VERSION ""

NS_ :

BS_:

BU_: PowertrainControlModule AtmosphericSensor SafetyRestraintSystem2 Aftertreatment_2_GasOutlet Aftertreatment_2_GasIntake DieselParticulateFilterControl Turbocharger SafetyRestraintSystem1 CabDisplay2 Aftertreatment_1_GasOutlet Aftertreatment_1_GasIntake OnBoardDataLogger OffBoardDiagnosticTool2 OffBoardDiagnosticTool1 FileServer ParkingBrakeController SeatController2 FanDriveController SteeringColumnUnit CommunicationUnitRadio CommunicationUnitSatellite CommunicationUnitCellular PropulsionBatteryCharger ChassisController2 ChassisController1 EngineValveControl AuxiliaryHeater2 AuxiliaryHeater1 ClutchUnit RampControl InformationSystem1 SuspensionSystemController2 OilSensor VehicleDynamicStability ExhaustEmissionController TransmissionDisplay2 TransmissionDisplay1 ClimateControl2 WaterPumpController RearAxleSteeringController LightingOperatorControl SeatController1 IgnitionController2 IgnitionController1 TirePressureController CabController2 CabController1 PneumaticSystemController SuspensionSystemController1 HydraulicPumpController EnduranceBrakingSystem RetarderExhaustEngine2 OnBoardDiagnosticUnit HeadwayController RetarderExhaustEngine1 CabDisplay1 ManagementComputer VirtualTerminal OffVehicleGateway PowerTakeOffFront HitchControl AuxiliaryValveControl BodyController TractorTrailerBridge1 StarterSystem ElectricalSystem VehicleSecurity VehicleNavigation AerodynamicControl ElectricalChargingSystem ClimateControl1 TripRecorder InstrumentCluster SuspensionDriveAxle2 SuspensionDriveAxle1 SuspensionSteerAxle SteeringController FuelSystem CruiseControl RetarderDriveline RetarderEngine BrakesDriveAxle2 BrakesDriveAxle1 BrakesSystemController BrakesSteerAxle AxleDrive2 AxleDrive1 AxleSteering PowerTakeOff ShiftConsoleSecondary ShiftConsolePrimary Transmission2 Transmission1 Engine2 Engine1
VAL_TABLE_ FMI 22 "Data Drifted Low" 21 "Data Drifted High" 20 "Received Network Data In Error" 0 "Above normal (most severe)" 1 "Below normal (most severe)" 2 "Data erratic" 3 "Voltage above normal" 4 "Voltage below normal" 5 "Current below normal" 6 "Current above normal" 7 "Mechanical system not responding" 8 "Abnormal frequency" 9 "Abnormal update rate" 10 "Abnormal rate of change" 11 "Root cause not known" 12 "Bad intelligent device" 13 "Out of calibration" 14 "Special intstructions" 15 "Above normal (least severe)" 16 "Above normal (moderately severe)" 17 "Below normal (least severe)" 18 "Below normal (moderately severe)" 19 "Received network data in error" 31 "Condition Exists" ;
VAL_TABLE_ TireLocation_MUX 51 "TirePress_33_MUX_51" 50 "TirePress_32_MUX_50" 49 "TirePress_31_MUX_49" 48 "TirePress_30_MUX_48" 35 "TirePress_23_MUX_35" 34 "TirePress_22_MUX_34" 33 "TirePress_21_MUX_33" 32 "TirePress_20_MUX_32" 19 "TirePress_13_MUX_19" 18 "TirePress_12_MUX_18" 17 "TirePress_11_MUX_17" 16 "TirePress_10_MUX_16" 1 "TirePress_01_MUX_1" 0 "TirePress_00_MUX_0" ;

BO_ 3221225472 VECTOR__INDEPENDENT_SIG_MSG: 0 Vector__XXX
 SG_ NumberOfMembersInWorkingSet : 0|8@1+ (1,0) [0|0] "" Vector__XXX
 SG_ SourceAddress : 0|8@1+ (1,0) [0|0] "" Vector__XXX
 SG_ NncntnuslyMonitoredSystemsStatus : 0|16@1+ (1,0) [0|0] "" Vector__XXX
 SG_ NncntnslyMonitoredSystemsSupport : 0|16@1+ (1,0) [0|0] "" Vector__XXX
 SG_ CntnslyMntrdSystmsSupport_Status : 0|8@1+ (1,0) [0|0] "" Vector__XXX
 SG_ AETCTorqueValue : 0|16@1+ (1,0) [0|64255] "Nm" Vector__XXX
 SG_ TrailerWeight : 0|16@1+ (2,0) [0|128510] "kg" Vector__XXX
 SG_ ReferenceTirePressSetting : 0|8@1+ (8,0) [0|2000] "kPa" Vector__XXX
 SG_ ReferenceTirePress : 0|8@1+ (8,0) [0|2000] "kPa" Vector__XXX
 SG_ TirePressThresholdDetection : 0|3@1+ (1,0) [0|7] "" Vector__XXX
 SG_ TireAirLeakageRate : 0|16@1+ (0.1,0) [0|6425.5] "Pa/s" Vector__XXX
 SG_ CTIWheelEndElectricalFault : 0|2@1+ (1,0) [0|3] "" Vector__XXX
 SG_ CTITireStatus : 0|2@1+ (1,0) [0|3] "" Vector__XXX
 SG_ CTIWheelSensorStatus : 0|2@1+ (1,0) [0|3] "" Vector__XXX
 SG_ TireTemp : 0|16@1+ (0.03125,-273) [-273|1734.96875] "deg C" Vector__XXX
 SG_ TirePress : 0|8@1+ (4,0) [0|1000] "kPa" Vector__XXX
 SG_ EngTurningGearEngaged : 0|2@1+ (1,0) [0|3] "" Vector__XXX
 SG_ AETCSpeedValue : 0|16@1+ (0.125,0) [0|8031.875] "rpm" Vector__XXX
 SG_ TimeBetweenRegens : 0|16@1+ (6,0) [0|385530] "s" Vector__XXX
 SG_ ActiveAccumulationTime : 0|16@1+ (6,0) [0|385530] "s" Vector__XXX
 SG_ RegenSt : 0|4@1+ (1,0) [0|15] "" Vector__XXX
 SG_ RegenStatus : 0|2@1+ (1,0) [0|3] "" Vector__XXX
 SG_ HtrSt : 0|2@1+ (1,0) [0|3] "" Vector__XXX
 SG_ Res : 0|16@1+ (1,0) [0|62500] "kohm" Vector__XXX
 SG_ HtrRes : 0|16@1+ (0.1,0) [0|6425.5] "ohm" Vector__XXX
 SG_ MaxRes : 0|16@1+ (250,0) [0|62500] "kohm" Vector__XXX
 SG_ Temp : 0|16@1+ (0.03125,-273) [-273|1734.96875] "°C" Vector__XXX
 SG_ RegenFailedCount : 0|8@1+ (1,0) [0|250] "" Vector__XXX
 SG_ PwrSupply : 0|2@1+ (1,0) [0|3] "" Vector__XXX
 SG_ DetectionStatus : 0|4@1+ (1,0) [0|15] "" Vector__XXX
 SG_ SCRSysAvgDistBetweenCleanEvents : 0|32@1+ (0.125,0) [0|526385151.875] "km" Vector__XXX
 SG_ SCRSysAvgTimeBetweenCleanEvents : 0|32@1+ (1,0) [0|4211081215] "s" Vector__XXX
 SG_ SCRSysTotalSysCleanManReq : 0|32@1+ (1,0) [0|4211081215] "" Vector__XXX
 SG_ SCRSysTotalSysCleanInhReq : 0|32@1+ (1,0) [0|4211081215] "" Vector__XXX
 SG_ SCRSysTotalSysCleanEvents : 0|32@1+ (1,0) [0|4211081215] "" Vector__XXX
 SG_ SCRSysTotalCleanTime : 0|32@1+ (1,0) [0|4211081215] "s" Vector__XXX
 SG_ HtrPwrSupplyDiagnosticStatus : 0|3@1+ (1,0) [0|7] "" Vector__XXX
 SG_ HtrPwrSupplyPreliminaryFMI : 0|5@1+ (1,0) [0|31] "" Vector__XXX
 SG_ PwrSupplyDiagnosticStatus : 0|3@1+ (1,0) [0|7] "" Vector__XXX
 SG_ PwrSupplyPreliminaryFMI : 0|5@1+ (1,0) [0|31] "" Vector__XXX
 SG_ InputDiagnosticStatus : 0|3@1+ (1,0) [0|7] "" Vector__XXX
 SG_ InputPreliminaryFMI : 0|5@1+ (1,0) [0|31] "" Vector__XXX
 SG_ HtrLowSideDriverDiagnosticStatus : 0|3@1+ (1,0) [0|7] "" Vector__XXX
 SG_ HtrLowSideDriverPreliminaryFMI : 0|5@1+ (1,0) [0|31] "" Vector__XXX
 SG_ HtrHiSideDriverDiagnosticStatus : 0|3@1+ (1,0) [0|7] "" Vector__XXX
 SG_ HtrHiSideDriverPreliminaryFMI : 0|5@1+ (1,0) [0|31] "" Vector__XXX
 SG_ ExhVelocity : 0|16@1+ (0.00390625,0) [0|250.996] "km/h" Vector__XXX
 SG_ ExhTemp : 0|16@1+ (0.03125,-273) [-273|1734.96875] "°C" Vector__XXX
 SG_ Dewpoint : 0|2@1+ (1,0) [0|3] "" Vector__XXX
 SG_ RegenReq : 0|2@1+ (1,0) [0|3] "" Vector__XXX
 SG_ ShutdownReq : 0|2@1+ (1,0) [0|3] "" Vector__XXX
 SG_ RqToPermitDEFDosingTestInjection : 0|3@1+ (1,0) [0|7] "" Vector__XXX
 SG_ RqToPermitDEFHydStiffnessCheck : 0|2@1+ (1,0) [0|3] "" Vector__XXX
 SG_ ThermalManagementInhReq : 0|2@1+ (1,0) [0|3] "" Vector__XXX
 SG_ DesulfationStatus : 0|2@1+ (1,0) [0|3] "" Vector__XXX
 SG_ RegenStatus : 0|2@1+ (1,0) [0|3] "" Vector__XXX
 SG_ SCRSysAvgDistBetweenCleanEvents : 0|32@1+ (0.125,0) [0|526385151.875] "km" Vector__XXX
 SG_ SCRSysAvgTimeBetweenCleanEvents : 0|32@1+ (1,0) [0|4211081215] "s" Vector__XXX
 SG_ SCRSysTotalSysCleanManReq : 0|32@1+ (1,0) [0|4211081215] "" Vector__XXX
 SG_ SCRSysTotalSysCleanInhReq : 0|32@1+ (1,0) [0|4211081215] "" Vector__XXX
 SG_ SCRSysTotalSysCleanEvents : 0|32@1+ (1,0) [0|4211081215] "" Vector__XXX
 SG_ SCRSysTotalSysCleanTime : 0|32@1+ (1,0) [0|4211081215] "s" Vector__XXX
 SG_ Ctrl2Temp : 0|8@1+ (1,-40) [-40|210] "°C" Vector__XXX
 SG_ CtrlTemp : 0|8@1+ (1,-40) [-40|210] "°C" Vector__XXX
 SG_ Htr2 : 0|8@1+ (0.4,0) [0|100] "%" Vector__XXX
 SG_ Temp2 : 0|8@1+ (1,-40) [-40|210] "°C" Vector__XXX
 SG_ Volume2 : 0|8@1+ (0.4,0) [0|100] "%" Vector__XXX
 SG_ FusedOutput29 : 0|2@1+ (1,0) [0|3] "" Vector__XXX
 SG_ FusedOutput30 : 0|2@1+ (1,0) [0|3] "" Vector__XXX
 SG_ FusedOutput31 : 0|2@1+ (1,0) [0|3] "" Vector__XXX
 SG_ FusedOutput32 : 0|2@1+ (1,0) [0|3] "" Vector__XXX
 SG_ FusedOutput25 : 0|2@1+ (1,0) [0|3] "" Vector__XXX
 SG_ FusedOutput26 : 0|2@1+ (1,0) [0|3] "" Vector__XXX
 SG_ FusedOutput27 : 0|2@1+ (1,0) [0|3] "" Vector__XXX
 SG_ FusedOutput28 : 0|2@1+ (1,0) [0|3] "" Vector__XXX
 SG_ FusedOutput21 : 0|2@1+ (1,0) [0|3] "" Vector__XXX
 SG_ FusedOutput22 : 0|2@1+ (1,0) [0|3] "" Vector__XXX
 SG_ FusedOutput23 : 0|2@1+ (1,0) [0|3] "" Vector__XXX
 SG_ FusedOutput24 : 0|2@1+ (1,0) [0|3] "" Vector__XXX
 SG_ FusedOutput17 : 0|2@1+ (1,0) [0|3] "" Vector__XXX
 SG_ FusedOutput18 : 0|2@1+ (1,0) [0|3] "" Vector__XXX
 SG_ FusedOutput19 : 0|2@1+ (1,0) [0|3] "" Vector__XXX
 SG_ FusedOutput20 : 0|2@1+ (1,0) [0|3] "" Vector__XXX
 SG_ FusedOutput13 : 0|2@1+ (1,0) [0|3] "" Vector__XXX
 SG_ FusedOutput14 : 0|2@1+ (1,0) [0|3] "" Vector__XXX
 SG_ FusedOutput15 : 0|2@1+ (1,0) [0|3] "" Vector__XXX
 SG_ FusedOutput16 : 0|2@1+ (1,0) [0|3] "" Vector__XXX
 SG_ FusedOutput9 : 0|2@1+ (1,0) [0|3] "" Vector__XXX
 SG_ FusedOutput10 : 0|2@1+ (1,0) [0|3] "" Vector__XXX
 SG_ FusedOutput11 : 0|2@1+ (1,0) [0|3] "" Vector__XXX
 SG_ FusedOutput12 : 0|2@1+ (1,0) [0|3] "" Vector__XXX
 SG_ FusedOutput5 : 0|2@1+ (1,0) [0|3] "" Vector__XXX
 SG_ FusedOutput6 : 0|2@1+ (1,0) [0|3] "" Vector__XXX
 SG_ FusedOutput7 : 0|2@1+ (1,0) [0|3] "" Vector__XXX
 SG_ FusedOutput8 : 0|2@1+ (1,0) [0|3] "" Vector__XXX
 SG_ FusedOutput1 : 0|2@1+ (1,0) [0|3] "" Vector__XXX
 SG_ FusedOutput2 : 0|2@1+ (1,0) [0|3] "" Vector__XXX
 SG_ FusedOutput3 : 0|2@1+ (1,0) [0|3] "" Vector__XXX
 SG_ FusedOutput4 : 0|2@1+ (1,0) [0|3] "" Vector__XXX
 SG_ SwitchedOutput29 : 0|2@1+ (1,0) [0|3] "" Vector__XXX
 SG_ SwitchedOutput30 : 0|2@1+ (1,0) [0|3] "" Vector__XXX
 SG_ SwitchedOutput31 : 0|2@1+ (1,0) [0|3] "" Vector__XXX
 SG_ SwitchedOutput32 : 0|2@1+ (1,0) [0|3] "" Vector__XXX
 SG_ SwitchedOutput25 : 0|2@1+ (1,0) [0|3] "" Vector__XXX
 SG_ SwitchedOutput26 : 0|2@1+ (1,0) [0|3] "" Vector__XXX
 SG_ SwitchedOutput27 : 0|2@1+ (1,0) [0|3] "" Vector__XXX
 SG_ SwitchedOutput28 : 0|2@1+ (1,0) [0|3] "" Vector__XXX
 SG_ SwitchedOutput21 : 0|2@1+ (1,0) [0|3] "" Vector__XXX
 SG_ SwitchedOutput22 : 0|2@1+ (1,0) [0|3] "" Vector__XXX
 SG_ SwitchedOutput23 : 0|2@1+ (1,0) [0|3] "" Vector__XXX
 SG_ SwitchedOutput24 : 0|2@1+ (1,0) [0|3] "" Vector__XXX
 SG_ SwitchedOutput17 : 0|2@1+ (1,0) [0|3] "" Vector__XXX
 SG_ SwitchedOutput18 : 0|2@1+ (1,0) [0|3] "" Vector__XXX
 SG_ SwitchedOutput19 : 0|2@1+ (1,0) [0|3] "" Vector__XXX
 SG_ SwitchedOutput20 : 0|2@1+ (1,0) [0|3] "" Vector__XXX
 SG_ SwitchedOutput13 : 0|2@1+ (1,0) [0|3] "" Vector__XXX
 SG_ SwitchedOutput14 : 0|2@1+ (1,0) [0|3] "" Vector__XXX
 SG_ SwitchedOutput15 : 0|2@1+ (1,0) [0|3] "" Vector__XXX
 SG_ SwitchedOutput16 : 0|2@1+ (1,0) [0|3] "" Vector__XXX
 SG_ SwitchedOutput9 : 0|2@1+ (1,0) [0|3] "" Vector__XXX
 SG_ SwitchedOutput10 : 0|2@1+ (1,0) [0|3] "" Vector__XXX
 SG_ SwitchedOutput11 : 0|2@1+ (1,0) [0|3] "" Vector__XXX
 SG_ SwitchedOutput12 : 0|2@1+ (1,0) [0|3] "" Vector__XXX
 SG_ SwitchedOutput5 : 0|2@1+ (1,0) [0|3] "" Vector__XXX
 SG_ SwitchedOutput6 : 0|2@1+ (1,0) [0|3] "" Vector__XXX
 SG_ SwitchedOutput7 : 0|2@1+ (1,0) [0|3] "" Vector__XXX
 SG_ SwitchedOutput8 : 0|2@1+ (1,0) [0|3] "" Vector__XXX
 SG_ SwitchedOutput1 : 0|2@1+ (1,0) [0|3] "" Vector__XXX
 SG_ SwitchedOutput2 : 0|2@1+ (1,0) [0|3] "" Vector__XXX
 SG_ SwitchedOutput3 : 0|2@1+ (1,0) [0|3] "" Vector__XXX
 SG_ SwitchedOutput4 : 0|2@1+ (1,0) [0|3] "" Vector__XXX
 SG_ SwitchedPowerOutput18Cmd : 0|2@1+ (1,0) [0|3] "" Vector__XXX
 SG_ SwitchedPowerOutput19Cmd : 0|2@1+ (1,0) [0|3] "" Vector__XXX
 SG_ SwitchedPowerOutput20Cmd : 0|2@1+ (1,0) [0|3] "" Vector__XXX
 SG_ SwitchedPowerOutput13Cmd : 0|2@1+ (1,0) [0|3] "" Vector__XXX
 SG_ SwitchedPowerOutput14Cmd : 0|2@1+ (1,0) [0|3] "" Vector__XXX
 SG_ SwitchedPowerOutput15Cmd : 0|2@1+ (1,0) [0|3] "" Vector__XXX
 SG_ SwitchedPowerOutput16Cmd : 0|2@1+ (1,0) [0|3] "" Vector__XXX
 SG_ SwitchedPowerOutput9Cmd : 0|2@1+ (1,0) [0|3] "" Vector__XXX
 SG_ SwitchedPowerOutput10Cmd : 0|2@1+ (1,0) [0|3] "" Vector__XXX
 SG_ SwitchedPowerOutput29Cmd : 0|2@1+ (1,0) [0|3] "" Vector__XXX
 SG_ SwitchedPowerOutput30Cmd : 0|2@1+ (1,0) [0|3] "" Vector__XXX
 SG_ SwitchedPowerOutput31Cmd : 0|2@1+ (1,0) [0|3] "" Vector__XXX
 SG_ SwitchedPowerOutput32Cmd : 0|2@1+ (1,0) [0|3] "" Vector__XXX
 SG_ SwitchedPowerOutput25Cmd : 0|2@1+ (1,0) [0|3] "" Vector__XXX
 SG_ SwitchedPowerOutput26Cmd : 0|2@1+ (1,0) [0|3] "" Vector__XXX
 SG_ SwitchedPowerOutput27Cmd : 0|2@1+ (1,0) [0|3] "" Vector__XXX
 SG_ SwitchedPowerOutput28Cmd : 0|2@1+ (1,0) [0|3] "" Vector__XXX
 SG_ SwitchedPowerOutput21Cmd : 0|2@1+ (1,0) [0|3] "" Vector__XXX
 SG_ SwitchedPowerOutput22Cmd : 0|2@1+ (1,0) [0|3] "" Vector__XXX
 SG_ SwitchedPowerOutput23Cmd : 0|2@1+ (1,0) [0|3] "" Vector__XXX
 SG_ SwitchedPowerOutput24Cmd : 0|2@1+ (1,0) [0|3] "" Vector__XXX
 SG_ SwitchedPowerOutput17Cmd : 0|2@1+ (1,0) [0|3] "" Vector__XXX
 SG_ SwitchedPowerOutput11Cmd : 0|2@1+ (1,0) [0|3] "" Vector__XXX
 SG_ SwitchedPowerOutput12Cmd : 0|2@1+ (1,0) [0|3] "" Vector__XXX
 SG_ SwitchedPowerOutput5Cmd : 0|2@1+ (1,0) [0|3] "" Vector__XXX
 SG_ SwitchedPowerOutput6Cmd : 0|2@1+ (1,0) [0|3] "" Vector__XXX
 SG_ SwitchedPowerOutput7Cmd : 0|2@1+ (1,0) [0|3] "" Vector__XXX
 SG_ SwitchedPowerOutput8Cmd : 0|2@1+ (1,0) [0|3] "" Vector__XXX
 SG_ SwitchedPowerOutput1Cmd : 0|2@1+ (1,0) [0|3] "" Vector__XXX
 SG_ SwitchedPowerOutput2Cmd : 0|2@1+ (1,0) [0|3] "" Vector__XXX
 SG_ SwitchedPowerOutput3Cmd : 0|2@1+ (1,0) [0|3] "" Vector__XXX
 SG_ SwitchedPowerOutput4Cmd : 0|2@1+ (1,0) [0|3] "" Vector__XXX
 SG_ SpecialIgnitorLoop90Resistance : 0|16@1+ (0.1,0) [0|6425.5] "ohm" Vector__XXX
 SG_ SpecialIgnitorLoop89Resistance : 0|16@1+ (0.1,0) [0|6425.5] "ohm" Vector__XXX
 SG_ SpecialIgnitorLoop88Resistance : 0|16@1+ (0.1,0) [0|6425.5] "ohm" Vector__XXX
 SG_ SpecialIgnitorLoop87Resistance : 0|16@1+ (0.1,0) [0|6425.5] "ohm" Vector__XXX
 SG_ SpecialIgnitorLoop86Resistance : 0|16@1+ (0.1,0) [0|6425.5] "ohm" Vector__XXX
 SG_ SpecialIgnitorLoop85Resistance : 0|16@1+ (0.1,0) [0|6425.5] "ohm" Vector__XXX
 SG_ SpecialIgnitorLoop84Resistance : 0|16@1+ (0.1,0) [0|6425.5] "ohm" Vector__XXX
 SG_ SpecialIgnitorLoop83Resistance : 0|16@1+ (0.1,0) [0|6425.5] "ohm" Vector__XXX
 SG_ SpecialIgnitorLoop82Resistance : 0|16@1+ (0.1,0) [0|6425.5] "ohm" Vector__XXX
 SG_ SpecialIgnitorLoop81Resistance : 0|16@1+ (0.1,0) [0|6425.5] "ohm" Vector__XXX
 SG_ SpecialIgnitorLoop80Resistance : 0|16@1+ (0.1,0) [0|6425.5] "ohm" Vector__XXX
 SG_ SpecialIgnitorLoop79Resistance : 0|16@1+ (0.1,0) [0|6425.5] "ohm" Vector__XXX
 SG_ SpecialIgnitorLoop78Resistance : 0|16@1+ (0.1,0) [0|6425.5] "ohm" Vector__XXX
 SG_ SpecialIgnitorLoop77Resistance : 0|16@1+ (0.1,0) [0|6425.5] "ohm" Vector__XXX
 SG_ SpecialIgnitorLoop76Resistance : 0|16@1+ (0.1,0) [0|6425.5] "ohm" Vector__XXX
 SG_ SpecialIgnitorLoop75Resistance : 0|16@1+ (0.1,0) [0|6425.5] "ohm" Vector__XXX
 SG_ SpecialIgnitorLoop74Resistance : 0|16@1+ (0.1,0) [0|6425.5] "ohm" Vector__XXX
 SG_ SpecialIgnitorLoop73Resistance : 0|16@1+ (0.1,0) [0|6425.5] "ohm" Vector__XXX
 SG_ SpecialIgnitorLoop72Resistance : 0|16@1+ (0.1,0) [0|6425.5] "ohm" Vector__XXX
 SG_ SpecialIgnitorLoop71Resistance : 0|16@1+ (0.1,0) [0|6425.5] "ohm" Vector__XXX
 SG_ SpecialIgnitorLoop70Resistance : 0|16@1+ (0.1,0) [0|6425.5] "ohm" Vector__XXX
 SG_ SpecialIgnitorLoop69Resistance : 0|16@1+ (0.1,0) [0|6425.5] "ohm" Vector__XXX
 SG_ SpecialIgnitorLoop68Resistance : 0|16@1+ (0.1,0) [0|6425.5] "ohm" Vector__XXX
 SG_ SpecialIgnitorLoop67Resistance : 0|16@1+ (0.1,0) [0|6425.5] "ohm" Vector__XXX
 SG_ SpecialIgnitorLoop66Resistance : 0|16@1+ (0.1,0) [0|6425.5] "ohm" Vector__XXX
 SG_ SpecialIgnitorLoop65Resistance : 0|16@1+ (0.1,0) [0|6425.5] "ohm" Vector__XXX
 SG_ SpecialIgnitorLoop64Resistance : 0|16@1+ (0.1,0) [0|6425.5] "ohm" Vector__XXX
 SG_ SpecialIgnitorLoop63Resistance : 0|16@1+ (0.1,0) [0|6425.5] "ohm" Vector__XXX
 SG_ SpecialIgnitorLoop62Resistance : 0|16@1+ (0.1,0) [0|6425.5] "ohm" Vector__XXX
 SG_ SpecialIgnitorLoop61Resistance : 0|16@1+ (0.1,0) [0|6425.5] "ohm" Vector__XXX
 SG_ SpecialIgnitorLoop60Resistance : 0|16@1+ (0.1,0) [0|6425.5] "ohm" Vector__XXX
 SG_ SpecialIgnitorLoop59Resistance : 0|16@1+ (0.1,0) [0|6425.5] "ohm" Vector__XXX
 SG_ SpecialIgnitorLoop58Resistance : 0|16@1+ (0.1,0) [0|6425.5] "ohm" Vector__XXX
 SG_ SpecialIgnitorLoop57Resistance : 0|16@1+ (0.1,0) [0|6425.5] "ohm" Vector__XXX
 SG_ SpecialIgnitorLoop56Resistance : 0|16@1+ (0.1,0) [0|6425.5] "ohm" Vector__XXX
 SG_ SpecialIgnitorLoop55Resistance : 0|16@1+ (0.1,0) [0|6425.5] "ohm" Vector__XXX
 SG_ SpecialIgnitorLoop54Resistance : 0|16@1+ (0.1,0) [0|6425.5] "ohm" Vector__XXX
 SG_ SpecialIgnitorLoop53Resistance : 0|16@1+ (0.1,0) [0|6425.5] "ohm" Vector__XXX
 SG_ SpecialIgnitorLoop52Resistance : 0|16@1+ (0.1,0) [0|6425.5] "ohm" Vector__XXX
 SG_ SpecialIgnitorLoop51Resistance : 0|16@1+ (0.1,0) [0|6425.5] "ohm" Vector__XXX
 SG_ SpecialIgnitorLoop50Resistance : 0|16@1+ (0.1,0) [0|6425.5] "ohm" Vector__XXX
 SG_ SpecialIgnitorLoop49Resistance : 0|16@1+ (0.1,0) [0|6425.5] "ohm" Vector__XXX
 SG_ SpecialIgnitorLoop48Resistance : 0|16@1+ (0.1,0) [0|6425.5] "ohm" Vector__XXX
 SG_ SpecialIgnitorLoop47Resistance : 0|16@1+ (0.1,0) [0|6425.5] "ohm" Vector__XXX
 SG_ SpecialIgnitorLoop46Resistance : 0|16@1+ (0.1,0) [0|6425.5] "ohm" Vector__XXX
 SG_ SpecialIgnitorLoop45Resistance : 0|16@1+ (0.1,0) [0|6425.5] "ohm" Vector__XXX
 SG_ SpecialIgnitorLoop44Resistance : 0|16@1+ (0.1,0) [0|6425.5] "ohm" Vector__XXX
 SG_ SpecialIgnitorLoop43Resistance : 0|16@1+ (0.1,0) [0|6425.5] "ohm" Vector__XXX
 SG_ SpecialIgnitorLoop42Resistance : 0|16@1+ (0.1,0) [0|6425.5] "ohm" Vector__XXX
 SG_ SpecialIgnitorLoop41Resistance : 0|16@1+ (0.1,0) [0|6425.5] "ohm" Vector__XXX
 SG_ SpecialIgnitorLoop40Resistance : 0|16@1+ (0.1,0) [0|6425.5] "ohm" Vector__XXX
 SG_ SpecialIgnitorLoop39Resistance : 0|16@1+ (0.1,0) [0|6425.5] "ohm" Vector__XXX
 SG_ SpecialIgnitorLoop38Resistance : 0|16@1+ (0.1,0) [0|6425.5] "ohm" Vector__XXX
 SG_ SpecialIgnitorLoop37Resistance : 0|16@1+ (0.1,0) [0|6425.5] "ohm" Vector__XXX
 SG_ SpecialIgnitorLoop36Resistance : 0|16@1+ (0.1,0) [0|6425.5] "ohm" Vector__XXX
 SG_ SpecialIgnitorLoop35Resistance : 0|16@1+ (0.1,0) [0|6425.5] "ohm" Vector__XXX
 SG_ SpecialIgnitorLoop34Resistance : 0|16@1+ (0.1,0) [0|6425.5] "ohm" Vector__XXX
 SG_ SpecialIgnitorLoop33Resistance : 0|16@1+ (0.1,0) [0|6425.5] "ohm" Vector__XXX
 SG_ SpecialIgnitorLoop32Resistance : 0|16@1+ (0.1,0) [0|6425.5] "ohm" Vector__XXX
 SG_ SpecialIgnitorLoop31Resistance : 0|16@1+ (0.1,0) [0|6425.5] "ohm" Vector__XXX
 SG_ SpecialIgnitorLoop30Resistance : 0|16@1+ (0.1,0) [0|6425.5] "ohm" Vector__XXX
 SG_ SpecialIgnitorLoop29Resistance : 0|16@1+ (0.1,0) [0|6425.5] "ohm" Vector__XXX
 SG_ SpecialIgnitorLoop28Resistance : 0|16@1+ (0.1,0) [0|6425.5] "ohm" Vector__XXX
 SG_ SpecialIgnitorLoop27Resistance : 0|16@1+ (0.1,0) [0|6425.5] "ohm" Vector__XXX
 SG_ SpecialIgnitorLoop26Resistance : 0|16@1+ (0.1,0) [0|6425.5] "ohm" Vector__XXX
 SG_ SpecialIgnitorLoop25Resistance : 0|16@1+ (0.1,0) [0|6425.5] "ohm" Vector__XXX
 SG_ SpecialIgnitorLoop24Resistance : 0|16@1+ (0.1,0) [0|6425.5] "ohm" Vector__XXX
 SG_ SpecialIgnitorLoop23Resistance : 0|16@1+ (0.1,0) [0|6425.5] "ohm" Vector__XXX
 SG_ SpecialIgnitorLoop22Resistance : 0|16@1+ (0.1,0) [0|6425.5] "ohm" Vector__XXX
 SG_ SpecialIgnitorLoop21Resistance : 0|16@1+ (0.1,0) [0|6425.5] "ohm" Vector__XXX
 SG_ SpecialIgnitorLoop20Resistance : 0|16@1+ (0.1,0) [0|6425.5] "ohm" Vector__XXX
 SG_ SpecialIgnitorLoop19Resistance : 0|16@1+ (0.1,0) [0|6425.5] "ohm" Vector__XXX
 SG_ SpecialIgnitorLoop18Resistance : 0|16@1+ (0.1,0) [0|6425.5] "ohm" Vector__XXX
 SG_ SpecialIgnitorLoop17Resistance : 0|16@1+ (0.1,0) [0|6425.5] "ohm" Vector__XXX
 SG_ SpecialIgnitorLoop16Resistance : 0|16@1+ (0.1,0) [0|6425.5] "ohm" Vector__XXX
 SG_ SpecialIgnitorLoop15Resistance : 0|16@1+ (0.1,0) [0|6425.5] "ohm" Vector__XXX
 SG_ SpecialIgnitorLoop14Resistance : 0|16@1+ (0.1,0) [0|6425.5] "ohm" Vector__XXX
 SG_ SpecialIgnitorLoop13Resistance : 0|16@1+ (0.1,0) [0|6425.5] "ohm" Vector__XXX
 SG_ SpecialIgnitorLoop12Resistance : 0|16@1+ (0.1,0) [0|6425.5] "ohm" Vector__XXX
 SG_ SpecialIgnitorLoop11Resistance : 0|16@1+ (0.1,0) [0|6425.5] "ohm" Vector__XXX
 SG_ SpecialIgnitorLoop10Resistance : 0|16@1+ (0.1,0) [0|6425.5] "ohm" Vector__XXX
 SG_ SpecialIgnitorLoop9Resistance : 0|16@1+ (0.1,0) [0|6425.5] "ohm" Vector__XXX
 SG_ SpecialIgnitorLoop8Resistance : 0|16@1+ (0.1,0) [0|6425.5] "ohm" Vector__XXX
 SG_ SpecialIgnitorLoop7Resistance : 0|16@1+ (0.1,0) [0|6425.5] "ohm" Vector__XXX
 SG_ SpecialIgnitorLoop6Resistance : 0|16@1+ (0.1,0) [0|6425.5] "ohm" Vector__XXX
 SG_ SpecialIgnitorLoop5Resistance : 0|16@1+ (0.1,0) [0|6425.5] "ohm" Vector__XXX
 SG_ SpecialIgnitorLoop4Resistance : 0|16@1+ (0.1,0) [0|6425.5] "ohm" Vector__XXX
 SG_ SpecialIgnitorLoop3Resistance : 0|16@1+ (0.1,0) [0|6425.5] "ohm" Vector__XXX
 SG_ SpecialIgnitorLoop2Resistance : 0|16@1+ (0.1,0) [0|6425.5] "ohm" Vector__XXX
 SG_ SpecialIgnitorLoop1Resistance : 0|16@1+ (0.1,0) [0|6425.5] "ohm" Vector__XXX
 SG_ SdBagIgnitorLoop2RightResistance : 0|16@1+ (0.1,0) [0|6425.5] "ohm" Vector__XXX
 SG_ SdBagIgnitorLoop1RightResistance : 0|16@1+ (0.1,0) [0|6425.5] "ohm" Vector__XXX
 SG_ SdeBagIgnitorLoop2LeftResistance : 0|16@1+ (0.1,0) [0|6425.5] "ohm" Vector__XXX
 SG_ SdeBagIgnitorLoop1LeftResistance : 0|16@1+ (0.1,0) [0|6425.5] "ohm" Vector__XXX
 SG_ PssngrBltTnsnrIgntrLopResistance : 0|16@1+ (0.1,0) [0|6425.5] "ohm" Vector__XXX
 SG_ DrvrBltTnsnrIgntorLoopResistance : 0|16@1+ (0.1,0) [0|6425.5] "ohm" Vector__XXX
 SG_ PssngrArbgIgntrLp2ndStgRsistance : 0|16@1+ (0.1,0) [0|6425.5] "ohm" Vector__XXX
 SG_ DrvrArbgIgntrLp2ndStgeResistance : 0|16@1+ (0.1,0) [0|6425.5] "ohm" Vector__XXX
 SG_ PssngrArbgIgntrLp1stStgRsistance : 0|16@1+ (0.1,0) [0|6425.5] "ohm" Vector__XXX
 SG_ DrvrArbgIgntrLp1stStgeResistance : 0|16@1+ (0.1,0) [0|6425.5] "ohm" Vector__XXX
 SG_ EngTorqueLimit6AxleInput : 0|16@1+ (2,0) [0|128510] "Nm" Vector__XXX
 SG_ EngTorqueLimit5Switch : 0|16@1+ (1,0) [0|64255] "Nm" Vector__XXX
 SG_ EngTorqueLimit4Trans : 0|16@1+ (1,0) [0|64255] "Nm" Vector__XXX
 SG_ EngTorqueLimit3Trans : 0|16@1+ (1,0) [0|64255] "Nm" Vector__XXX
 SG_ TransGearRatio3 : 0|16@1+ (0.01,0) [0|642.55] "" Vector__XXX
 SG_ EngTorqueLimit2Trans : 0|16@1+ (1,0) [0|64255] "Nm" Vector__XXX
 SG_ TransGearRatio2 : 0|16@1+ (0.01,0) [0|642.55] "" Vector__XXX
 SG_ EngTorqueLimit1Trans : 0|16@1+ (1,0) [0|64255] "Nm" Vector__XXX
 SG_ TransGearRatio1 : 0|16@1+ (0.01,0) [0|642.55] "" Vector__XXX
 SG_ EngTorqueLimitFeature : 0|3@1+ (1,0) [0|7] "" Vector__XXX
 SG_ TorqueLimitingFeatureStatus : 0|2@1+ (1,0) [0|3] "" Vector__XXX
 SG_ CalibRecordDurationTime : 0|32@1+ (0.05,0) [0|210554060.75] "h" Vector__XXX
 SG_ CalibRecordStartYear : 0|8@1+ (1,1985) [1985|2235] "years" Vector__XXX
 SG_ CalibRecordStartDay : 0|8@1+ (0.25,0) [0.25|31.75] "days" Vector__XXX
 SG_ CalibRecordStartMonth : 0|8@1+ (1,0) [1|12] "months" Vector__XXX
 SG_ EngPeakTorque2 : 0|16@1+ (1,0) [0|64255] "Nm" Vector__XXX
 SG_ EngPeakTorque1 : 0|16@1+ (1,0) [0|64255] "Nm" Vector__XXX
 SG_ EngPower : 0|16@1+ (0.5,0) [0|32127.5] "kW" Vector__XXX
 SG_ NumberOfEngTorqueHistoryRecords : 0|8@1+ (1,0) [0|250] "records" Vector__XXX
 SG_ RolloverSensorType : 0|4@1+ (1,0) [0|15] "" Vector__XXX
 SG_ RearCollisionSensor4Type : 0|4@1+ (1,0) [0|15] "" Vector__XXX
 SG_ RearCollisionSensor3Type : 0|4@1+ (1,0) [0|15] "" Vector__XXX
 SG_ RearCollisionSensor2Type : 0|4@1+ (1,0) [0|15] "" Vector__XXX
 SG_ RearCollisionSensor1Type : 0|4@1+ (1,0) [0|15] "" Vector__XXX
 SG_ SideCollisionSensorRearRightType : 0|4@1+ (1,0) [0|15] "" Vector__XXX
 SG_ SdCllisionSensorMidRearRightType : 0|4@1+ (1,0) [0|15] "" Vector__XXX
 SG_ SdCllsionSensorMidFrontRightType : 0|4@1+ (1,0) [0|15] "" Vector__XXX
 SG_ SdeCollisionSensorFrontRightType : 0|4@1+ (1,0) [0|15] "" Vector__XXX
 SG_ SideCollisionSensorRearLeftType : 0|4@1+ (1,0) [0|15] "" Vector__XXX
 SG_ SdCollisionSensorMidRearLeftType : 0|4@1+ (1,0) [0|15] "" Vector__XXX
 SG_ SdCllisionSensorMidFrontLeftType : 0|4@1+ (1,0) [0|15] "" Vector__XXX
 SG_ SideCollisionSensorFrontLeftType : 0|4@1+ (1,0) [0|15] "" Vector__XXX
 SG_ FrontalCollisionSensor4Type : 0|4@1+ (1,0) [0|15] "" Vector__XXX
 SG_ FrontalCollisionSensor3Type : 0|4@1+ (1,0) [0|15] "" Vector__XXX
 SG_ FrontalCollisionSensor2Type : 0|4@1+ (1,0) [0|15] "" Vector__XXX
 SG_ FrontalCollisionSensor1Type : 0|4@1+ (1,0) [0|15] "" Vector__XXX
 SG_ DPFAvgDistBetweenActiveRegens : 0|32@1+ (0.125,0) [0|526385151.875] "km" Vector__XXX
 SG_ DPFAvgTimeBetweenActiveRegens : 0|32@1+ (1,0) [0|4211081215] "s" Vector__XXX
 SG_ DPFTotalNumOfActiveRegenManReq : 0|32@1+ (1,0) [0|4211081215] "" Vector__XXX
 SG_ DPFTotalNumOfActiveRegenInhReq : 0|32@1+ (1,0) [0|4211081215] "" Vector__XXX
 SG_ DPFTotalNumOfPassiveRegens : 0|32@1+ (1,0) [0|4211081215] "" Vector__XXX
 SG_ DPFTotalPassiveRegenTime : 0|32@1+ (1,0) [0|4211081215] "s" Vector__XXX
 SG_ TotalNumOfActiveRegens : 0|32@1+ (1,0) [0|4211081215] "" Vector__XXX
 SG_ TotalDisdTime : 0|32@1+ (1,0) [0|4211081215] "s" Vector__XXX
 SG_ TotalRegenTime : 0|32@1+ (1,0) [0|4211081215] "s" Vector__XXX
 SG_ TotalFuelUsed : 0|32@1+ (0.5,0) [0|2105540607.5] "L" Vector__XXX
 SG_ DPFAvgDistBetweenActiveRegens : 0|32@1+ (0.125,0) [0|526385151.875] "km" Vector__XXX
 SG_ DPFAvgTimeBetweenActiveRegens : 0|32@1+ (1,0) [0|4211081215] "s" Vector__XXX
 SG_ DPFTotalNumOfActiveRegenManReq : 0|32@1+ (1,0) [0|4211081215] "" Vector__XXX
 SG_ DPFTotalNumOfActiveRegenInhReq : 0|32@1+ (1,0) [0|4211081215] "" Vector__XXX
 SG_ DPFTotalNumOfPassiveRegens : 0|32@1+ (1,0) [0|4211081215] "" Vector__XXX
 SG_ DPFTotalPassiveRegenTime : 0|32@1+ (1,0) [0|4211081215] "s" Vector__XXX
 SG_ TotalNumOfActiveRegens : 0|32@1+ (1,0) [0|4211081215] "" Vector__XXX
 SG_ TotalDisdTime : 0|32@1+ (1,0) [0|4211081215] "s" Vector__XXX
 SG_ TotalRegenTime : 0|32@1+ (1,0) [0|4211081215] "s" Vector__XXX
 SG_ TotalFuelUsed : 0|32@1+ (0.5,0) [0|2105540607.5] "L" Vector__XXX

BO_ 2566658558 PLST1: 8 Vector__XXX
 SG_ TotalHaulCycleCount : 32|32@1+ (1,0) [0|4211081215] "" Vector__XXX
 SG_ TotalDeliveredPayloadWeight : 0|32@1+ (100,0) [0|421108121500] "kg" Vector__XXX

BO_ 2566658302 PLST2: 8 Vector__XXX
 SG_ TotalPayloadTransactionCount : 0|32@1+ (1,0) [0|4211081215] "" Vector__XXX

BO_ 2499549182 PLT1: 8 Vector__XXX

BO_ 2499548926 PLT2: 8 Vector__XXX

BO_ 2499548670 VEP6: 8 Vector__XXX

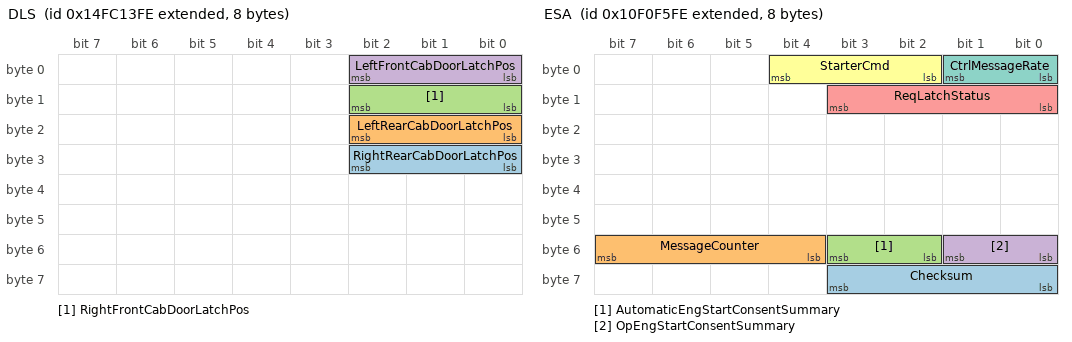
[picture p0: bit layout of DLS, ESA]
BO_ 2499548158 DLS: 8 Vector__XXX
 SG_ RightRearCabDoorLatchPos : 24|3@1+ (1,0) [0|7] "" Vector__XXX
 SG_ LeftRearCabDoorLatchPos : 16|3@1+ (1,0) [0|7] "" Vector__XXX
 SG_ RightFrontCabDoorLatchPos : 8|3@1+ (1,0) [0|7] "" Vector__XXX
 SG_ LeftFrontCabDoorLatchPos : 0|3@1+ (1,0) [0|7] "" Vector__XXX

BO_ 2499547902 CDC: 8 Vector__XXX
 SG_ MirrorRight2HeatCmd : 54|2@1+ (1,0) [0|3] "" Vector__XXX
 SG_ MirrorLeft2HeatCmd : 52|2@1+ (1,0) [0|3] "" Vector__XXX
 SG_ MirrorRight1HeatCmd : 50|2@1+ (1,0) [0|3] "" Vector__XXX
 SG_ MirrorLeft1HeatCmd : 48|2@1+ (1,0) [0|3] "" Vector__XXX
 SG_ MirrorRight2VerticalCmd : 46|2@1+ (1,0) [0|3] "" Vector__XXX
 SG_ MirrorRight2HorizontalCmd : 44|2@1+ (1,0) [0|3] "" Vector__XXX
 SG_ MirrorLeft2VerticalCmd : 42|2@1+ (1,0) [0|3] "" Vector__XXX
 SG_ MirrorLeft2HorizontalCmd : 40|2@1+ (1,0) [0|3] "" Vector__XXX
 SG_ MirrorRight1VerticalCmd : 38|2@1+ (1,0) [0|3] "" Vector__XXX
 SG_ MirrorRight1HorizontalCmd : 36|2@1+ (1,0) [0|3] "" Vector__XXX
 SG_ MirrorLeft1VerticalCmd : 34|2@1+ (1,0) [0|3] "" Vector__XXX
 SG_ MirrorLeft1HorizontalCmd : 32|2@1+ (1,0) [0|3] "" Vector__XXX
 SG_ RightRearWindowPosCmd : 27|3@1+ (1,0) [0|7] "" Vector__XXX
 SG_ LeftRearWindowPosCmd : 24|3@1+ (1,0) [0|7] "" Vector__XXX
 SG_ RightFrontWindowPosCmd : 19|3@1+ (1,0) [0|7] "" Vector__XXX
 SG_ LeftFrontWindowPosCmd : 16|3@1+ (1,0) [0|7] "" Vector__XXX
 SG_ RemoteCabDoorLockReq : 8|3@1+ (1,0) [0|7] "" Vector__XXX
 SG_ DoorsLockActCmd : 0|3@1+ (1,0) [0|7] "" Vector__XXX

BO_ 2566656510 TGFI: 8 Vector__XXX
 SG_ EngTotalGasIdleFuelVolumeUsed : 32|32@1+ (0.5,0) [0|2105540607.5] "m³" Vector__XXX
 SG_ EngTotalGasFuelVolumeUsed : 0|32@1+ (0.5,0) [0|2105540607.5] "m³" Vector__XXX

BO_ 2565929214 ADASIS3: 8 Vector__XXX

BO_ 2565928958 ADASIS2: 8 Vector__XXX

BO_ 2565928702 ADASIS1: 8 Vector__XXX

BO_ 2431710718 ESA: 8 Vector__XXX
 SG_ Checksum : 56|4@1+ (1,0) [0|15] "" Vector__XXX
 SG_ MessageCounter : 52|4@1+ (1,0) [0|15] "" Vector__XXX
 SG_ AutomaticEngStartConsentSummary : 50|2@1+ (1,0) [0|3] "" Vector__XXX
 SG_ OpEngStartConsentSummary : 48|2@1+ (1,0) [0|3] "" Vector__XXX
 SG_ ReqLatchStatus : 8|4@1+ (1,0) [0|15] "" Vector__XXX
 SG_ StarterCmd : 2|3@1+ (1,0) [0|7] "" Vector__XXX
 SG_ CtrlMessageRate : 0|2@1+ (1,0) [0|3] "" Vector__XXX

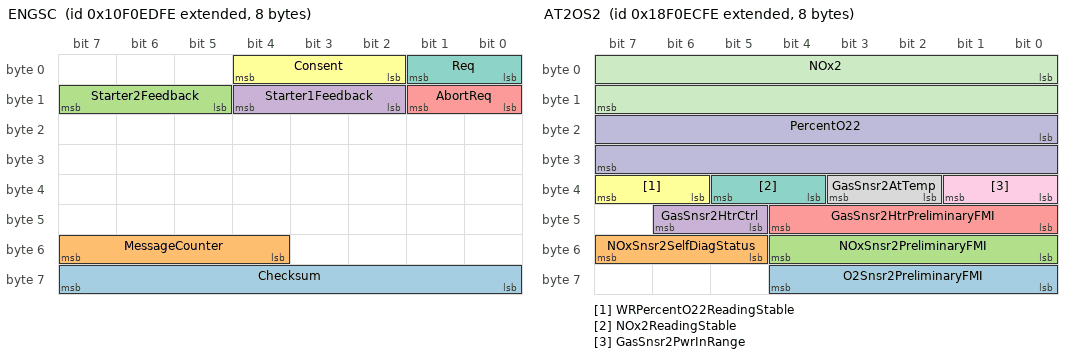
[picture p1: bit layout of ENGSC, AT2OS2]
BO_ 2431708670 ENGSC: 8 Vector__XXX
 SG_ Checksum : 56|8@1+ (1,0) [0|255] "" Vector__XXX
 SG_ MessageCounter : 52|4@1+ (1,0) [0|15] "" Vector__XXX
 SG_ Starter2Feedback : 13|3@1+ (1,0) [0|7] "" Vector__XXX
 SG_ Starter1Feedback : 10|3@1+ (1,0) [0|7] "" Vector__XXX
 SG_ AbortReq : 8|2@1+ (1,0) [0|3] "" Vector__XXX
 SG_ Consent : 2|3@1+ (1,0) [0|7] "" Vector__XXX
 SG_ Req : 0|2@1+ (1,0) [0|3] "" Vector__XXX

BO_ 2566661118 LFC2: 8 Vector__XXX
 SG_ EngTotalDieselFuelDemand : 0|32@1+ (0.5,0) [0|2105540607.5] "L" Vector__XXX

BO_ 2633769726 EEC19: 8 Vector__XXX
 SG_ TotalEngEnergy : 0|32@1+ (1,0) [0|4211081215] "kWh" Vector__XXX

BO_ 2565926142 AT2OS2: 8 Vector__XXX
 SG_ O2Snsr2PreliminaryFMI : 56|5@1+ (1,0) [0|31] "" Vector__XXX
 SG_ NOxSnsr2SelfDiagStatus : 53|3@1+ (1,0) [0|7] "" Vector__XXX
 SG_ NOxSnsr2PreliminaryFMI : 48|5@1+ (1,0) [0|31] "" Vector__XXX
 SG_ GasSnsr2HtrCtrl : 45|2@1+ (1,0) [0|3] "" Vector__XXX
 SG_ GasSnsr2HtrPreliminaryFMI : 40|5@1+ (1,0) [0|31] "" Vector__XXX
 SG_ WRPercentO22ReadingStable : 38|2@1+ (1,0) [0|3] "" Vector__XXX
 SG_ NOx2ReadingStable : 36|2@1+ (1,0) [0|3] "" Vector__XXX
 SG_ GasSnsr2AtTemp : 34|2@1+ (1,0) [0|3] "" Vector__XXX
 SG_ GasSnsr2PwrInRange : 32|2@1+ (1,0) [0|3] "" Vector__XXX
 SG_ PercentO22 : 16|16@1+ (0.000514,-12) [-12|21.02707] "%" Vector__XXX
 SG_ NOx2 : 0|16@1+ (0.05,-200) [-200|3012.75] "ppm" Vector__XXX

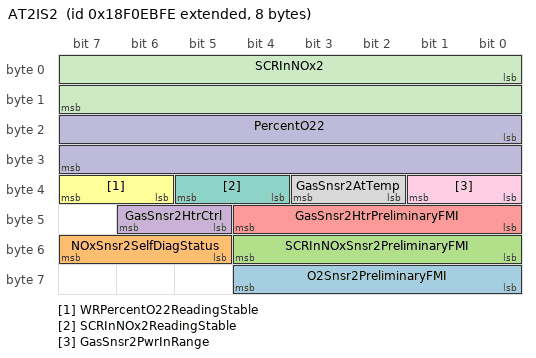
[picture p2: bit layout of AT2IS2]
BO_ 2565925886 AT2IS2: 8 Vector__XXX
 SG_ O2Snsr2PreliminaryFMI : 56|5@1+ (1,0) [0|31] "" Vector__XXX
 SG_ NOxSnsr2SelfDiagStatus : 53|3@1+ (1,0) [0|7] "" Vector__XXX
 SG_ SCRInNOxSnsr2PreliminaryFMI : 48|5@1+ (1,0) [0|31] "" Vector__XXX
 SG_ GasSnsr2HtrCtrl : 45|2@1+ (1,0) [0|3] "" Vector__XXX
 SG_ GasSnsr2HtrPreliminaryFMI : 40|5@1+ (1,0) [0|31] "" Vector__XXX
 SG_ WRPercentO22ReadingStable : 38|2@1+ (1,0) [0|3] "" Vector__XXX
 SG_ SCRInNOx2ReadingStable : 36|2@1+ (1,0) [0|3] "" Vector__XXX
 SG_ GasSnsr2AtTemp : 34|2@1+ (1,0) [0|3] "" Vector__XXX
 SG_ GasSnsr2PwrInRange : 32|2@1+ (1,0) [0|3] "" Vector__XXX
 SG_ PercentO22 : 16|16@1+ (0.000514,-12) [-12|21.02707] "%" Vector__XXX
 SG_ SCRInNOx2 : 0|16@1+ (0.05,-200) [-200|3012.75] "ppm" Vector__XXX

CM_ BU_ PowertrainControlModule "Electronic control module in charge of controlling and coordinating the operation of a hybrid propulsion system.";
CM_ BU_ HitchControl "Straight truck hitch (NOT Agricultural hitch – it is in IG 2) ";
CM_ BO_ 3221225472 "This is a message for not used signals, created by Vector CANdb++ DBC OLE DB Provider.";
CM_ SG_ 3221225472 NumberOfMembersInWorkingSet "The number of members in a particular Working Set.";
CM_ SG_ 3221225472 SourceAddress "Instance of a Source Address listed a Network Message data field.";
CM_ SG_ 3221225472 NncntnuslyMonitoredSystemsStatus "Identifies the non-continuously monitored systems status. Each bit identifies whether a particular test is complete for a given controller.
";
CM_ SG_ 3221225472 NncntnslyMonitoredSystemsSupport "Identifies the non-continuously monitored systems support.
";
CM_ SG_ 3221225472 CntnslyMntrdSystmsSupport_Status "Identifies the continuously monitored system support and status.
";
CM_ SG_ 3221225472 AETCTorqueValue "Engine torque value of the data points in PGN 64912 – Advertised Engine Torque Curve (AETC).";
CM_ SG_ 3221225472 TrailerWeight "Total mass of freight-carrying vehicle designed to be pulled by truck, including the weight of the contents.";
CM_ SG_ 3221225472 ReferenceTirePressSetting "Reference value of the tire pressure setting as basis for the tire pressure monitoring ...";
CM_ SG_ 3221225472 ReferenceTirePress "Reference value of the tire pressure as basis for the tire pressure monitoring ...";
CM_ SG_ 3221225472 TirePressThresholdDetection "Signal indicating the pressure level of the tire.  The levels defined represent different pressure conditions of the tire: 000 Extreme over pressure - The tire pressure is at a level where the safety of the vehicle may be jeopardised.";
CM_ SG_ 3221225472 TireAirLeakageRate "The pressure loss rate of a tire.";
CM_ SG_ 3221225472 CTIWheelEndElectricalFault "Indicates the status of electrical fault on CTI wheel interface.";
CM_ SG_ 3221225472 CTITireStatus "Indicates the status of the tire.";
CM_ SG_ 3221225472 CTIWheelSensorStatus "Indicates whether the wheel is being monitored by the CTI controller.";
CM_ SG_ 3221225472 TireTemp "Temperature at the surface of the tire sidewall.";
CM_ SG_ 3221225472 TirePress "Pressure at which air is contained in cavity formed by tire and rim.";
CM_ SG_ 3221225472 EngTurningGearEngaged "Status signal which indicates that the turning gear is engaged.  The turning gear is used to turn the flywheel/crankshaft, ...";
CM_ SG_ 3221225472 AETCSpeedValue "Engine speed value of the data points in PGN 64912 – Advertised Engine Torque Curve (AETC).";
CM_ SG_ 3221225472 TimeBetweenRegens "This is the time between the last two successful regenerations of the particulate sensor for the current power cycle. This parameter reflects the time when the engine was running, not a duration based on a real time clock. If two successful ...";
CM_ SG_ 3221225472 ActiveAccumulationTime "This is the amount of time since the last successful regeneration completed.  The sensor has been accumulating particulate matter since that time.";
CM_ SG_ 3221225472 RegenSt "Indicates if the particulate sensor regeneration is currently active, and if so, the reason for the regeneration.
0000 - Regeneration is not active
0001 - Regneration is active and has been initiated by request via SPN 6783
0010 - Regeneration is ...";
CM_ SG_ 3221225472 RegenStatus "The status of the most recent attempt of this power cycle to activate the particulate sensor regeneration process. This will not be updated until the regeneration is no longer active, as indicated by SPN 6774.
Power cycle refers to the time that ...Indicates whether the NOx adsorber regeneration in the second aftertreatment system is active or inactive

00  Inactive
01  Active
10  Error indicator
11  Not available";
CM_ SG_ 3221225472 HtrSt "The states of the particulate sensor heater.  The heater will change states from 11 to 10, 10 to 01, and 01 to 00 in a typical heating event.
00 - Heater is in closed loop control
01 - Heater is being held at a specified level
10 - Heater is in ...";
CM_ SG_ 3221225472 Res "This sensor is located in the exhaust stream somewhere after the DPF, but not necessarily immediately after the DPF.  It provides a resistance value that can be used to determine particulate matter in the exhaust stream. The value in this parameter ...";
CM_ SG_ 3221225472 HtrRes "The resistance of the particulate sensor heater.";
CM_ SG_ 3221225472 MaxRes "This is the maximum resistance that the particulate sensor can measure.";
CM_ SG_ 3221225472 Temp "Temperature of the particulate sensor.";
CM_ SG_ 3221225472 RegenFailedCount "This is the number of times that the particulate sensor regeneration process has been attempted but failed to complete this power cycle.";
CM_ SG_ 3221225472 PwrSupply "State signal which indicates when the Aftertreatment 1 particulate sensor has power applied to it. Note that this is referring to the power supplied to the sensor, not the power supplied to the controller connected to the sensor.
00 - Off
01 - On
 ...";
CM_ SG_ 3221225472 DetectionStatus "Detection status of the particulate sensor
0000 - Initialization for particulate matter detection
0001 - Waiting for dew point (see SPN 6784)
0010 - Particulate matter detection
0011 - Heater is active for particulate sensor regeneration
0100 - ...";
CM_ SG_ 3221225472 SCRSysAvgDistBetweenCleanEvents "Indicates the average distance since last reset between cleaning events for the SCR system in bank 1.

If the manufacturer allows this parameter to be reset, this distance is the average since last reset.";
CM_ SG_ 3221225472 SCRSysAvgTimeBetweenCleanEvents "Indicates the average time since last reset between cleaning events for the SCR system in bank 1.
 
If the manufacturer allows this parameter to be reset, this time is the average since last reset.";
CM_ SG_ 3221225472 SCRSysTotalSysCleanManReq "Total number of manual cleaning requests on the SCR system in bank 1 by the operator over the lifetime of the device.";
CM_ SG_ 3221225472 SCRSysTotalSysCleanInhReq "Total number of cleaning inhibit requests on the SCR system in bank 1 by the operator over the lifetime of the device.";
CM_ SG_ 3221225472 SCRSysTotalSysCleanEvents "Total number of cleaning events that have occurred on the SCR system in bank 1 over the lifetime of the device.";
CM_ SG_ 3221225472 SCRSysTotalCleanTime "Total amount of time that a cleaning event has been active in the SCR system in bank 1 over the lifetime of the device.";
CM_ SG_ 3221225472 HtrPwrSupplyDiagnosticStatus "The value of this parameter is not retained when power is removed from the particulate sensor.
000 - Tests monitored continuously. There are no enable or pause conditions. See Aftertreatment 1 Particulate Sensor Heater Power Supply Preliminary FMI ...";
CM_ SG_ 3221225472 HtrPwrSupplyPreliminaryFMI "Used to identify the applicable J1939-73 FMI detected in the aftertreatment particulate sensor heater power supply by the manufacturer’s sensor control software in exhaust bank 1. When there is no failure FMI 31 is sent. In the case of multiple ...";
CM_ SG_ 3221225472 PwrSupplyDiagnosticStatus "The value of this parameter is not retained when power is removed from the particulate sensor.
000 - Tests monitored continuously. There are no enable or pause conditions. See Aftertreatment 1 Particulate Sensor Power Supply Preliminary FMI (SPN ...";
CM_ SG_ 3221225472 PwrSupplyPreliminaryFMI "Used to identify the applicable J1939-73 FMI detected in the aftertreatment particulate sensor power supply by the manufacturer’s sensor control software in exhaust bank 1. When there is no failure FMI 31 is sent. In the case of multiple failures ...";
CM_ SG_ 3221225472 InputDiagnosticStatus "The value of this parameter is not retained when power is removed from the particulate sensor.
000 - Tests monitored continuously. There are no enable or pause conditions. See Aftertreatment 1 Particulate Sensor Input Preliminary FMI (SPN 7325) for ...";
CM_ SG_ 3221225472 InputPreliminaryFMI "Used to identify the applicable J1939-73 FMI detected in the aftertreatment particulate sensor input by the manufacturer’s sensor control software in exhaust bank 1. When there is no failure FMI 31 is sent. In the case of multiple failures the most ...";
CM_ SG_ 3221225472 HtrLowSideDriverDiagnosticStatus "The value of this parameter is not retained when power is removed from the particulate sensor.
000 - Tests monitored continuously. There are no enable or pause conditions. See Aftertreatment 1 Particulate Sensor Heater Low Side Driver Preliminary ...";
CM_ SG_ 3221225472 HtrLowSideDriverPreliminaryFMI "Used to identify the applicable J1939-73 FMI detected in the aftertreatment particulate sensor heater high side driver by the manufacturer’s sensor control software in exhaust bank 1. When there is no failure FMI 31 is sent. In the case of multiple ...";
CM_ SG_ 3221225472 HtrHiSideDriverDiagnosticStatus "The value of this parameter is not retained when power is removed from the particulate sensor.
000 - Tests monitored continuously. There are no enable or pause conditions. See Aftertreatment 1 Particulate Sensor Heater High Side Driver Preliminary ...";
CM_ SG_ 3221225472 HtrHiSideDriverPreliminaryFMI "Used to identify the applicable J1939-73 FMI detected in the aftertreatment particulate sensor heater high side driver by the manufacturer’s sensor control software in exhaust bank 1. When there is no failure FMI 31 is sent. In the case of multiple ...";
CM_ SG_ 3221225472 ExhVelocity "Velocity of the exhaust gas near the particulate sensor.";
CM_ SG_ 3221225472 ExhTemp "This is the temperature in the exhaust stream that is closest to the particulate sensor. This could be a calculated value or read from another sensor. The ECU transmitting this message to the particulate sensor controller will be aware of the ...";
CM_ SG_ 3221225472 Dewpoint "Indicates that the temperature near the particulate sensor has exceeded the dew point.

00 - Dewpoint has not been reached
01 - Dewpoint has been reached
10 - SAE reserved
11 - Not available";
CM_ SG_ 3221225472 RegenReq "Another ECU would send this to request that the particulate sensor perform a regeneration of the sensor.  A request would be considered active when this parameter transitions from 00 to 01.
00 - Regeneration not requested
01 - Regeneration ...";
CM_ SG_ 3221225472 ShutdownReq "Aftertreatment 1 particulate sensor shutdown request.

00 - Shutdown request not active
01 - Shutdown request active
10 - SAE reserved
11 - Not available";
CM_ SG_ 3221225472 RqToPermitDEFDosingTestInjection "A request to permit the DEF dosing test injection. The request continues to be broadcast until the test injection is finished or the corresponding permission status indicates an error.
000 = no request
001 = request to permit DEF Dosing Test ...";
CM_ SG_ 3221225472 RqToPermitDEFHydStiffnessCheck "A request to permit the DEF hydraulic stiffness check. The request continues to be broadcast until the stiffness check is finished or the corresponding permission status indicates an error.
00 = no request
01 = request to permit DEF hydraulic ...";
CM_ SG_ 3221225472 ThermalManagementInhReq "Provides state of inhibit request for Aftertreatment thermal management from external system.
Aftertreatment Thermal Management indicates that the exhaust temperatures have been controlled for expected functioning of the aftertreatment system - ...";
CM_ SG_ 3221225472 DesulfationStatus "Indicates whether the NOx adsorber desulfation regeneration in the second aftertreatment system is active or inactive

00  Inactive
01  Active
10  Error indicator
11  Not available";
CM_ SG_ 3221225472 SCRSysAvgDistBetweenCleanEvents "Indicates the average distance since last reset between cleaning events for the SCR system in bank 2.

If the manufacturer allows this parameter to be reset, this distance is the average since last reset.";
CM_ SG_ 3221225472 SCRSysAvgTimeBetweenCleanEvents "Indicates the average time since last reset between cleaning events for the SCR system in bank 2.

If the manufacturer allows this parameter to be reset, this time is the average since last reset.";
CM_ SG_ 3221225472 SCRSysTotalSysCleanManReq "Total number of manual cleaning requests on the SCR system in bank 2 by the operator over the lifetime of the device.";
CM_ SG_ 3221225472 SCRSysTotalSysCleanInhReq "Total number of cleaning inhibit requests on the SCR system in bank 2 by the operator over the lifetime of the device.";
CM_ SG_ 3221225472 SCRSysTotalSysCleanEvents "Total number of cleaning events that have occurred on the SCR system in bank 2 over the lifetime of the device.";
CM_ SG_ 3221225472 SCRSysTotalSysCleanTime "Total amount of time that a cleaning event has been active in the SCR system in bank 2 over the lifetime of the device.";
CM_ SG_ 3221225472 Ctrl2Temp "Temperature of the diesel exhaust fluid at the aftertreatment 2 diesel exhaust fluid controller 2.";
CM_ SG_ 3221225472 CtrlTemp "Temperature of the diesel exhaust fluid at the aftertreatment 2 diesel exhaust fluid controller.";
CM_ SG_ 3221225472 Htr2 "Percentage of heating applied to the second diesel exhaust fluid tank heater on aftertreatment 2. A value of 0% means no heating applied, a value of 100% means full heating applied. The diesel exhaust fluid tank heater warms the diesel exhaust fluid ...";
CM_ SG_ 3221225472 Temp2 "The second temperature of aftertreatment 2 diesel exhaust fluid in the storage tank.";
CM_ SG_ 3221225472 Volume2 "Second measurement of the ratio of volume of diesel exhaust fluid to the total volume of the diesel exhaust fluid storage container for aftertreatment system 2 (exhaust bank 2).  0% is empty and 100% is full.  See SPN 4426 and SPN 4428 for alternate ...";
CM_ SG_ 3221225472 FusedOutput29 "State of Fused Output #29. Used to indicate the output state.

00 - Output not powered
01 - Output powered
10 - Reserved
11 - Take no action";
CM_ SG_ 3221225472 FusedOutput30 "State of Fused Output #30. Used to indicate the output state.

00 - Output not powered
01 - Output powered
10 - Reserved
11 - Take no action";
CM_ SG_ 3221225472 FusedOutput31 "State of Fused Output #31. Used to indicate the output state.

00 - Output not powered
01 - Output powered
10 - Reserved
11 - Take no action";
CM_ SG_ 3221225472 FusedOutput32 "State of Fused Output #32. Used to indicate the output state.

00 - Output not powered
01 - Output powered
10 - Reserved
11 - Take no action";
CM_ SG_ 3221225472 FusedOutput25 "State of Fused Output #25. Used to indicate the output state.

00 - Output not powered
01 - Output powered
10 - Reserved
11 - Take no action";
CM_ SG_ 3221225472 FusedOutput26 "State of Fused Output #26. Used to indicate the output state.

00 - Output not powered
01 - Output powered
10 - Reserved
11 - Take no action";
CM_ SG_ 3221225472 FusedOutput27 "State of Fused Output #27. Used to indicate the output state.

00 - Output not powered
01 - Output powered
10 - Reserved
11 - Take no action";
CM_ SG_ 3221225472 FusedOutput28 "State of Fused Output #28. Used to indicate the output state.

00 - Output not powered
01 - Output powered
10 - Reserved
11 - Take no action";
CM_ SG_ 3221225472 FusedOutput21 "State of Fused Output #21. Used to indicate the output state.

00 - Output not powered
01 - Output powered
10 - Reserved
11 - Take no action";
CM_ SG_ 3221225472 FusedOutput22 "State of Fused Output #22. Used to indicate the output state.

00 - Output not powered
01 - Output powered
10 - Reserved
11 - Take no action";
CM_ SG_ 3221225472 FusedOutput23 "State of Fused Output #23. Used to indicate the output state.

00 - Output not powered
01 - Output powered
10 - Reserved
11 - Take no action";
CM_ SG_ 3221225472 FusedOutput24 "State of Fused Output #24. Used to indicate the output state.

00 - Output not powered
01 - Output powered
10 - Reserved
11 - Take no action";
CM_ SG_ 3221225472 FusedOutput17 "State of Fused Output #17. Used to indicate the output state.

00 - Output not powered
01 - Output powered
10 - Reserved
11 - Take no action";
CM_ SG_ 3221225472 FusedOutput18 "State of Fused Output #18. Used to indicate the output state.

00 - Output not powered
01 - Output powered
10 - Reserved
11 - Take no action";
CM_ SG_ 3221225472 FusedOutput19 "State of Fused Output #19. Used to indicate the output state.

00 - Output not powered
01 - Output powered
10 - Reserved
11 - Take no action";
CM_ SG_ 3221225472 FusedOutput20 "State of Fused Output #20. Used to indicate the output state.

00 - Output not powered
01 - Output powered
10 - Reserved
11 - Take no action";
CM_ SG_ 3221225472 FusedOutput13 "State of Fused Output #13. Used to indicate the output state.

00 - Output not powered
01 - Output powered
10 - Reserved
11 - Take no action";
CM_ SG_ 3221225472 FusedOutput14 "State of Fused Output #14. Used to indicate the output state.

00 - Output not powered
01 - Output powered
10 - Reserved
11 - Take no action";
CM_ SG_ 3221225472 FusedOutput15 "State of Fused Output #15. Used to indicate the output state.

00 - Output not powered
01 - Output powered
10 - Reserved
11 - Take no action";
CM_ SG_ 3221225472 FusedOutput16 "State of Fused Output #16. Used to indicate the output state.

00 - Output not powered
01 - Output powered
10 - Reserved
11 - Take no action";
CM_ SG_ 3221225472 FusedOutput9 "State of Fused Output #9. Used to indicate the output state.

00 - Output not powered
01 - Output powered
10 - Reserved
11 - Take no action";
CM_ SG_ 3221225472 FusedOutput10 "State of Fused Output #10. Used to indicate the output state.

00 - Output not powered
01 - Output powered
10 - Reserved
11 - Take no action";
CM_ SG_ 3221225472 FusedOutput11 "State of Fused Output #11. Used to indicate the output state.

00 - Output not powered
01 - Output powered
10 - Reserved
11 - Take no action";
CM_ SG_ 3221225472 FusedOutput12 "State of Fused Output #12. Used to indicate the output state.

00 - Output not powered
01 - Output powered
10 - Reserved
11 - Take no action";
CM_ SG_ 3221225472 FusedOutput5 "State of Fused Output #5. Used to indicate the output state.

00 - Output not powered
01 - Output powered
10 - Reserved
11 - Take no action";
CM_ SG_ 3221225472 FusedOutput6 "State of Fused Output #6. Used to indicate the output state.

00 - Output not powered
01 - Output powered
10 - Reserved
11 - Take no action";
CM_ SG_ 3221225472 FusedOutput7 "State of Fused Output #7. Used to indicate the output state.

00 - Output not powered
01 - Output powered
10 - Reserved
11 - Take no action";
CM_ SG_ 3221225472 FusedOutput8 "State of Fused Output #8. Used to indicate the output state.

00 - Output not powered
01 - Output powered
10 - Reserved
11 - Take no action";
CM_ SG_ 3221225472 FusedOutput1 "State of Fused Output #1. Used to indicate the output state.

00 - Output not powered
01 - Output powered
10 - Reserved
11 - Take no action";
CM_ SG_ 3221225472 FusedOutput2 "State of Fused Output #2. Used to indicate the output state.

00 - Output not powered
01 - Output powered
10 - Reserved
11 - Take no action";
CM_ SG_ 3221225472 FusedOutput3 "State of Fused Output #3. Used to indicate the output state.

00 - Output not powered
01 - Output powered
10 - Reserved
11 - Take no action";
CM_ SG_ 3221225472 FusedOutput4 "State of Fused Output #4. Used to indicate the output state.

00 - Output not powered
01 - Output powered
10 - Reserved
11 - Take no action";
CM_ SG_ 3221225472 SwitchedOutput29 "State of Switched Output #29. Used to indicate the output state.

00 - Output off
01 - Output on
10 - Reserved
11 - Take no action";
CM_ SG_ 3221225472 SwitchedOutput30 "State of Switched Output #30. Used to indicate the output state.

00 - Output off
01 - Output on
10 - Reserved
11 - Take no action";
CM_ SG_ 3221225472 SwitchedOutput31 "State of Switched Output #31. Used to indicate the output state.

00 - Output off
01 - Output on
10 - Reserved
11 - Take no action";
CM_ SG_ 3221225472 SwitchedOutput32 "State of Switched Output #32. Used to indicate the output state.

00 - Output off
01 - Output on
10 - Reserved
11 - Take no action";
CM_ SG_ 3221225472 SwitchedOutput25 "State of Switched Output #25. Used to indicate the output state.

00 - Output off
01 - Output on
10 - Reserved
11 - Take no action";
CM_ SG_ 3221225472 SwitchedOutput26 "State of Switched Output #26. Used to indicate the output state.

00 - Output off
01 - Output on
10 - Reserved
11 - Take no action";
CM_ SG_ 3221225472 SwitchedOutput27 "State of Switched Output #27. Used to indicate the output state.

00 - Output off
01 - Output on
10 - Reserved
11 - Take no action";
CM_ SG_ 3221225472 SwitchedOutput28 "State of Switched Output #28. Used to indicate the output state.

00 - Output off
01 - Output on
10 - Reserved
11 - Take no action";
CM_ SG_ 3221225472 SwitchedOutput21 "State of Switched Output #21. Used to indicate the output state.

00 - Output off
01 - Output on
10 - Reserved
11 - Take no action";
CM_ SG_ 3221225472 SwitchedOutput22 "State of Switched Output #22. Used to indicate the output state.

00 - Output off
01 - Output on
10 - Reserved
11 - Take no action";
CM_ SG_ 3221225472 SwitchedOutput23 "State of Switched Output #23. Used to indicate the output state.

00 - Output off
01 - Output on
10 - Reserved
11 - Take no action";
CM_ SG_ 3221225472 SwitchedOutput24 "State of Switched Output #24. Used to indicate the output state.

00 - Output off
01 - Output on
10 - Reserved
11 - Take no action";
CM_ SG_ 3221225472 SwitchedOutput17 "State of Switched Output #17. Used to indicate the output state.

00 - Output off
01 - Output on
10 - Reserved
11 - Take no action";
CM_ SG_ 3221225472 SwitchedOutput18 "State of Switched Output #18. Used to indicate the output state.

00 - Output off
01 - Output on
10 - Reserved
11 - Take no action";
CM_ SG_ 3221225472 SwitchedOutput19 "State of Switched Output #19. Used to indicate the output state.

00 - Output off
01 - Output on
10 - Reserved
11 - Take no action";
CM_ SG_ 3221225472 SwitchedOutput20 "State of Switched Output #20. Used to indicate the output state.

00 - Output off
01 - Output on
10 - Reserved
11 - Take no action";
CM_ SG_ 3221225472 SwitchedOutput13 "State of Switched Output #13. Used to indicate the output state.

00 - Output off
01 - Output on
10 - Reserved
11 - Take no action";
CM_ SG_ 3221225472 SwitchedOutput14 "State of Switched Output #14. Used to indicate the output state.

00 - Output off
01 - Output on
10 - Reserved
11 - Take no action";
CM_ SG_ 3221225472 SwitchedOutput15 "State of Switched Output #15. Used to indicate the output state.

00 - Output off
01 - Output on
10 - Reserved
11 - Take no action";
CM_ SG_ 3221225472 SwitchedOutput16 "State of Switched Output #16. Used to indicate the output state.

00 - Output off
01 - Output on
10 - Reserved
11 - Take no action";
CM_ SG_ 3221225472 SwitchedOutput9 "State of Switched Output #9. Used to indicate the output state.

00 - Output off
01 - Output on
10 - Reserved
11 - Take no action";
CM_ SG_ 3221225472 SwitchedOutput10 "State of Switched Output #10. Used to indicate the output state.

00 - Output off
01 - Output on
10 - Reserved
11 - Take no action";
CM_ SG_ 3221225472 SwitchedOutput11 "State of Switched Output #11. Used to indicate the output state.

00 - Output off
01 - Output on
10 - Reserved
11 - Take no action";
CM_ SG_ 3221225472 SwitchedOutput12 "State of Switched Output #12. Used to indicate the output state.

00 - Output off
01 - Output on
10 - Reserved
11 - Take no action";
CM_ SG_ 3221225472 SwitchedOutput5 "State of Switched Output #5. Used to indicate the output state.

00 - Output off
01 - Output on
10 - Reserved
11 - Take no action";
CM_ SG_ 3221225472 SwitchedOutput6 "State of Switched Output #6. Used to indicate the output state.

00 - Output off
01 - Output on
10 - Reserved
11 - Take no action";
CM_ SG_ 3221225472 SwitchedOutput7 "State of Switched Output #7. Used to indicate the output state.

00 - Output off
01 - Output on
10 - Reserved
11 - Take no action";
CM_ SG_ 3221225472 SwitchedOutput8 "State of Switched Output #8. Used to indicate the output state.

00 - Output off
01 - Output on
10 - Reserved
11 - Take no action";
CM_ SG_ 3221225472 SwitchedOutput1 "State of Switched Output #1. Used to indicate the output state.

00 - Output off
01 - Output on
10 - Reserved
11 - Take no action";
CM_ SG_ 3221225472 SwitchedOutput2 "State of Switched Output #2. Used to indicate the output state.

00 - Output off
01 - Output on
10 - Reserved
11 - Take no action";
CM_ SG_ 3221225472 SwitchedOutput3 "State of Switched Output #3. Used to indicate the output state.

00 - Output off
01 - Output on
10 - Reserved
11 - Take no action";
CM_ SG_ 3221225472 SwitchedOutput4 "State of Switched Output #4. Used to indicate the output state.

00 - Output off
01 - Output on
10 - Reserved
11 - Take no action";
CM_ SG_ 3221225472 SwitchedPowerOutput18Cmd "Desired state of Switched Power Output #18. Used to set the desired state.

00 - Output off
01 - Output on
10 - Reserved
11 - Take no action";
CM_ SG_ 3221225472 SwitchedPowerOutput19Cmd "Desired state of Switched Power Output #19. Used to set the desired state.

00 - Output off
01 - Output on
10 - Reserved
11 - Take no action";
CM_ SG_ 3221225472 SwitchedPowerOutput20Cmd "Desired state of Switched Power Output #20. Used to set the desired state.

00 - Output off
01 - Output on
10 - Reserved
11 - Take no action";
CM_ SG_ 3221225472 SwitchedPowerOutput13Cmd "Desired state of Switched Power Output #13. Used to set the desired state.

00 - Output off
01 - Output on
10 - Reserved
11 - Take no action";
CM_ SG_ 3221225472 SwitchedPowerOutput14Cmd "Desired state of Switched Power Output #14. Used to set the desired state.

00 - Output off
01 - Output on
10 - Reserved
11 - Take no action";
CM_ SG_ 3221225472 SwitchedPowerOutput15Cmd "Desired state of Switched Power Output #15. Used to set the desired state.

00 - Output off
01 - Output on
10 - Reserved
11 - Take no action";
CM_ SG_ 3221225472 SwitchedPowerOutput16Cmd "Desired state of Switched Power Output #16. Used to set the desired state.

00 - Output off
01 - Output on
10 - Reserved
11 - Take no action";
CM_ SG_ 3221225472 SwitchedPowerOutput9Cmd "Desired state of Switched Power Output #9. Used to set the desired state.

00 - Output off
01 - Output on
10 - Reserved
11 - Take no action";
CM_ SG_ 3221225472 SwitchedPowerOutput10Cmd "Desired state of Switched Power Output #10. Used to set the desired state.

00 - Output off
01 - Output on
10 - Reserved
11 - Take no action";
CM_ SG_ 3221225472 SwitchedPowerOutput29Cmd "Desired state of Switched Power Output #29. Used to set the desired state.

00 - Output off
01 - Output on
10 - Reserved
11 - Take no action";
CM_ SG_ 3221225472 SwitchedPowerOutput30Cmd "Desired state of Switched Power Output #30. Used to set the desired state.

00 - Output off
01 - Output on
10 - Reserved
11 - Take no action";
CM_ SG_ 3221225472 SwitchedPowerOutput31Cmd "Desired state of Switched Power Output #31. Used to set the desired state.

00 - Output off
01 - Output on
10 - Reserved
11 - Take no action";
CM_ SG_ 3221225472 SwitchedPowerOutput32Cmd "Desired state of Switched Power Output #32. Used to set the desired state.

00 - Output off
01 - Output on
10 - Reserved
11 - Take no action";
CM_ SG_ 3221225472 SwitchedPowerOutput25Cmd "Desired state of Switched Power Output #25. Used to set the desired state.

00 - Output off
01 - Output on
10 - Reserved
11 - Take no action";
CM_ SG_ 3221225472 SwitchedPowerOutput26Cmd "Desired state of Switched Power Output #26. Used to set the desired state.

00 - Output off
01 - Output on
10 - Reserved
11 - Take no action";
CM_ SG_ 3221225472 SwitchedPowerOutput27Cmd "Desired state of Switched Power Output #27. Used to set the desired state.

00 - Output off
01 - Output on
10 - Reserved
11 - Take no action";
CM_ SG_ 3221225472 SwitchedPowerOutput28Cmd "Desired state of Switched Power Output #28. Used to set the desired state.

00 - Output off
01 - Output on
10 - Reserved
11 - Take no action";
CM_ SG_ 3221225472 SwitchedPowerOutput21Cmd "Desired state of Switched Power Output #21. Used to set the desired state.

00 - Output off
01 - Output on
10 - Reserved
11 - Take no action";
CM_ SG_ 3221225472 SwitchedPowerOutput22Cmd "Desired state of Switched Power Output #22. Used to set the desired state.

00 - Output off
01 - Output on
10 - Reserved
11 - Take no action";
CM_ SG_ 3221225472 SwitchedPowerOutput23Cmd "Desired state of Switched Power Output #23. Used to set the desired state.

00 - Output off
01 - Output on
10 - Reserved
11 - Take no action";
CM_ SG_ 3221225472 SwitchedPowerOutput24Cmd "Desired state of Switched Power Output #24. Used to set the desired state.

00 - Output off
01 - Output on
10 - Reserved
11 - Take no action";
CM_ SG_ 3221225472 SwitchedPowerOutput17Cmd "Desired state of Switched Power Output #17. Used to set the desired state.

00 - Output off
01 - Output on
10 - Reserved
11 - Take no action";
CM_ SG_ 3221225472 SwitchedPowerOutput11Cmd "Desired state of Switched Power Output #11. Used to set the desired state.

00 - Output off
01 - Output on
10 - Reserved
11 - Take no action";
CM_ SG_ 3221225472 SwitchedPowerOutput12Cmd "Desired state of Switched Power Output #12. Used to set the desired state.

00 - Output off
01 - Output on
10 - Reserved
11 - Take no action";
CM_ SG_ 3221225472 SwitchedPowerOutput5Cmd "Desired state of Switched Power Output #5. Used to set the desired state.

00 - Output off
01 - Output on
10 - Reserved
11 - Take no action";
CM_ SG_ 3221225472 SwitchedPowerOutput6Cmd "Desired state of Switched Power Output #6. Used to set the desired state.

00 - Output off
01 - Output on
10 - Reserved
11 - Take no action";
CM_ SG_ 3221225472 SwitchedPowerOutput7Cmd "Desired state of Switched Power Output #7. Used to set the desired state.

00 - Output off
01 - Output on
10 - Reserved
11 - Take no action";
CM_ SG_ 3221225472 SwitchedPowerOutput8Cmd "Desired state of Switched Power Output #8. Used to set the desired state.

00 - Output off
01 - Output on
10 - Reserved
11 - Take no action";
CM_ SG_ 3221225472 SwitchedPowerOutput1Cmd "Desired state of Switched Power Output #1. Used to set the desired state.

00 - Output off
01 - Output on
10 - Reserved
11 - Take no action";
CM_ SG_ 3221225472 SwitchedPowerOutput2Cmd "Desired state of Switched Power Output #2. Used to set the desired state.

00 - Output off
01 - Output on
10 - Reserved
11 - Take no action";
CM_ SG_ 3221225472 SwitchedPowerOutput3Cmd "Desired state of Switched Power Output #3. Used to set the desired state.

00 - Output off
01 - Output on
10 - Reserved
11 - Take no action";
CM_ SG_ 3221225472 SwitchedPowerOutput4Cmd "Desired state of Switched Power Output #4. Used to set the desired state.

00 - Output off
01 - Output on
10 - Reserved
11 - Take no action";
CM_ SG_ 3221225472 SpecialIgnitorLoop90Resistance "Resistance of Special Ignitor Loop 90.   Since there are many different vehicle types (e.g. truck, bus, firetruck or ambulance), the ignitor loop configuration has a wide variation.";
CM_ SG_ 3221225472 SpecialIgnitorLoop89Resistance "Resistance of Special Ignitor Loop 89.   Since there are many different vehicle types (e.g. truck, bus, firetruck or ambulance), the ignitor loop configuration has a wide variation.";
CM_ SG_ 3221225472 SpecialIgnitorLoop88Resistance "Resistance of Special Ignitor Loop 88.   Since there are many different vehicle types (e.g. truck, bus, firetruck or ambulance), the ignitor loop configuration has a wide variation.";
CM_ SG_ 3221225472 SpecialIgnitorLoop87Resistance "Resistance of Special Ignitor Loop 87.   Since there are many different vehicle types (e.g. truck, bus, firetruck or ambulance), the ignitor loop configuration has a wide variation.";
CM_ SG_ 3221225472 SpecialIgnitorLoop86Resistance "Resistance of Special Ignitor Loop 86.   Since there are many different vehicle types (e.g. truck, bus, firetruck or ambulance), the ignitor loop configuration has a wide variation.";
CM_ SG_ 3221225472 SpecialIgnitorLoop85Resistance "Resistance of Special Ignitor Loop 85.   Since there are many different vehicle types (e.g. truck, bus, firetruck or ambulance), the ignitor loop configuration has a wide variation.";
CM_ SG_ 3221225472 SpecialIgnitorLoop84Resistance "Resistance of Special Ignitor Loop 84.   Since there are many different vehicle types (e.g. truck, bus, firetruck or ambulance), the ignitor loop configuration has a wide variation.";
CM_ SG_ 3221225472 SpecialIgnitorLoop83Resistance "Resistance of Special Ignitor Loop 83.   Since there are many different vehicle types (e.g. truck, bus, firetruck or ambulance), the ignitor loop configuration has a wide variation.";
CM_ SG_ 3221225472 SpecialIgnitorLoop82Resistance "Resistance of Special Ignitor Loop 82.   Since there are many different vehicle types (e.g. truck, bus, firetruck or ambulance), the ignitor loop configuration has a wide variation.";
CM_ SG_ 3221225472 SpecialIgnitorLoop81Resistance "Resistance of Special Ignitor Loop 81.   Since there are many different vehicle types (e.g. truck, bus, firetruck or ambulance), the ignitor loop configuration has a wide variation.";
CM_ SG_ 3221225472 SpecialIgnitorLoop80Resistance "Resistance of Special Ignitor Loop 80.   Since there are many different vehicle types (e.g. truck, bus, firetruck or ambulance), the ignitor loop configuration has a wide variation.";
CM_ SG_ 3221225472 SpecialIgnitorLoop79Resistance "Resistance of Special Ignitor Loop 79.   Since there are many different vehicle types (e.g. truck, bus, firetruck or ambulance), the ignitor loop configuration has a wide variation.";
CM_ SG_ 3221225472 SpecialIgnitorLoop78Resistance "Resistance of Special Ignitor Loop 78.   Since there are many different vehicle types (e.g. truck, bus, firetruck or ambulance), the ignitor loop configuration has a wide variation.";
CM_ SG_ 3221225472 SpecialIgnitorLoop77Resistance "Resistance of Special Ignitor Loop 77.   Since there are many different vehicle types (e.g. truck, bus, firetruck or ambulance), the ignitor loop configuration has a wide variation.";
CM_ SG_ 3221225472 SpecialIgnitorLoop76Resistance "Resistance of Special Ignitor Loop 76.   Since there are many different vehicle types (e.g. truck, bus, firetruck or ambulance), the ignitor loop configuration has a wide variation.";
CM_ SG_ 3221225472 SpecialIgnitorLoop75Resistance "Resistance of Special Ignitor Loop 75.   Since there are many different vehicle types (e.g. truck, bus, firetruck or ambulance), the ignitor loop configuration has a wide variation.";
CM_ SG_ 3221225472 SpecialIgnitorLoop74Resistance "Resistance of Special Ignitor Loop 74.   Since there are many different vehicle types (e.g. truck, bus, firetruck or ambulance), the ignitor loop configuration has a wide variation.";
CM_ SG_ 3221225472 SpecialIgnitorLoop73Resistance "Resistance of Special Ignitor Loop 73.   Since there are many different vehicle types (e.g. truck, bus, firetruck or ambulance), the ignitor loop configuration has a wide variation.";
CM_ SG_ 3221225472 SpecialIgnitorLoop72Resistance "Resistance of Special Ignitor Loop 72.   Since there are many different vehicle types (e.g. truck, bus, firetruck or ambulance), the ignitor loop configuration has a wide variation.";
CM_ SG_ 3221225472 SpecialIgnitorLoop71Resistance "Resistance of Special Ignitor Loop 71.   Since there are many different vehicle types (e.g. truck, bus, firetruck or ambulance), the ignitor loop configuration has a wide variation.";
CM_ SG_ 3221225472 SpecialIgnitorLoop70Resistance "Resistance of Special Ignitor Loop 70.   Since there are many different vehicle types (e.g. truck, bus, firetruck or ambulance), the ignitor loop configuration has a wide variation.";
CM_ SG_ 3221225472 SpecialIgnitorLoop69Resistance "Resistance of Special Ignitor Loop 69.   Since there are many different vehicle types (e.g. truck, bus, firetruck or ambulance), the ignitor loop configuration has a wide variation.";
CM_ SG_ 3221225472 SpecialIgnitorLoop68Resistance "Resistance of Special Ignitor Loop 68.   Since there are many different vehicle types (e.g. truck, bus, firetruck or ambulance), the ignitor loop configuration has a wide variation.";
CM_ SG_ 3221225472 SpecialIgnitorLoop67Resistance "Resistance of Special Ignitor Loop 67.   Since there are many different vehicle types (e.g. truck, bus, firetruck or ambulance), the ignitor loop configuration has a wide variation.";
CM_ SG_ 3221225472 SpecialIgnitorLoop66Resistance "Resistance of Special Ignitor Loop 66.   Since there are many different vehicle types (e.g. truck, bus, firetruck or ambulance), the ignitor loop configuration has a wide variation.";
CM_ SG_ 3221225472 SpecialIgnitorLoop65Resistance "Resistance of Special Ignitor Loop 65.   Since there are many different vehicle types (e.g. truck, bus, firetruck or ambulance), the ignitor loop configuration has a wide variation.";
CM_ SG_ 3221225472 SpecialIgnitorLoop64Resistance "Resistance of Special Ignitor Loop 64.   Since there are many different vehicle types (e.g. truck, bus, firetruck or ambulance), the ignitor loop configuration has a wide variation.";
CM_ SG_ 3221225472 SpecialIgnitorLoop63Resistance "Resistance of Special Ignitor Loop 63.   Since there are many different vehicle types (e.g. truck, bus, firetruck or ambulance), the ignitor loop configuration has a wide variation.";
CM_ SG_ 3221225472 SpecialIgnitorLoop62Resistance "Resistance of Special Ignitor Loop 62.   Since there are many different vehicle types (e.g. truck, bus, firetruck or ambulance), the ignitor loop configuration has a wide variation.";
CM_ SG_ 3221225472 SpecialIgnitorLoop61Resistance "Resistance of Special Ignitor Loop 61.   Since there are many different vehicle types (e.g. truck, bus, firetruck or ambulance), the ignitor loop configuration has a wide variation.";
CM_ SG_ 3221225472 SpecialIgnitorLoop60Resistance "Resistance of Special Ignitor Loop 60.   Since there are many different vehicle types (e.g. truck, bus, firetruck or ambulance), the ignitor loop configuration has a wide variation.";
CM_ SG_ 3221225472 SpecialIgnitorLoop59Resistance "Resistance of Special Ignitor Loop 59.   Since there are many different vehicle types (e.g. truck, bus, firetruck or ambulance), the ignitor loop configuration has a wide variation.";
CM_ SG_ 3221225472 SpecialIgnitorLoop58Resistance "Resistance of Special Ignitor Loop 58.   Since there are many different vehicle types (e.g. truck, bus, firetruck or ambulance), the ignitor loop configuration has a wide variation.";
CM_ SG_ 3221225472 SpecialIgnitorLoop57Resistance "Resistance of Special Ignitor Loop 57.   Since there are many different vehicle types (e.g. truck, bus, firetruck or ambulance), the ignitor loop configuration has a wide variation.";
CM_ SG_ 3221225472 SpecialIgnitorLoop56Resistance "Resistance of Special Ignitor Loop 56.   Since there are many different vehicle types (e.g. truck, bus, firetruck or ambulance), the ignitor loop configuration has a wide variation.";
CM_ SG_ 3221225472 SpecialIgnitorLoop55Resistance "Resistance of Special Ignitor Loop 55.   Since there are many different vehicle types (e.g. truck, bus, firetruck or ambulance), the ignitor loop configuration has a wide variation.";
CM_ SG_ 3221225472 SpecialIgnitorLoop54Resistance "Resistance of Special Ignitor Loop 54.   Since there are many different vehicle types (e.g. truck, bus, firetruck or ambulance), the ignitor loop configuration has a wide variation.";
CM_ SG_ 3221225472 SpecialIgnitorLoop53Resistance "Resistance of Special Ignitor Loop 53.   Since there are many different vehicle types (e.g. truck, bus, firetruck or ambulance), the ignitor loop configuration has a wide variation.";
CM_ SG_ 3221225472 SpecialIgnitorLoop52Resistance "Resistance of Special Ignitor Loop 52.   Since there are many different vehicle types (e.g. truck, bus, firetruck or ambulance), the ignitor loop configuration has a wide variation.";
CM_ SG_ 3221225472 SpecialIgnitorLoop51Resistance "Resistance of Special Ignitor Loop 51.   Since there are many different vehicle types (e.g. truck, bus, firetruck or ambulance), the ignitor loop configuration has a wide variation.";
CM_ SG_ 3221225472 SpecialIgnitorLoop50Resistance "Resistance of Special Ignitor Loop 50.   Since there are many different vehicle types (e.g. truck, bus, firetruck or ambulance), the ignitor loop configuration has a wide variation.";
CM_ SG_ 3221225472 SpecialIgnitorLoop49Resistance "Resistance of Special Ignitor Loop 49.   Since there are many different vehicle types (e.g. truck, bus, firetruck or ambulance), the ignitor loop configuration has a wide variation.";
CM_ SG_ 3221225472 SpecialIgnitorLoop48Resistance "Resistance of Special Ignitor Loop 48.   Since there are many different vehicle types (e.g. truck, bus, firetruck or ambulance), the ignitor loop configuration has a wide variation.";
CM_ SG_ 3221225472 SpecialIgnitorLoop47Resistance "Resistance of Special Ignitor Loop 47.   Since there are many different vehicle types (e.g. truck, bus, firetruck or ambulance), the ignitor loop configuration has a wide variation.";
CM_ SG_ 3221225472 SpecialIgnitorLoop46Resistance "Resistance of Special Ignitor Loop 46.   Since there are many different vehicle types (e.g. truck, bus, firetruck or ambulance), the ignitor loop configuration has a wide variation.";
CM_ SG_ 3221225472 SpecialIgnitorLoop45Resistance "Resistance of Special Ignitor Loop 45.   Since there are many different vehicle types (e.g. truck, bus, firetruck or ambulance), the ignitor loop configuration has a wide variation.";
CM_ SG_ 3221225472 SpecialIgnitorLoop44Resistance "Resistance of Special Ignitor Loop 44.   Since there are many different vehicle types (e.g. truck, bus, firetruck or ambulance), the ignitor loop configuration has a wide variation.";
CM_ SG_ 3221225472 SpecialIgnitorLoop43Resistance "Resistance of Special Ignitor Loop 43.   Since there are many different vehicle types (e.g. truck, bus, firetruck or ambulance), the ignitor loop configuration has a wide variation.";
CM_ SG_ 3221225472 SpecialIgnitorLoop42Resistance "Resistance of Special Ignitor Loop 42.   Since there are many different vehicle types (e.g. truck, bus, firetruck or ambulance), the ignitor loop configuration has a wide variation.";
CM_ SG_ 3221225472 SpecialIgnitorLoop41Resistance "Resistance of Special Ignitor Loop 41.   Since there are many different vehicle types (e.g. truck, bus, firetruck or ambulance), the ignitor loop configuration has a wide variation.";
CM_ SG_ 3221225472 SpecialIgnitorLoop40Resistance "Resistance of Special Ignitor Loop 40.   Since there are many different vehicle types (e.g. truck, bus, firetruck or ambulance), the ignitor loop configuration has a wide variation.";
CM_ SG_ 3221225472 SpecialIgnitorLoop39Resistance "Resistance of Special Ignitor Loop 39.   Since there are many different vehicle types (e.g. truck, bus, firetruck or ambulance), the ignitor loop configuration has a wide variation.";
CM_ SG_ 3221225472 SpecialIgnitorLoop38Resistance "Resistance of Special Ignitor Loop 38.   Since there are many different vehicle types (e.g. truck, bus, firetruck or ambulance), the ignitor loop configuration has a wide variation.";
CM_ SG_ 3221225472 SpecialIgnitorLoop37Resistance "Resistance of Special Ignitor Loop 37.   Since there are many different vehicle types (e.g. truck, bus, firetruck or ambulance), the ignitor loop configuration has a wide variation.";
CM_ SG_ 3221225472 SpecialIgnitorLoop36Resistance "Resistance of Special Ignitor Loop 36.   Since there are many different vehicle types (e.g. truck, bus, firetruck or ambulance), the ignitor loop configuration has a wide variation.";
CM_ SG_ 3221225472 SpecialIgnitorLoop35Resistance "Resistance of Special Ignitor Loop 35.   Since there are many different vehicle types (e.g. truck, bus, firetruck or ambulance), the ignitor loop configuration has a wide variation.";
CM_ SG_ 3221225472 SpecialIgnitorLoop34Resistance "Resistance of Special Ignitor Loop 34.   Since there are many different vehicle types (e.g. truck, bus, firetruck or ambulance), the ignitor loop configuration has a wide variation.";
CM_ SG_ 3221225472 SpecialIgnitorLoop33Resistance "Resistance of Special Ignitor Loop 33.   Since there are many different vehicle types (e.g. truck, bus, firetruck or ambulance), the ignitor loop configuration has a wide variation.";
CM_ SG_ 3221225472 SpecialIgnitorLoop32Resistance "Resistance of Special Ignitor Loop 32.   Since there are many different vehicle types (e.g. truck, bus, firetruck or ambulance), the ignitor loop configuration has a wide variation.";
CM_ SG_ 3221225472 SpecialIgnitorLoop31Resistance "Resistance of Special Ignitor Loop 31.   Since there are many different vehicle types (e.g. truck, bus, firetruck or ambulance), the ignitor loop configuration has a wide variation.";
CM_ SG_ 3221225472 SpecialIgnitorLoop30Resistance "Resistance of Special Ignitor Loop 30.   Since there are many different vehicle types (e.g. truck, bus, firetruck or ambulance), the ignitor loop configuration has a wide variation.";
CM_ SG_ 3221225472 SpecialIgnitorLoop29Resistance "Resistance of Special Ignitor Loop 29.   Since there are many different vehicle types (e.g. truck, bus, firetruck or ambulance), the ignitor loop configuration has a wide variation.";
CM_ SG_ 3221225472 SpecialIgnitorLoop28Resistance "Resistance of Special Ignitor Loop 28.   Since there are many different vehicle types (e.g. truck, bus, firetruck or ambulance), the ignitor loop configuration has a wide variation.";
CM_ SG_ 3221225472 SpecialIgnitorLoop27Resistance "Resistance of Special Ignitor Loop 27.   Since there are many different vehicle types (e.g. truck, bus, firetruck or ambulance), the ignitor loop configuration has a wide variation.";
CM_ SG_ 3221225472 SpecialIgnitorLoop26Resistance "Resistance of Special Ignitor Loop 26.   Since there are many different vehicle types (e.g. truck, bus, firetruck or ambulance), the ignitor loop configuration has a wide variation.";
CM_ SG_ 3221225472 SpecialIgnitorLoop25Resistance "Resistance of Special Ignitor Loop 25.   Since there are many different vehicle types (e.g. truck, bus, firetruck or ambulance), the ignitor loop configuration has a wide variation.";
CM_ SG_ 3221225472 SpecialIgnitorLoop24Resistance "Resistance of Special Ignitor Loop 24.   Since there are many different vehicle types (e.g. truck, bus, firetruck or ambulance), the ignitor loop configuration has a wide variation.";
CM_ SG_ 3221225472 SpecialIgnitorLoop23Resistance "Resistance of Special Ignitor Loop 23.   Since there are many different vehicle types (e.g. truck, bus, firetruck or ambulance), the ignitor loop configuration has a wide variation.";
CM_ SG_ 3221225472 SpecialIgnitorLoop22Resistance "Resistance of Special Ignitor Loop 22.   Since there are many different vehicle types (e.g. truck, bus, firetruck or ambulance), the ignitor loop configuration has a wide variation.";
CM_ SG_ 3221225472 SpecialIgnitorLoop21Resistance "Resistance of Special Ignitor Loop 21.   Since there are many different vehicle types (e.g. truck, bus, firetruck or ambulance), the ignitor loop configuration has a wide variation.";
CM_ SG_ 3221225472 SpecialIgnitorLoop20Resistance "Resistance of Special Ignitor Loop 20.   Since there are many different vehicle types (e.g. truck, bus, firetruck or ambulance), the ignitor loop configuration has a wide variation.";
CM_ SG_ 3221225472 SpecialIgnitorLoop19Resistance "Resistance of Special Ignitor Loop 19.   Since there are many different vehicle types (e.g. truck, bus, firetruck or ambulance), the ignitor loop configuration has a wide variation.";
CM_ SG_ 3221225472 SpecialIgnitorLoop18Resistance "Resistance of Special Ignitor Loop 18.   Since there are many different vehicle types (e.g. truck, bus, firetruck or ambulance), the ignitor loop configuration has a wide variation.";
CM_ SG_ 3221225472 SpecialIgnitorLoop17Resistance "Resistance of Special Ignitor Loop 17.   Since there are many different vehicle types (e.g. truck, bus, firetruck or ambulance), the ignitor loop configuration has a wide variation.";
CM_ SG_ 3221225472 SpecialIgnitorLoop16Resistance "Resistance of Special Ignitor Loop 16.   Since there are many different vehicle types (e.g. truck, bus, firetruck or ambulance), the ignitor loop configuration has a wide variation.";
CM_ SG_ 3221225472 SpecialIgnitorLoop15Resistance "Resistance of Special Ignitor Loop 15.   Since there are many different vehicle types (e.g. truck, bus, firetruck or ambulance), the ignitor loop configuration has a wide variation.";
CM_ SG_ 3221225472 SpecialIgnitorLoop14Resistance "Resistance of Special Ignitor Loop 14.   Since there are many different vehicle types (e.g. truck, bus, firetruck or ambulance), the ignitor loop configuration has a wide variation.";
CM_ SG_ 3221225472 SpecialIgnitorLoop13Resistance "Resistance of Special Ignitor Loop 13.   Since there are many different vehicle types (e.g. truck, bus, firetruck or ambulance), the ignitor loop configuration has a wide variation.";
CM_ SG_ 3221225472 SpecialIgnitorLoop12Resistance "Resistance of Special Ignitor Loop 12.   Since there are many different vehicle types (e.g. truck, bus, firetruck or ambulance), the ignitor loop configuration has a wide variation.";
CM_ SG_ 3221225472 SpecialIgnitorLoop11Resistance "Resistance of Special Ignitor Loop 11.   Since there are many different vehicle types (e.g. truck, bus, firetruck or ambulance), the ignitor loop configuration has a wide variation.";
CM_ SG_ 3221225472 SpecialIgnitorLoop10Resistance "Resistance of Special Ignitor Loop 10.   Since there are many different vehicle types (e.g. truck, bus, firetruck or ambulance), the ignitor loop configuration has a wide variation.";
CM_ SG_ 3221225472 SpecialIgnitorLoop9Resistance "Resistance of Special Ignitor Loop 9.   Since there are many different vehicle types (e.g. truck, bus, firetruck or ambulance), the ignitor loop configuration has a wide variation.";
CM_ SG_ 3221225472 SpecialIgnitorLoop8Resistance "Resistance of Special Ignitor Loop 8.   Since there are many different vehicle types (e.g. truck, bus, firetruck or ambulance), the ignitor loop configuration has a wide variation.";
CM_ SG_ 3221225472 SpecialIgnitorLoop7Resistance "Resistance of Special Ignitor Loop 7.   Since there are many different vehicle types (e.g. truck, bus, firetruck or ambulance), the ignitor loop configuration has a wide variation.";
CM_ SG_ 3221225472 SpecialIgnitorLoop6Resistance "Resistance of Special Ignitor Loop 6.   Since there are many different vehicle types (e.g. truck, bus, firetruck or ambulance), the ignitor loop configuration has a wide variation.";
CM_ SG_ 3221225472 SpecialIgnitorLoop5Resistance "Resistance of Special Ignitor Loop 5.   Since there are many different vehicle types (e.g. truck, bus, firetruck or ambulance), the ignitor loop configuration has a wide variation.";
CM_ SG_ 3221225472 SpecialIgnitorLoop4Resistance "Resistance of Special Ignitor Loop 4.   Since there are many different vehicle types (e.g. truck, bus, firetruck or ambulance), the ignitor loop configuration has a wide variation.";
CM_ SG_ 3221225472 SpecialIgnitorLoop3Resistance "Resistance of Special Ignitor Loop 3.   Since there are many different vehicle types (e.g. truck, bus, firetruck or ambulance), the ignitor loop configuration has a wide variation.";
CM_ SG_ 3221225472 SpecialIgnitorLoop2Resistance "Resistance of Special Ignitor Loop 2.   Since there are many different vehicle types (e.g. truck, bus, firetruck or ambulance), the ignitor loop configuration has a wide variation.";
CM_ SG_ 3221225472 SpecialIgnitorLoop1Resistance "Resistance of Special Ignitor Loop 1.   Since there are many different vehicle types (e.g. truck, bus, firetruck or ambulance), the ignitor loop configuration has a wide variation.";
CM_ SG_ 3221225472 SdBagIgnitorLoop2RightResistance "Resistance of Side Bag Ignitor Loop 2 - Right.";
CM_ SG_ 3221225472 SdBagIgnitorLoop1RightResistance "Resistance of Side Bag Ignitor Loop 1 - Right.";
CM_ SG_ 3221225472 SdeBagIgnitorLoop2LeftResistance "Resistance of Side Bag Ignitor Loop 2 - Left.";
CM_ SG_ 3221225472 SdeBagIgnitorLoop1LeftResistance "Resistance of Side Bag Ignitor Loop 1 - Left.";
CM_ SG_ 3221225472 PssngrBltTnsnrIgntrLopResistance "Resistance of Passenger Belt Tensioner Ignitor Loop 1st Stage.";
CM_ SG_ 3221225472 DrvrBltTnsnrIgntorLoopResistance "Resistance of Driver Belt Tensioner Ignitor Loop 1st Stage.";
CM_ SG_ 3221225472 PssngrArbgIgntrLp2ndStgRsistance "Resistance of Passenger Airbag Ignitor Loop 2nd Stage.";
CM_ SG_ 3221225472 DrvrArbgIgntrLp2ndStgeResistance "Resistance of Driver Airbag Ignitor Loop 2nd Stage.";
CM_ SG_ 3221225472 PssngrArbgIgntrLp1stStgRsistance "Resistance of Passenger Airbag Ignitor Loop 1st Stage.";
CM_ SG_ 3221225472 DrvrArbgIgntrLp1stStgeResistance "Resistance of Driver Airbag Ignitor Loop 1st Stage.";
CM_ SG_ 3221225472 EngTorqueLimit6AxleInput "Limit applied to the engine output torque based on the maximum allowable axle input torque.  Axle input torque is calculated as the current engine torque output multiplied by the transmission gear ratio.";
CM_ SG_ 3221225472 EngTorqueLimit5Switch "Limit applied to the engine output torque based on activation of an ECU switch input.";
CM_ SG_ 3221225472 EngTorqueLimit4Trans "Limit applied to the engine output torque during vehicle operation in transmission gear ratios numerically less than or equal to transmission gear ratio 3 (see SPN 1259).";
CM_ SG_ 3221225472 EngTorqueLimit3Trans "Limit applied to the engine output torque during vehicle operation in transmission gear ratios numerically less than or equal to transmission gear ratio 2 (see SPN 1257) and numerically greater than transmission gear ratio 3 (see.SPN 1259).  For ...";
CM_ SG_ 3221225472 TransGearRatio3 "Gear ratio value stored in the ECU that is used to define a range of transmission gears for which a limit is applied to the engine output torque.  Transmission gear ratio 3 should be the numerically highest transmission gear ratio breakpoint less ...";
CM_ SG_ 3221225472 EngTorqueLimit2Trans "Limit applied to the engine output torque during vehicle operation in transmission gear ratios numerically less than or equal to transmission gear ratio 1 (see SPN 1255) and numerically greater than transmission gear ratio 2 (see.SPN 1257).  For ...";
CM_ SG_ 3221225472 TransGearRatio2 "Gear ratio value stored in the ECU that is used to define a range of transmission gears for which a limit is applied to the engine output torque.  Transmission gear ratio 2 should be the numerically highest transmission gear ratio breakpoint less ...";
CM_ SG_ 3221225472 EngTorqueLimit1Trans "Limit applied to the engine output torque during vehicle operation in transmission gear ratios numerically greater than transmission gear ratio 1 (see SPN 1255).";
CM_ SG_ 3221225472 TransGearRatio1 "Gear ratio value stored in the ECU that is used to define a range of transmission gears for which a limit is applied to the engine output torque.  Transmission gear ratio 1 should be the numerically highest transmission gear ratio breakpoint that ...";
CM_ SG_ 3221225472 EngTorqueLimitFeature "Torque limit rating described in the current record.
000 Reserved
001 Highest torque rating
010 First torque rating
011 Previous torque rating (rating prior to the current rating)
100 Current torque rating
101-110 Reserved
111 Not available
 ...";
CM_ SG_ 3221225472 TorqueLimitingFeatureStatus "Status of an ECU feature which limits the torque output of the engine. 

00 - Disabled
01 - Enabled
10 - Error
11 - Not available";
CM_ SG_ 3221225472 CalibRecordDurationTime "Duration in hours for which the engine operated in the conditions captured in the current record.";
CM_ SG_ 3221225472 CalibRecordStartYear "Calendar year timestamp when an ECU record was established.

NOTE - A value of 0 for the year identifies the year 1985; a value of 1 identifies 1986; etc.";
CM_ SG_ 3221225472 CalibRecordStartDay "Calendar day timestamp when an ECU record was established.

NOTE - A value of 0 for the date is null.  The values 1, 2, 3, and 4 are used to identify the first day of the month; 5, 6, 7, and 8 identify the second day of the month; etc.";
CM_ SG_ 3221225472 CalibRecordStartMonth "Calendar month timestamp when an ECU record was established.

NOTE - A value of 0 for the month is null.  The value 1 identifies January; 2 identifies February; etc.";
CM_ SG_ 3221225472 EngPeakTorque2 "Maximum torque output of the current ECU calibration when the engine operates on torque curve 2.  For calibrations that support two torque curves, this parameter shall be assigned the value of the higher curve.  For calibrations that support only ...";
CM_ SG_ 3221225472 EngPeakTorque1 "Maximum torque output of the current ECU calibration when the engine operates on torque curve 1.  For calibrations that support two torque curves, this parameter shall be assigned the value of the lower curve.  For calibrations that support only one ...";
CM_ SG_ 3221225472 EngPower "Advertised engine power capability.  Advertised power is what a customer will find on a sales sheet for an engine with a certain calibration.";
CM_ SG_ 3221225472 NumberOfEngTorqueHistoryRecords "Number of torque history records contained in the engine torque history PGN.  A value of 0 is broadcast if no torque history records are stored in the ECU.";
CM_ SG_ 3221225472 RolloverSensorType "Type of Rollover Sensor.
0000 = acceleration sensor
0001 = pressure sensor
0010 = rollrate sensor
0011 = sonic sensor
0100 = fiber-optic sensor
0101 = radar sensor
0110 = lidar sensor
0111 = optical sensor
1000-1101 =  Reserved
1110 = ...";
CM_ SG_ 3221225472 RearCollisionSensor4Type "Type of Rear Collision Sensor 4.
0000 = acceleration sensor
0001 = pressure sensor
0010 = rollrate sensor
0011 = sonic sensor
0100 = fiber-optic sensor
0101 = radar sensor
0110 = lidar sensor
0111 = optical sensor
1000-1101 =  Reserved
 ...";
CM_ SG_ 3221225472 RearCollisionSensor3Type "Type of Rear Collision Sensor 3.
0000 = acceleration sensor
0001 = pressure sensor
0010 = rollrate sensor
0011 = sonic sensor
0100 = fiber-optic sensor
0101 = radar sensor
0110 = lidar sensor
0111 = optical sensor
1000-1101 =  Reserved
 ...";
CM_ SG_ 3221225472 RearCollisionSensor2Type "Type of Rear Collision Sensor 2.
0000 = acceleration sensor
0001 = pressure sensor
0010 = rollrate sensor
0011 = sonic sensor
0100 = fiber-optic sensor
0101 = radar sensor
0110 = lidar sensor
0111 = optical sensor
1000-1101 =  Reserved
 ...";
CM_ SG_ 3221225472 RearCollisionSensor1Type "Type of Rear Collision Sensor 1.
0000 = acceleration sensor
0001 = pressure sensor
0010 = rollrate sensor
0011 = sonic sensor
0100 = fiber-optic sensor
0101 = radar sensor
0110 = lidar sensor
0111 = optical sensor
1000-1101 =  Reserved
 ...";
CM_ SG_ 3221225472 SideCollisionSensorRearRightType "Type of Side Collision Sensor Rear - Right.
0000 = acceleration sensor
0001 = pressure sensor
0010 = rollrate sensor
0011 = sonic sensor
0100 = fiber-optic sensor
0101 = radar sensor
0110 = lidar sensor
0111 = optical sensor
1000-1101 = ...";
CM_ SG_ 3221225472 SdCllisionSensorMidRearRightType "Type of Side Collision Sensor Mid Rear - Right.
0000 = acceleration sensor
0001 = pressure sensor
0010 = rollrate sensor
0011 = sonic sensor
0100 = fiber-optic sensor
0101 = radar sensor
0110 = lidar sensor
0111 = optical sensor
1000-1101 = ...";
CM_ SG_ 3221225472 SdCllsionSensorMidFrontRightType "Type of Side Collision Sensor Mid Front - Right.
0000 = acceleration sensor
0001 = pressure sensor
0010 = rollrate sensor
0011 = sonic sensor
0100 = fiber-optic sensor
0101 = radar sensor
0110 = lidar sensor
0111 = optical sensor
1000-1101 ...";
CM_ SG_ 3221225472 SdeCollisionSensorFrontRightType "Type of Side Collision Sensor Front - Right.
0000 = acceleration sensor
0001 = pressure sensor
0010 = rollrate sensor
0011 = sonic sensor
0100 = fiber-optic sensor
0101 = radar sensor
0110 = lidar sensor
0111 = optical sensor
1000-1101 = ...";
CM_ SG_ 3221225472 SideCollisionSensorRearLeftType "Type of Side Collision Sensor Rear - Left.
0000 = acceleration sensor
0001 = pressure sensor
0010 = rollrate sensor
0011 = sonic sensor
0100 = fiber-optic sensor
0101 = radar sensor
0110 = lidar sensor
0111 = optical sensor
1000-1101 = ...";
CM_ SG_ 3221225472 SdCollisionSensorMidRearLeftType "Type of Side Collision Sensor Mid Rear - Left.
0000 = acceleration sensor
0001 = pressure sensor
0010 = rollrate sensor
0011 = sonic sensor
0100 = fiber-optic sensor
0101 = radar sensor
0110 = lidar sensor
0111 = optical sensor
1000-1101 = ...";
CM_ SG_ 3221225472 SdCllisionSensorMidFrontLeftType "Type of Side Collision Sensor Mid Front - Left.
0000 = acceleration sensor
0001 = pressure sensor
0010 = rollrate sensor
0011 = sonic sensor
0100 = fiber-optic sensor
0101 = radar sensor
0110 = lidar sensor
0111 = optical sensor
1000-1101 = ...";
CM_ SG_ 3221225472 SideCollisionSensorFrontLeftType "Type of Side Collision Sensor Front - Left.
0000 = acceleration sensor
0001 = pressure sensor
0010 = rollrate sensor
0011 = sonic sensor
0100 = fiber-optic sensor
0101 = radar sensor
0110 = lidar sensor
0111 = optical sensor
1000-1101 = ...";
CM_ SG_ 3221225472 FrontalCollisionSensor4Type "Type of Frontal Collision Sensor 4.
0000 = acceleration sensor
0001 = pressure sensor
0010 = rollrate sensor
0011 = sonic sensor
0100 = fiber-optic sensor
0101 = radar sensor
0110 = lidar sensor
0111 = optical sensor
1000-1101 =  Reserved
 ...";
CM_ SG_ 3221225472 FrontalCollisionSensor3Type "Type of Frontal Collision Sensor 3.
0000 = acceleration sensor
0001 = pressure sensor
0010 = rollrate sensor
0011 = sonic sensor
0100 = fiber-optic sensor
0101 = radar sensor
0110 = lidar sensor
0111 = optical sensor
1000-1101 =  Reserved
 ...";
CM_ SG_ 3221225472 FrontalCollisionSensor2Type "Type of Frontal Collision Sensor 2.
0000 = acceleration sensor
0001 = pressure sensor
0010 = rollrate sensor
0011 = sonic sensor
0100 = fiber-optic sensor
0101 = radar sensor
0110 = lidar sensor
0111 = optical sensor
1000-1101 =  Reserved
 ...";
CM_ SG_ 3221225472 FrontalCollisionSensor1Type "Type of Frontal Collision Sensor 1.
0000 = acceleration sensor
0001 = pressure sensor
0010 = rollrate sensor
0011 = sonic sensor
0100 = fiber-optic sensor
0101 = radar sensor
0110 = lidar sensor
0111 = optical sensor
1000-1101 =  Reserved
 ...";
CM_ SG_ 3221225472 DPFAvgDistBetweenActiveRegens "Indicates the average distance since last reset between active regenerations, that have not been forced to occur by manual request, for aftertreatment device 1.
If the manufacturer allows this parameter to be reset, this distance is the average ...";
CM_ SG_ 3221225472 DPFAvgTimeBetweenActiveRegens "Indicates the average time since last reset between active regenerations, that have not been forced to occur by manual request, for Aftertreatment device 1.
If the manufacturer allows this parameter to be reset, this time is the average since last ...";
CM_ SG_ 3221225472 DPFTotalNumOfActiveRegenManReq "Total number of aftertreatment device 1 active regeneration manual requests by the operator over the lifetime of the device.";
CM_ SG_ 3221225472 DPFTotalNumOfActiveRegenInhReq "Total number of aftertreatment device 1 active regeneration inhibit requests by the operator over the lifetime of the device.";
CM_ SG_ 3221225472 DPFTotalNumOfPassiveRegens "Total number of passive regenerations by aftertreatment device 1 over the lifetime of the device.";
CM_ SG_ 3221225472 DPFTotalPassiveRegenTime "Total amount of time that aftertreatment 1 diesel particulate filter has been in passive regeneration over the lifetime of the device.";
CM_ SG_ 3221225472 TotalNumOfActiveRegens "Total number of active regenerations by aftertreatment device 1 over the lifetime of the device.";
CM_ SG_ 3221225472 TotalDisdTime "Total amount of time that aftertreatment 1 regeneration has been manually disabled.";
CM_ SG_ 3221225472 TotalRegenTime "Total amount of time that aftertreatment device 1 has been regenerating over the lifetime of the device.";
CM_ SG_ 3221225472 TotalFuelUsed "Total amount of fuel used by aftertreatment device 1 over the lifetime of the device.";
CM_ SG_ 3221225472 DPFAvgDistBetweenActiveRegens "Indicates the average distance since last reset between active regenerations, that have not been forced to occur by manual request, for aftertreatment device 2.
If the manufacturer allows this parameter to be reset, this distance is the average ...";
CM_ SG_ 3221225472 DPFAvgTimeBetweenActiveRegens "Indicates the average time since last reset between active regenerations, that have not been forced to occur by manual request, for Aftertreatment device 2.";
CM_ SG_ 3221225472 DPFTotalNumOfActiveRegenManReq "Total number of Aftertreatment device 2 active regeneration manual requests by the operator over the lifetime of the device.";
CM_ SG_ 3221225472 DPFTotalNumOfActiveRegenInhReq "Total number of Aftertreatment device 2 active regeneration inhibit requests by the operator over the lifetime of the device.";
CM_ SG_ 3221225472 DPFTotalNumOfPassiveRegens "Total number of passive regenerations by Aftertreatment device 2 over the lifetime of the device.";
CM_ SG_ 3221225472 DPFTotalPassiveRegenTime "Total amount of time that Aftertreatment device 2 has been in passive regeneration over the lifetime of the device.";
CM_ SG_ 3221225472 TotalNumOfActiveRegens "Total number of active regenerations by aftertreatment device 2 over the lifetime of the device.";
CM_ SG_ 3221225472 TotalDisdTime "Total amount of time that aftertreatment 2 regeneration has been manually disabled.";
CM_ SG_ 3221225472 TotalRegenTime "Total amount of time that aftertreatment device 2 has been regenerating over the lifetime of the device.";
CM_ SG_ 3221225472 TotalFuelUsed "Total amount of fuel used by aftertreatment device 2 over the lifetime of the device.";
CM_ BO_ 2566658558 "Payload System Totals 1
Payload measurement system accumulators related to the haul cycle productivity.";
CM_ SG_ 2566658558 TotalHaulCycleCount "The total accumulated number of haul cycles over the life of the product.
This should be a monotonically increasing number that sums Haul Cycle Count (SPN 6847). If transactions are supported via Payload Delivery Transaction Status (SPN 7702) then ...";
CM_ SG_ 2566658558 TotalDeliveredPayloadWeight "The accumulated delivered payload mass over the life of the product.
This should be a monotonically increasing number that sums delivered payload weights (SPN 6849) If transactions are supported (Payload Delivery Transaction Status, SPN 7702) then ...";
CM_ BO_ 2566658302 "Payload System Totals 2
Payload measurement system accumulators.";
CM_ SG_ 2566658302 TotalPayloadTransactionCount "The accumulated number of completed payload delivery transactions over the life of the product.
If transaction status monitoring is supported via Payload Delivery Transaction Status (SPN 7702) then total payload transaction count may increment when ...";
CM_ BO_ 2499549182 "Payload Temperature 1
Payload temperatures";
CM_ BO_ 2499548926 "Payload Temperature 2
Payload temperatures";
CM_ BO_ 2499548670 "Vehicle Electrical Power 6
Voltage and current measurements for batteries 3 and 4.";
CM_ BO_ 2499548158 "Door Latch Status
This message provides status of the cabin door  latches. Doors are numbered left to right, front to back.";
CM_ SG_ 2499548158 RightRearCabDoorLatchPos "Status of the right rear cab door latch. Door latches may have 3 positions indicating fully open, 1st detent or \"ajar\", and 2nd detent or fully closed.
000 = Door Latch Open
001 = Door Latch Fully Closed/Latched
010 = Door Latch Ajar
011 = ...";
CM_ SG_ 2499548158 LeftRearCabDoorLatchPos "Status of the left rear cab door latch. Door latches may have 3 positions indicating fully open, 1st detent or \"ajar\", and 2nd detent or fully closed.
000 = Door Latch Open
001 = Door Latch Fully Closed/Latched
010 = Door Latch Ajar
011 = ...";
CM_ SG_ 2499548158 RightFrontCabDoorLatchPos "Status of the right front cab door latch (passenger door for left-hand steer vehicles). Door latches may have 3 positions indicating fully open, 1st detent or \"ajar\", and 2nd detent or fully closed.
000 = Door Latch Open
001 = Door Latch Fully ...";
CM_ SG_ 2499548158 LeftFrontCabDoorLatchPos "Status of the left front cab door latch (driver door for left-hand steer vehicles). Door latches may have 3 positions indicating fully open, 1st detent or \"ajar\", and 2nd detent or fully closed.
000 = Door Latch Open
001 = Door Latch Fully ...";
CM_ BO_ 2499547902 "Cab Door Control
This message requests or commands the cabin door functionality; door latches, windows, and mirrors. Doors are numbered left to right, front to back.";
CM_ SG_ 2499547902 MirrorRight2HeatCmd "Command to activate heater for second mirror on the right side (passenger side for left-hand steer vehicle).  Mirror heat may be expected to latch in the \"on\" state upon receipt of the command, stay on while the command is \"take no action\" and turn ...";
CM_ SG_ 2499547902 MirrorLeft2HeatCmd "Command to activate heater for second mirror on the left side (driver side for left-hand steer vehicle).  Mirror heat may be expected to latch in the \"on\" state upon receipt of the command, stay on while the command is \"take no action\" and turn off ...";
CM_ SG_ 2499547902 MirrorRight1HeatCmd "Command to activate heater for primary mirror on the right side (passenger side for left-hand steer vehicle).  Mirror heat may be expected to latch in the \"on\" state upon receipt of the command, stay on while the command is \"take no action\" and turn ...";
CM_ SG_ 2499547902 MirrorLeft1HeatCmd "Command to activate heater for primary mirror on the left side (driver side for left-hand steer vehicle).  Mirror heat may be expected to latch in the \"on\" state upon receipt of the command, stay on while the command is \"take no action\" and turn off ...";
CM_ SG_ 2499547902 MirrorRight2VerticalCmd "Commands vertical position change of the second mirror on the right side (passenger side for lefthand steer vehicles).

00 = Move up
01 = Move down
10 = Reserved
11 = Take no action";
CM_ SG_ 2499547902 MirrorRight2HorizontalCmd "Commands horizontal position change of the second mirror on the right side (passenger side for lefthand steer vehicles).

00 = Move left
01 = Move right
10 = Reserved
11 = Take no action";
CM_ SG_ 2499547902 MirrorLeft2VerticalCmd "Commands vertical position change of the second mirror on the left side (driver side for left-hand steer vehicles). 

00 = Move up
01 = Move down
10 = Reserved
11 = Take no action";
CM_ SG_ 2499547902 MirrorLeft2HorizontalCmd "Commands horizontal position change of the second mirror on the left side (driver side for left-hand steer vehicles).

00 = Move left
01 = Move right
10 = Reserved
11 = Take no action";
CM_ SG_ 2499547902 MirrorRight1VerticalCmd "Commands vertical position change of the primary mirror on the right side (passenger side for lefthand steer vehicles).

00 = Move up
01 = Move down
10 = Reserved
11 = Take no action";
CM_ SG_ 2499547902 MirrorRight1HorizontalCmd "Commands horizontal position change of the primary mirror on the right side (passenger side for lefthand steer vehicles).

00 = Move left
01 = Move right
10 = Reserved
11 = Take no action";
CM_ SG_ 2499547902 MirrorLeft1VerticalCmd "Commands vertical position change of the primary mirror on the left side (driver side for left-hand steer vehicles).

00 = Move up
01 = Move down
10 = Reserved
11 = Take no action";
CM_ SG_ 2499547902 MirrorLeft1HorizontalCmd "Commands horizontal position change of the primary mirror on the left side (driver side for left-hand steer vehicles).

00 = Move left
01 = Move right
10 = Reserved
11 = Take no action";
CM_ SG_ 2499547902 RightRearWindowPosCmd "Commands position change of the right rear window.

000 = Window move up
001 = Window move down
010 = Window auto up
011 = Window auto down
100 = Reserved
101 = Reserved
110 = Reserved
111 = Take no action";
CM_ SG_ 2499547902 LeftRearWindowPosCmd "Commands position change of left rear window.

000 = Window move up
001 = Window move down
010 = Window auto up
011 = Window auto down
100 = Reserved
101 = Reserved
110 = Reserved
111 = Take no action";
CM_ SG_ 2499547902 RightFrontWindowPosCmd "Commands position change of right front window (passenger door window on left-hand steer vehicles).
000 = Window move up
001 = Window move down
010 = Window auto up
011 = Window auto down
100 = Reserved
101 = Reserved
110 = Reserved
111 = ...";
CM_ SG_ 2499547902 LeftFrontWindowPosCmd "Commands position change of left front window (driver door window on left-hand steer vehicles).
000 = Window move up
001 = Window move down
010 = Window auto up
011 = Window auto down
100 = Reserved
101 = Reserved
110 = Reserved
111 = Take ...";
CM_ SG_ 2499547902 RemoteCabDoorLockReq "Request to the cab door lock controller from Remote Keyless Entry or or other external device to lock or unlock doors.
This parameter is different from Cab Doors Lock Actuation Command (SPN xxxx) because this is a request to actuate door locks ...";
CM_ SG_ 2499547902 DoorsLockActCmd "Commands cab door latch state change: lock or unlock.
000 = Unlock left front cab door latch (driver door on LH steer vehicles)
001 = Unlock right front cab door latch (front passenger door for LH steer vehicles)
010 = Unlock left rear cab door ...";
CM_ BO_ 2566656510 "Total Gaseous Fuel Information
Reports the total fuel information of systems using gaseous fuel.";
CM_ SG_ 2566656510 EngTotalGasIdleFuelVolumeUsed "Accumulated volume of engine gaseous fuel used during vehicle operation under idle conditions, in standard cubic meters.";
CM_ SG_ 2566656510 EngTotalGasFuelVolumeUsed "Accumulated volume of engine gaseous fuel used during vehicle operation, in standard cubic meters.

See SPN 1040 for alternate units.";
CM_ BO_ 2565929214 "Advanced Driver Assistance Systems Interface Specification 3
Refer to ADASIS for specific message and parameter definitions. See the ADASIS1  (PGN xxx) for more information.";
CM_ BO_ 2565928958 "Advanced Driver Assistance Systems Interface Specification 2
Refer to ADASIS for specific message and parameter  definitions. See ADASIS1 (PGN 61686) for more information.";
CM_ BO_ 2565928702 "Advanced Driver Assistance Systems Interface Specification 1
Advanced Driver Assistance Systems Interface Specification (ADASIS) defines parameters that describe the upcoming vehicle's environment, including the attributes about the current ...";
CM_ BO_ 2431710718 "Engine Start Arbitrator
Message from the engine start arbitrator, used to manage engine starts.
Default broadcast rate of 20 ms unless the arbitrator is transmitting Engine Start Control Message Rate (SPN 7752) indicating a switch to 250 ms or on ...";
CM_ SG_ 2431710718 Checksum "Checksum to allow detection of data integrity issues. The receiving node shall calculate the checksum and compare its calculated value with the received checksum. In case of a mismatch the message shall be discarded.
The message checksum is ...";
CM_ SG_ 2431710718 MessageCounter "Message counter to allow detection of data integrity issues. The counter is incremented every time a device sends out the Engine Start Control message. When the counter has reached a value of 15 it starts over at 0 for the next message cycle ...";
CM_ SG_ 2431710718 AutomaticEngStartConsentSummary "Arbitrator’s summary of the consent statuses of all devices which the arbitrator considers for automatic start requests. The purpose of this parameter is for requesters to determine if an automatic start request would be honored at the current time.
 ...";
CM_ SG_ 2431710718 OpEngStartConsentSummary "Arbitrator’s summary of the consent statuses of all devices which the arbitrator considers for operator start requests. The purpose of this parameter is for requesters to determine if an operator start request would be honored at the current time.
 ...";
CM_ SG_ 2431710718 ReqLatchStatus "Indicates the arbitrator’s latch status for engine start requests. All “unlatched” states shall transition to state “0 - Start Request not received” after 1000 ms unless a different state becomes more appropriate in the meantime. While this time may ...";
CM_ SG_ 2431710718 StarterCmd "Command from the arbitrator to the engine starter controller(s).
The arbitrator takes input from consenters and requesters to initiate an engine start. This signal is used by the arbitrator to command the first or second starter instance.
Starter ...";
CM_ SG_ 2431710718 CtrlMessageRate "This signal is sent by the arbitrator to control the rate at which other participants send the Engine Start Control Message (ENGSC). The arbitrator sets this signal to the slower rate after the first engine start attempt after initial power-up is ...";
CM_ BO_ 2431708670 "Engine Start Control
Message used to manage engine starts.
Default broadcast rate of 20 ms unless the sending  device has received Engine Start Control Message Rate (SPN 7752j) from the engine start arbitrator indicating a  switch to 250 ms or on ...";
CM_ SG_ 2431708670 Checksum "Checksum to allow detection of data integrity issues. The receiving node shall calculate the checksum and compare its calculated value with the received checksum. In case of a mismatch the message shall be discarded.
The message checksum is ...";
CM_ SG_ 2431708670 MessageCounter "Message counter to allow detection of data integrity issues. The counter is incremented every time a device sends out the Engine Start Control message. When the counter has reached a value of 15 it starts over at 0 for the next message cycle ...";
CM_ SG_ 2431708670 Starter2Feedback "Feedback of the current state of second engine starter. This signal is intended to be used by the arbitrator as feedback to its command signal (SPN 7753).
Additional details regarding the starter state may be available in SPN 1675.
000 = Starter ...";
CM_ SG_ 2431708670 Starter1Feedback "Feedback of the current state of first engine starter. This signal is intended to be used by the arbitrator as feedback to its command signal (SPN 7753).
Additional details regarding the starter state may be available in SPN 1675.
000 = Starter ...";
CM_ SG_ 2431708670 AbortReq "Indicates the sender’s desire to abort an engine start. This signal is used by requesters and consenters to request that the arbitrator cancel an engine start that is in progress.
The sender of this signal may increase the broadcast rate ...";
CM_ SG_ 2431708670 Consent "Indicates the sender’s consent to start the engine for different start types. An operator-requested engine start is a start that is initiated directly by the operator (i.e. via the key switch). An automatic engine start is one that is initiated by a ...";
CM_ SG_ 2431708670 Req "Indicates the sender’s desire to start the engine. The engine start arbitrator latches this signal and, if possible, completes the engine start regardless of a change of state of this signal. Use Engine Start Abort Request (SPN 7747) to un-latch the ...";
CM_ BO_ 2566661118 "Fuel Consumption (Liquid) 2
Engine fuel consumption accumulators.";
CM_ SG_ 2566661118 EngTotalDieselFuelDemand "Accumulated amount of liquid fuel that would have been used during engine operation, including actual diesel fuel used and the diesel fuel that was displaced by gaseous fuel.

This is the cumulative value of SPN 7596.";
CM_ BO_ 2633769726 "Electronic Engine Controller 19
Engine related parameters";
CM_ SG_ 2633769726 TotalEngEnergy "The total amount of energy delivered by the engine. It is accumulated over the life of the engine.";
CM_ BO_ 2565926142 "Aftertreatment 2 Outlet Sensor 2
The purpose of this PGN is to group the aftertreatment outlet sensor data for bank 2.  These values include the NOx, %O2, status of the sensors with respect to the power being supplied and the heating element, ...";
CM_ SG_ 2565926142 O2Snsr2PreliminaryFMI "Used to identify the applicable J1939-73 FMI detected in the aftertreatment outlet oxygen second sensor by the manufacturer’s sensor control software in exhaust bank 2.  When there is no failure FMI 31 is sent.  In the case of multiple failures the ...";
CM_ SG_ 2565926142 NOxSnsr2SelfDiagStatus "Self-diagnosis result status for second NOx sensor ATO2 (Aftertreatment Outlet Bank 2)
000 Diagnosis not active
001 NOx Sensor ATO2 Self Diagnosis active flag
010 NOx Sensor ATO2 Self Diagnosis Result Complete
011 NOx Sensor ATO2 Self Diagnosis ...";
CM_ SG_ 2565926142 NOxSnsr2PreliminaryFMI "Used to identify the applicable J1939-73 FMI detected in the aftertreatment outlet NOx second sensor by the manufacturer’s sensor control software in exhaust bank 2.  When there is no failure FMI 31 is sent.  In the case of multiple failures the ...";
CM_ SG_ 2565926142 GasSnsr2HtrCtrl "Indicates the heater status in the warm-up process.  Upon receiving a power-up command, the gas second sensor ramps up according to a manufacturer defined profile.  The Preheat 1, Preheat 2, and Automatic messages are regions within this profile in ...";
CM_ SG_ 2565926142 GasSnsr2HtrPreliminaryFMI "Used to identify the applicable J1939-73 FMI detected in the heater of the outlet exhaust gas second sensor, either NOx or O2, by the manufacturer’s sensor control software in exhaust bank 2.  When there is no failure FMI 31 is sent.  In the case of ...";
CM_ SG_ 2565926142 WRPercentO22ReadingStable "Indicates that the percent oxygen reading of the aftertreatment outlet gas second sensor, either NOx or O2, is stable as determined by the manufacturer's control software in exhaust bank 2.
For a single exhaust bank system, refer to parameters in ...";
CM_ SG_ 2565926142 NOx2ReadingStable "Indicates that the NOx reading of the aftertreatment outlet NOx second sensor is stable as determined by the manufacturer’s control software in exhaust bank 2.
For a single exhaust bank system, refer to parameters in PGNs 61454, 61455, 64946, ...";
CM_ SG_ 2565926142 GasSnsr2AtTemp "Indicates that the heater element of the aftertreatment outlet gas second sensor, either NOx or O2, is within the manufacturer’s specified range for accurate measurements in exhaust bank 2.
For a single exhaust bank system, refer to parameters in ...";
CM_ SG_ 2565926142 GasSnsr2PwrInRange "Indicates that the power supplied to the aftertreatment outlet gas second sensor, either NOx or O2, is within the manufacturer’s specification in exhaust bank 2.
For a single exhaust bank system, refer to parameters in PGNs 61454, 61455, 64946, ...";
CM_ SG_ 2565926142 PercentO22 "The actual oxidation factor (percent oxygen) of the gas within the exhaust stream.  For positive values, the parameter represents the percent oxygen in excess of the amount required for stoichiometric combustion.  For negative values, the parameter ...";
CM_ SG_ 2565926142 NOx2 "The amount of combined NO and NO2 in the exhaust entering the aftertreatment system measured by the second NOx sensor at the aftertreatment outlet, represented in NOx molecule parts per million non-NOx molecules in exhaust bank 2.
For a single ...";
CM_ BO_ 2565925886 "Aftertreatment 2 Intake Sensor 2
The purpose of this PGN is to group the aftertreatment intake sensor data for bank 2.  These values include the NOx, %O2, status of the sensors with respect to the power being supplied and the heating element, ...";
CM_ SG_ 2565925886 O2Snsr2PreliminaryFMI "Used to identify the applicable J1939-73 FMI detected in the aftertreatment intake oxygen second sensor by the manufacturer’s sensor control software in exhaust bank 2.  When there is no failure FMI 31 is sent.  In the case of multiple failures the ...";
CM_ SG_ 2565925886 NOxSnsr2SelfDiagStatus "Self-diagnosis result status for NOx second sensor ATI2 (Aftertreatment Intake Bank 2)
000 Diagnosis not active
001 NOx Sensor ATI2 Self Diagnosis active flag
010 NOx Sensor ATI2 Self Diagnosis Result Complete
011 NOx Sensor ATI2 Self Diagnosis ...";
CM_ SG_ 2565925886 SCRInNOxSnsr2PreliminaryFMI "Used to identify the applicable J1939-73 FMI detected in the aftertreatment intake NOx second sensor by the manufacturer’s sensor control software in exhaust bank 2.  When there is no failure FMI 31 is sent.  In the case of multiple failures the ...";
CM_ SG_ 2565925886 GasSnsr2HtrCtrl "Indicates the heater status in the warm-up process.  Upon receiving a power-up command, the second gas sensor ramps up according to a manufacturer defined profile.  The Preheat 1, Preheat 2, and Automatic messages are regions within this profile in ...";
CM_ SG_ 2565925886 GasSnsr2HtrPreliminaryFMI "Used to identify the applicable J1939-73 FMI detected in the heater of the intake exhaust gas second sensor, either NOx or O2, by the manufacturer’s sensor control software in exhaust bank 2.  When there is no failure FMI 31 is sent.  In the case of ...";
CM_ SG_ 2565925886 WRPercentO22ReadingStable "Indicates that the percent oxygen reading of the aftertreatment intake gas second sensor, either NOx or O2, is stable as determined by the manufacturer's control software in exhaust bank 2.
For a single exhaust bank system, refer to parameters in ...";
CM_ SG_ 2565925886 SCRInNOx2ReadingStable "Indicates that the NOx reading of the aftertreatment intake NOx second sensor is stable as determined by the manufacturer’s control software in exhaust bank 2.
For a single exhaust bank system, refer to parameters in PGNs 61454, 61455, 64946, ...";
CM_ SG_ 2565925886 GasSnsr2AtTemp "Indicates that the heater element of the aftertreatment intake gas second sensor, either NOx or O2, is within the manufacturer’s specified range for accurate measurements in exhaust bank 2.
For a single exhaust bank system, refer to parameters in ...";
CM_ SG_ 2565925886 GasSnsr2PwrInRange "Indicates that the power supplied to the aftertreatment intake gas second sensor, either NOx or O2, is within the manufacturer’s specification in exhaust bank 2.
For a single exhaust bank system, refer to parameters in PGNs 61454, 61455, 64946, ...";
CM_ SG_ 2565925886 PercentO22 "The actual oxidation factor (percent oxygen) of the gas within the exhaust stream.  For positive values, the parameter represents the percent oxygen in excess of the amount required for stoichiometric combustion.  For negative values, the parameter ...";
CM_ SG_ 2565925886 SCRInNOx2 "The amount of combined NO and NO2 in the exhaust entering the aftertreatment system measured by the second NOx sensor at the aftertreatment intake, represented in NOx molecule parts per million non-NOx molecules in exhaust bank 2.
For a single ...";
BA_DEF_  "DBName" STRING ;
BA_DEF_ SG_  "SigType" ENUM  "Default","Range","RangeSigned","ASCII","Discrete","Control","ReferencePGN","DTC","StringDelimiter","StringLength","StringLengthControl","MessageCounter","MessageChecksum";
BA_DEF_ SG_  "GenSigStartValue" INT 0 2147483647;
BA_DEF_ SG_  "GenSigSendType" ENUM  "Cyclic","OnWrite","OnWriteWithRepetition","OnChange","OnChangeWithRepetition","IfActive","IfActiveWithRepetition","NoSigSendType";
BA_DEF_ SG_  "GenSigILSupport" ENUM  "No","Yes";
BA_DEF_ SG_  "GenSigEVName" STRING ;
BA_DEF_ SG_  "SPN" INT 0 524287;
BA_DEF_ BO_  "TpJ1939VarDlc" ENUM  "No","Yes";
BA_DEF_ BO_  "GenMsgStartDelayTime" INT 0 100000;
BA_DEF_ BO_  "GenMsgILSupport" ENUM  "No","Yes";
BA_DEF_ BO_  "GenMsgDelayTime" INT 0 1000;
BA_DEF_ BO_  "GenMsgRequestable" INT 0 1;
BA_DEF_ BO_  "GenMsgSendType" ENUM  "cyclic","NotUsed","NotUsed","NotUsed","NotUsed","NotUsed","NotUsed","IfActive","noMsgSendType";
BA_DEF_ BO_  "VFrameFormat" ENUM  "StandardCAN","ExtendedCAN","reserved","J1939PG";
BA_DEF_ BO_  "GenMsgCycleTime" INT 0 3600000;
BA_DEF_ BU_  "NmStationAddress" INT 0 255;
BA_DEF_ BU_  "NmJ1939IndustryGroup" INT 0 7;
BA_DEF_ BU_  "NmJ1939System" INT 0 127;
BA_DEF_ BU_  "NmJ1939Function" INT 0 255;
BA_DEF_ BU_  "NmJ1939FunctionInstance" INT 0 7;
BA_DEF_ BU_  "NmJ1939ECUInstance" INT 0 3;
BA_DEF_  "SAE_J1939_DA_SpecVersion" STRING ;
BA_DEF_  "SAE_J1939_81_SpecVersion" STRING ;
BA_DEF_  "DatabaseVersion" STRING ;
BA_DEF_  "BusType" STRING ;
BA_DEF_  "ProtocolType" STRING ;
BA_DEF_  "SAE_J1939_75_SpecVersion" STRING ;
BA_DEF_  "SAE_J1939_21_SpecVersion" STRING ;
BA_DEF_  "SAE_J1939_73_SpecVersion" STRING ;
BA_DEF_  "SAE_J1939_71_SpecVersion" STRING ;
BA_DEF_ SG_  "SystemSignalLongSymbol" STRING ;
BA_DEF_DEF_  "DBName" "";
BA_DEF_DEF_  "SigType" "Default";
BA_DEF_DEF_  "GenSigStartValue" 0;
BA_DEF_DEF_  "GenSigSendType" "NoSigSendType";
BA_DEF_DEF_  "GenSigILSupport" "Yes";
BA_DEF_DEF_  "GenSigEVName" "Env@Nodename_@Signame";
BA_DEF_DEF_  "SPN" 0;
BA_DEF_DEF_  "TpJ1939VarDlc" "No";
BA_DEF_DEF_  "GenMsgStartDelayTime" 0;
BA_DEF_DEF_  "GenMsgILSupport" "Yes";
BA_DEF_DEF_  "GenMsgDelayTime" 0;
BA_DEF_DEF_  "GenMsgRequestable" 1;
BA_DEF_DEF_  "GenMsgSendType" "noMsgSendType";
BA_DEF_DEF_  "VFrameFormat" "J1939PG";
BA_DEF_DEF_  "GenMsgCycleTime" 0;
BA_DEF_DEF_  "NmStationAddress" 254;
BA_DEF_DEF_  "NmJ1939IndustryGroup" 0;
BA_DEF_DEF_  "NmJ1939System" 0;
BA_DEF_DEF_  "NmJ1939Function" 0;
BA_DEF_DEF_  "NmJ1939FunctionInstance" 0;
BA_DEF_DEF_  "NmJ1939ECUInstance" 0;
BA_DEF_DEF_  "SAE_J1939_DA_SpecVersion" "";
BA_DEF_DEF_  "SAE_J1939_81_SpecVersion" "";
BA_DEF_DEF_  "DatabaseVersion" "";
BA_DEF_DEF_  "BusType" "";
BA_DEF_DEF_  "ProtocolType" "";
BA_DEF_DEF_  "SAE_J1939_75_SpecVersion" "";
BA_DEF_DEF_  "SAE_J1939_21_SpecVersion" "";
BA_DEF_DEF_  "SAE_J1939_73_SpecVersion" "";
BA_DEF_DEF_  "SAE_J1939_71_SpecVersion" "";
BA_DEF_DEF_  "SystemSignalLongSymbol" "";
BA_ "SAE_J1939_DA_SpecVersion" "2015-01";
BA_ "SAE_J1939_81_SpecVersion" "2012-05";
BA_ "DatabaseVersion" "8.5";
BA_ "BusType" "CAN";
BA_ "ProtocolType" "J1939";
BA_ "SAE_J1939_75_SpecVersion" "2012-05";
BA_ "SAE_J1939_21_SpecVersion" "2006-10";
BA_ "SAE_J1939_73_SpecVersion" "2012-10";
BA_ "SAE_J1939_71_SpecVersion" "2012-10";
BA_ "DBName" "J1939";
BA_ "NmStationAddress" BU_ PowertrainControlModule 90;
BA_ "NmStationAddress" BU_ AtmosphericSensor 89;
BA_ "NmJ1939Function" BU_ AtmosphericSensor 76;
BA_ "NmStationAddress" BU_ SafetyRestraintSystem2 88;
BA_ "NmJ1939Function" BU_ SafetyRestraintSystem2 132;
BA_ "NmJ1939FunctionInstance" BU_ SafetyRestraintSystem2 1;
BA_ "NmStationAddress" BU_ Aftertreatment_2_GasOutlet 87;
BA_ "NmJ1939Function" BU_ Aftertreatment_2_GasOutlet 68;
BA_ "NmJ1939FunctionInstance" BU_ Aftertreatment_2_GasOutlet 1;
BA_ "NmJ1939ECUInstance" BU_ Aftertreatment_2_GasOutlet 1;
BA_ "NmStationAddress" BU_ Aftertreatment_2_GasIntake 86;
BA_ "NmJ1939Function" BU_ Aftertreatment_2_GasIntake 68;
BA_ "NmJ1939FunctionInstance" BU_ Aftertreatment_2_GasIntake 1;
BA_ "NmStationAddress" BU_ DieselParticulateFilterControl 85;
BA_ "NmJ1939Function" BU_ DieselParticulateFilterControl 69;
BA_ "NmStationAddress" BU_ Turbocharger 2;
BA_ "NmJ1939Function" BU_ Turbocharger 133;
BA_ "NmStationAddress" BU_ SafetyRestraintSystem1 83;
BA_ "NmJ1939Function" BU_ SafetyRestraintSystem1 132;
BA_ "NmStationAddress" BU_ CabDisplay2 84;
BA_ "NmJ1939Function" BU_ CabDisplay2 60;
BA_ "NmJ1939FunctionInstance" BU_ CabDisplay2 1;
BA_ "NmStationAddress" BU_ Aftertreatment_1_GasOutlet 82;
BA_ "NmJ1939Function" BU_ Aftertreatment_1_GasOutlet 68;
BA_ "NmJ1939ECUInstance" BU_ Aftertreatment_1_GasOutlet 1;
BA_ "NmStationAddress" BU_ Aftertreatment_1_GasIntake 81;
BA_ "NmJ1939Function" BU_ Aftertreatment_1_GasIntake 68;
BA_ "NmStationAddress" BU_ OnBoardDataLogger 251;
BA_ "NmJ1939Function" BU_ OnBoardDataLogger 130;
BA_ "NmStationAddress" BU_ OffBoardDiagnosticTool2 250;
BA_ "NmJ1939Function" BU_ OffBoardDiagnosticTool2 129;
BA_ "NmJ1939FunctionInstance" BU_ OffBoardDiagnosticTool2 1;
BA_ "NmStationAddress" BU_ OffBoardDiagnosticTool1 249;
BA_ "NmJ1939Function" BU_ OffBoardDiagnosticTool1 129;
BA_ "NmStationAddress" BU_ FileServer 248;
BA_ "NmJ1939Function" BU_ FileServer 61;
BA_ "NmStationAddress" BU_ ParkingBrakeController 80;
BA_ "NmJ1939Function" BU_ ParkingBrakeController 9;
BA_ "NmJ1939FunctionInstance" BU_ ParkingBrakeController 1;
BA_ "NmStationAddress" BU_ SeatController2 79;
BA_ "NmJ1939Function" BU_ SeatController2 40;
BA_ "NmJ1939FunctionInstance" BU_ SeatController2 1;
BA_ "NmStationAddress" BU_ FanDriveController 78;
BA_ "NmJ1939Function" BU_ FanDriveController 58;
BA_ "NmStationAddress" BU_ SteeringColumnUnit 77;
BA_ "NmJ1939Function" BU_ SteeringColumnUnit 57;
BA_ "NmStationAddress" BU_ CommunicationUnitRadio 76;
BA_ "NmJ1939Function" BU_ CommunicationUnitRadio 56;
BA_ "NmStationAddress" BU_ CommunicationUnitSatellite 75;
BA_ "NmJ1939Function" BU_ CommunicationUnitSatellite 55;
BA_ "NmStationAddress" BU_ CommunicationUnitCellular 74;
BA_ "NmJ1939Function" BU_ CommunicationUnitCellular 54;
BA_ "NmStationAddress" BU_ PropulsionBatteryCharger 73;
BA_ "NmJ1939Function" BU_ PropulsionBatteryCharger 31;
BA_ "NmStationAddress" BU_ ChassisController2 72;
BA_ "NmJ1939Function" BU_ ChassisController2 52;
BA_ "NmJ1939FunctionInstance" BU_ ChassisController2 1;
BA_ "NmStationAddress" BU_ ChassisController1 71;
BA_ "NmJ1939Function" BU_ ChassisController1 52;
BA_ "NmStationAddress" BU_ EngineValveControl 70;
BA_ "NmJ1939Function" BU_ EngineValveControl 63;
BA_ "NmStationAddress" BU_ AuxiliaryHeater2 69;
BA_ "NmJ1939Function" BU_ AuxiliaryHeater2 50;
BA_ "NmJ1939FunctionInstance" BU_ AuxiliaryHeater2 1;
BA_ "NmStationAddress" BU_ AuxiliaryHeater1 68;
BA_ "NmJ1939Function" BU_ AuxiliaryHeater1 50;
BA_ "NmStationAddress" BU_ ClutchUnit 67;
BA_ "NmJ1939Function" BU_ ClutchUnit 49;
BA_ "NmStationAddress" BU_ RampControl 66;
BA_ "NmJ1939Function" BU_ RampControl 48;
BA_ "NmStationAddress" BU_ InformationSystem1 65;
BA_ "NmJ1939Function" BU_ InformationSystem1 47;
BA_ "NmStationAddress" BU_ SuspensionSystemController2 64;
BA_ "NmJ1939Function" BU_ SuspensionSystemController2 35;
BA_ "NmJ1939FunctionInstance" BU_ SuspensionSystemController2 1;
BA_ "NmStationAddress" BU_ OilSensor 63;
BA_ "NmJ1939Function" BU_ OilSensor 46;
BA_ "NmStationAddress" BU_ VehicleDynamicStability 62;
BA_ "NmJ1939Function" BU_ VehicleDynamicStability 45;
BA_ "NmStationAddress" BU_ ExhaustEmissionController 61;
BA_ "NmJ1939Function" BU_ ExhaustEmissionController 44;
BA_ "NmStationAddress" BU_ TransmissionDisplay2 60;
BA_ "NmJ1939Function" BU_ TransmissionDisplay2 43;
BA_ "NmJ1939FunctionInstance" BU_ TransmissionDisplay2 1;
BA_ "NmStationAddress" BU_ TransmissionDisplay1 59;
BA_ "NmJ1939Function" BU_ TransmissionDisplay1 43;
BA_ "NmStationAddress" BU_ ClimateControl2 58;
BA_ "NmJ1939Function" BU_ ClimateControl2 21;
BA_ "NmJ1939FunctionInstance" BU_ ClimateControl2 1;
BA_ "NmStationAddress" BU_ WaterPumpController 57;
BA_ "NmJ1939Function" BU_ WaterPumpController 42;
BA_ "NmStationAddress" BU_ RearAxleSteeringController 56;
BA_ "NmJ1939Function" BU_ RearAxleSteeringController 16;
BA_ "NmJ1939FunctionInstance" BU_ RearAxleSteeringController 1;
BA_ "NmStationAddress" BU_ LightingOperatorControl 55;
BA_ "NmJ1939Function" BU_ LightingOperatorControl 41;
BA_ "NmStationAddress" BU_ SeatController1 54;
BA_ "NmJ1939Function" BU_ SeatController1 40;
BA_ "NmStationAddress" BU_ IgnitionController2 53;
BA_ "NmJ1939Function" BU_ IgnitionController2 39;
BA_ "NmJ1939FunctionInstance" BU_ IgnitionController2 1;
BA_ "NmStationAddress" BU_ IgnitionController1 52;
BA_ "NmJ1939Function" BU_ IgnitionController1 39;
BA_ "NmStationAddress" BU_ TirePressureController 51;
BA_ "NmJ1939Function" BU_ TirePressureController 38;
BA_ "NmStationAddress" BU_ CabController2 50;
BA_ "NmJ1939Function" BU_ CabController2 37;
BA_ "NmJ1939FunctionInstance" BU_ CabController2 1;
BA_ "NmStationAddress" BU_ CabController1 49;
BA_ "NmJ1939Function" BU_ CabController1 37;
BA_ "NmStationAddress" BU_ PneumaticSystemController 48;
BA_ "NmJ1939Function" BU_ PneumaticSystemController 36;
BA_ "NmStationAddress" BU_ SuspensionSystemController1 47;
BA_ "NmJ1939Function" BU_ SuspensionSystemController1 35;
BA_ "NmStationAddress" BU_ HydraulicPumpController 46;
BA_ "NmJ1939Function" BU_ HydraulicPumpController 34;
BA_ "NmStationAddress" BU_ EnduranceBrakingSystem 45;
BA_ "NmJ1939Function" BU_ EnduranceBrakingSystem 64;
BA_ "NmStationAddress" BU_ RetarderExhaustEngine2 44;
BA_ "NmJ1939Function" BU_ RetarderExhaustEngine2 12;
BA_ "NmJ1939FunctionInstance" BU_ RetarderExhaustEngine2 1;
BA_ "NmStationAddress" BU_ OnBoardDiagnosticUnit 43;
BA_ "NmJ1939Function" BU_ OnBoardDiagnosticUnit 62;
BA_ "NmStationAddress" BU_ HeadwayController 42;
BA_ "NmJ1939Function" BU_ HeadwayController 32;
BA_ "NmStationAddress" BU_ RetarderExhaustEngine1 41;
BA_ "NmJ1939Function" BU_ RetarderExhaustEngine1 12;
BA_ "NmStationAddress" BU_ CabDisplay1 40;
BA_ "NmJ1939Function" BU_ CabDisplay1 60;
BA_ "NmStationAddress" BU_ ManagementComputer 39;
BA_ "NmJ1939Function" BU_ ManagementComputer 30;
BA_ "NmStationAddress" BU_ VirtualTerminal 38;
BA_ "NmJ1939Function" BU_ VirtualTerminal 29;
BA_ "NmStationAddress" BU_ OffVehicleGateway 37;
BA_ "NmJ1939Function" BU_ OffVehicleGateway 28;
BA_ "NmStationAddress" BU_ PowerTakeOffFront 36;
BA_ "NmJ1939Function" BU_ PowerTakeOffFront 27;
BA_ "NmStationAddress" BU_ HitchControl 35;
BA_ "NmStationAddress" BU_ AuxiliaryValveControl 34;
BA_ "NmJ1939IndustryGroup" BU_ AuxiliaryValveControl 2;
BA_ "NmJ1939System" BU_ AuxiliaryValveControl 1;
BA_ "NmJ1939Function" BU_ AuxiliaryValveControl 129;
BA_ "NmStationAddress" BU_ BodyController 33;
BA_ "NmJ1939Function" BU_ BodyController 26;
BA_ "NmStationAddress" BU_ TractorTrailerBridge1 32;
BA_ "NmJ1939Function" BU_ TractorTrailerBridge1 25;
BA_ "NmStationAddress" BU_ StarterSystem 31;
BA_ "NmJ1939Function" BU_ StarterSystem 59;
BA_ "NmStationAddress" BU_ ElectricalSystem 30;
BA_ "NmJ1939Function" BU_ ElectricalSystem 67;
BA_ "NmStationAddress" BU_ VehicleSecurity 29;
BA_ "NmJ1939Function" BU_ VehicleSecurity 24;
BA_ "NmStationAddress" BU_ VehicleNavigation 28;
BA_ "NmJ1939Function" BU_ VehicleNavigation 23;
BA_ "NmStationAddress" BU_ AerodynamicControl 27;
BA_ "NmJ1939Function" BU_ AerodynamicControl 22;
BA_ "NmStationAddress" BU_ ElectricalChargingSystem 26;
BA_ "NmJ1939Function" BU_ ElectricalChargingSystem 53;
BA_ "NmStationAddress" BU_ ClimateControl1 25;
BA_ "NmJ1939Function" BU_ ClimateControl1 21;
BA_ "NmStationAddress" BU_ TripRecorder 24;
BA_ "NmJ1939Function" BU_ TripRecorder 20;
BA_ "NmStationAddress" BU_ InstrumentCluster 23;
BA_ "NmJ1939Function" BU_ InstrumentCluster 19;
BA_ "NmStationAddress" BU_ SuspensionDriveAxle2 22;
BA_ "NmJ1939Function" BU_ SuspensionDriveAxle2 18;
BA_ "NmJ1939FunctionInstance" BU_ SuspensionDriveAxle2 1;
BA_ "NmStationAddress" BU_ SuspensionDriveAxle1 21;
BA_ "NmJ1939Function" BU_ SuspensionDriveAxle1 18;
BA_ "NmStationAddress" BU_ SuspensionSteerAxle 20;
BA_ "NmJ1939Function" BU_ SuspensionSteerAxle 17;
BA_ "NmStationAddress" BU_ SteeringController 19;
BA_ "NmJ1939Function" BU_ SteeringController 16;
BA_ "NmStationAddress" BU_ FuelSystem 18;
BA_ "NmJ1939Function" BU_ FuelSystem 15;
BA_ "NmStationAddress" BU_ CruiseControl 17;
BA_ "NmJ1939Function" BU_ CruiseControl 14;
BA_ "NmStationAddress" BU_ RetarderDriveline 16;
BA_ "NmJ1939Function" BU_ RetarderDriveline 13;
BA_ "NmStationAddress" BU_ RetarderEngine 15;
BA_ "NmJ1939Function" BU_ RetarderEngine 12;
BA_ "NmStationAddress" BU_ BrakesDriveAxle2 14;
BA_ "NmJ1939Function" BU_ BrakesDriveAxle2 11;
BA_ "NmJ1939FunctionInstance" BU_ BrakesDriveAxle2 1;
BA_ "NmStationAddress" BU_ BrakesDriveAxle1 13;
BA_ "NmJ1939Function" BU_ BrakesDriveAxle1 11;
BA_ "NmStationAddress" BU_ BrakesSystemController 11;
BA_ "NmJ1939Function" BU_ BrakesSystemController 9;
BA_ "NmStationAddress" BU_ BrakesSteerAxle 12;
BA_ "NmJ1939Function" BU_ BrakesSteerAxle 10;
BA_ "NmStationAddress" BU_ AxleDrive2 10;
BA_ "NmJ1939Function" BU_ AxleDrive2 8;
BA_ "NmJ1939FunctionInstance" BU_ AxleDrive2 1;
BA_ "NmStationAddress" BU_ AxleDrive1 9;
BA_ "NmJ1939Function" BU_ AxleDrive1 8;
BA_ "NmStationAddress" BU_ AxleSteering 8;
BA_ "NmJ1939Function" BU_ AxleSteering 7;
BA_ "NmStationAddress" BU_ PowerTakeOff 7;
BA_ "NmJ1939Function" BU_ PowerTakeOff 6;
BA_ "NmStationAddress" BU_ ShiftConsoleSecondary 6;
BA_ "NmJ1939Function" BU_ ShiftConsoleSecondary 5;
BA_ "NmJ1939FunctionInstance" BU_ ShiftConsoleSecondary 1;
BA_ "NmStationAddress" BU_ ShiftConsolePrimary 5;
BA_ "NmJ1939Function" BU_ ShiftConsolePrimary 5;
BA_ "NmStationAddress" BU_ Transmission2 4;
BA_ "NmJ1939Function" BU_ Transmission2 3;
BA_ "NmJ1939FunctionInstance" BU_ Transmission2 1;
BA_ "NmStationAddress" BU_ Transmission1 3;
BA_ "NmJ1939Function" BU_ Transmission1 3;
BA_ "NmStationAddress" BU_ Engine2 1;
BA_ "NmJ1939FunctionInstance" BU_ Engine2 1;
BA_ "NmStationAddress" BU_ Engine1 0;
BA_ "GenMsgSendType" BO_ 2566658558 0;
BA_ "GenMsgCycleTime" BO_ 2566658558 5000;
BA_ "GenMsgSendType" BO_ 2566658302 0;
BA_ "GenMsgCycleTime" BO_ 2566658302 5000;
BA_ "GenMsgSendType" BO_ 2499549182 0;
BA_ "GenMsgCycleTime" BO_ 2499549182 1000;
BA_ "GenMsgSendType" BO_ 2499548926 0;
BA_ "GenMsgCycleTime" BO_ 2499548926 1000;
BA_ "GenMsgSendType" BO_ 2499548670 0;
BA_ "GenMsgCycleTime" BO_ 2499548670 100;
BA_ "GenMsgDelayTime" BO_ 2499548158 100;
BA_ "GenMsgSendType" BO_ 2499548158 0;
BA_ "GenMsgCycleTime" BO_ 2499548158 1000;
BA_ "GenMsgDelayTime" BO_ 2499547902 100;
BA_ "GenMsgSendType" BO_ 2499547902 0;
BA_ "GenMsgCycleTime" BO_ 2499547902 1000;
BA_ "GenMsgDelayTime" BO_ 2431710718 20;
BA_ "GenMsgDelayTime" BO_ 2431708670 20;
BA_ "GenMsgSendType" BO_ 2565926142 0;
BA_ "GenMsgCycleTime" BO_ 2565926142 50;
BA_ "GenMsgSendType" BO_ 2565925886 0;
BA_ "GenMsgCycleTime" BO_ 2565925886 50;
BA_ "SigType" SG_ 3221225472 NumberOfMembersInWorkingSet 3;
BA_ "SPN" SG_ 3221225472 NumberOfMembersInWorkingSet 2409;
BA_ "SPN" SG_ 3221225472 SourceAddress 5600;
BA_ "SPN" SG_ 3221225472 NncntnuslyMonitoredSystemsStatus 1223;
BA_ "SPN" SG_ 3221225472 NncntnslyMonitoredSystemsSupport 1222;
BA_ "SPN" SG_ 3221225472 CntnslyMntrdSystmsSupport_Status 1221;
BA_ "SigType" SG_ 3221225472 AETCTorqueValue 1;
BA_ "SPN" SG_ 3221225472 AETCTorqueValue 3561;
BA_ "SigType" SG_ 3221225472 TrailerWeight 1;
BA_ "SPN" SG_ 3221225472 TrailerWeight 180;
BA_ "SPN" SG_ 3221225472 ReferenceTirePressSetting 3193;
BA_ "SPN" SG_ 3221225472 ReferenceTirePress 3191;
BA_ "SPN" SG_ 3221225472 TirePressThresholdDetection 2587;
BA_ "SigType" SG_ 3221225472 TireAirLeakageRate 1;
BA_ "SPN" SG_ 3221225472 TireAirLeakageRate 2586;
BA_ "SigType" SG_ 3221225472 CTIWheelEndElectricalFault 4;
BA_ "SPN" SG_ 3221225472 CTIWheelEndElectricalFault 1697;
BA_ "SigType" SG_ 3221225472 CTITireStatus 4;
BA_ "SPN" SG_ 3221225472 CTITireStatus 1698;
BA_ "SigType" SG_ 3221225472 CTIWheelSensorStatus 4;
BA_ "SPN" SG_ 3221225472 CTIWheelSensorStatus 1699;
BA_ "SigType" SG_ 3221225472 TireTemp 1;
BA_ "SPN" SG_ 3221225472 TireTemp 242;
BA_ "SigType" SG_ 3221225472 TirePress 1;
BA_ "SPN" SG_ 3221225472 TirePress 241;
BA_ "SigType" SG_ 3221225472 EngTurningGearEngaged 4;
BA_ "SPN" SG_ 3221225472 EngTurningGearEngaged 1206;
BA_ "SigType" SG_ 3221225472 AETCSpeedValue 1;
BA_ "SPN" SG_ 3221225472 AETCSpeedValue 3560;
BA_ "SigType" SG_ 3221225472 TimeBetweenRegens 1;
BA_ "SPN" SG_ 3221225472 TimeBetweenRegens 6776;
BA_ "SigType" SG_ 3221225472 ActiveAccumulationTime 1;
BA_ "SPN" SG_ 3221225472 ActiveAccumulationTime 6775;
BA_ "SPN" SG_ 3221225472 RegenSt 6774;
BA_ "SigType" SG_ 3221225472 RegenStatus 5;
BA_ "SPN" SG_ 3221225472 RegenStatus 5460;
BA_ "SigType" SG_ 3221225472 HtrSt 5;
BA_ "SPN" SG_ 3221225472 HtrSt 6772;
BA_ "SigType" SG_ 3221225472 Res 1;
BA_ "SPN" SG_ 3221225472 Res 6771;
BA_ "SigType" SG_ 3221225472 HtrRes 1;
BA_ "SPN" SG_ 3221225472 HtrRes 7070;
BA_ "SigType" SG_ 3221225472 MaxRes 1;
BA_ "SPN" SG_ 3221225472 MaxRes 6781;
BA_ "SigType" SG_ 3221225472 Temp 1;
BA_ "SPN" SG_ 3221225472 Temp 6780;
BA_ "SigType" SG_ 3221225472 RegenFailedCount 1;
BA_ "SPN" SG_ 3221225472 RegenFailedCount 6779;
BA_ "SigType" SG_ 3221225472 PwrSupply 4;
BA_ "SPN" SG_ 3221225472 PwrSupply 6778;
BA_ "SPN" SG_ 3221225472 DetectionStatus 6777;
BA_ "SigType" SG_ 3221225472 SCRSysAvgDistBetweenCleanEvents 1;
BA_ "SPN" SG_ 3221225472 SCRSysAvgDistBetweenCleanEvents 6940;
BA_ "SigType" SG_ 3221225472 SCRSysAvgTimeBetweenCleanEvents 1;
BA_ "SPN" SG_ 3221225472 SCRSysAvgTimeBetweenCleanEvents 6939;
BA_ "SigType" SG_ 3221225472 SCRSysTotalSysCleanManReq 1;
BA_ "SPN" SG_ 3221225472 SCRSysTotalSysCleanManReq 6938;
BA_ "SigType" SG_ 3221225472 SCRSysTotalSysCleanInhReq 1;
BA_ "SPN" SG_ 3221225472 SCRSysTotalSysCleanInhReq 6937;
BA_ "SigType" SG_ 3221225472 SCRSysTotalSysCleanEvents 1;
BA_ "SPN" SG_ 3221225472 SCRSysTotalSysCleanEvents 6936;
BA_ "SigType" SG_ 3221225472 SCRSysTotalCleanTime 1;
BA_ "SPN" SG_ 3221225472 SCRSysTotalCleanTime 6935;
BA_ "SPN" SG_ 3221225472 HtrPwrSupplyDiagnosticStatus 7330;
BA_ "SPN" SG_ 3221225472 HtrPwrSupplyPreliminaryFMI 7329;
BA_ "SPN" SG_ 3221225472 PwrSupplyDiagnosticStatus 7328;
BA_ "SPN" SG_ 3221225472 PwrSupplyPreliminaryFMI 7327;
BA_ "SPN" SG_ 3221225472 InputDiagnosticStatus 7326;
BA_ "SPN" SG_ 3221225472 InputPreliminaryFMI 7325;
BA_ "SPN" SG_ 3221225472 HtrLowSideDriverDiagnosticStatus 7324;
BA_ "SPN" SG_ 3221225472 HtrLowSideDriverPreliminaryFMI 7323;
BA_ "SPN" SG_ 3221225472 HtrHiSideDriverDiagnosticStatus 7322;
BA_ "SPN" SG_ 3221225472 HtrHiSideDriverPreliminaryFMI 7321;
BA_ "SigType" SG_ 3221225472 ExhVelocity 1;
BA_ "SPN" SG_ 3221225472 ExhVelocity 6829;
BA_ "SigType" SG_ 3221225472 ExhTemp 1;
BA_ "SPN" SG_ 3221225472 ExhTemp 6785;
BA_ "SigType" SG_ 3221225472 Dewpoint 5;
BA_ "SPN" SG_ 3221225472 Dewpoint 6784;
BA_ "SigType" SG_ 3221225472 RegenReq 5;
BA_ "SPN" SG_ 3221225472 RegenReq 6783;
BA_ "SigType" SG_ 3221225472 ShutdownReq 5;
BA_ "SPN" SG_ 3221225472 ShutdownReq 6782;
BA_ "SPN" SG_ 3221225472 RqToPermitDEFDosingTestInjection 7516;
BA_ "SigType" SG_ 3221225472 RqToPermitDEFHydStiffnessCheck 5;
BA_ "SPN" SG_ 3221225472 RqToPermitDEFHydStiffnessCheck 7515;
BA_ "SigType" SG_ 3221225472 ThermalManagementInhReq 5;
BA_ "SPN" SG_ 3221225472 ThermalManagementInhReq 7331;
BA_ "SigType" SG_ 3221225472 DesulfationStatus 5;
BA_ "SPN" SG_ 3221225472 DesulfationStatus 5462;
BA_ "SigType" SG_ 3221225472 SCRSysAvgDistBetweenCleanEvents 1;
BA_ "SPN" SG_ 3221225472 SCRSysAvgDistBetweenCleanEvents 6947;
BA_ "SigType" SG_ 3221225472 SCRSysAvgTimeBetweenCleanEvents 1;
BA_ "SPN" SG_ 3221225472 SCRSysAvgTimeBetweenCleanEvents 6946;
BA_ "SigType" SG_ 3221225472 SCRSysTotalSysCleanManReq 1;
BA_ "SPN" SG_ 3221225472 SCRSysTotalSysCleanManReq 6945;
BA_ "SigType" SG_ 3221225472 SCRSysTotalSysCleanInhReq 1;
BA_ "SPN" SG_ 3221225472 SCRSysTotalSysCleanInhReq 6944;
BA_ "SigType" SG_ 3221225472 SCRSysTotalSysCleanEvents 1;
BA_ "SPN" SG_ 3221225472 SCRSysTotalSysCleanEvents 6943;
BA_ "SigType" SG_ 3221225472 SCRSysTotalSysCleanTime 1;
BA_ "SPN" SG_ 3221225472 SCRSysTotalSysCleanTime 6942;
BA_ "SigType" SG_ 3221225472 Ctrl2Temp 1;
BA_ "SPN" SG_ 3221225472 Ctrl2Temp 7535;
BA_ "SigType" SG_ 3221225472 CtrlTemp 1;
BA_ "SPN" SG_ 3221225472 CtrlTemp 7529;
BA_ "SigType" SG_ 3221225472 Htr2 1;
BA_ "SPN" SG_ 3221225472 Htr2 7575;
BA_ "SigType" SG_ 3221225472 Temp2 1;
BA_ "SPN" SG_ 3221225472 Temp2 7574;
BA_ "SigType" SG_ 3221225472 Volume2 1;
BA_ "SPN" SG_ 3221225472 Volume2 7531;
BA_ "SigType" SG_ 3221225472 FusedOutput29 4;
BA_ "SPN" SG_ 3221225472 FusedOutput29 6047;
BA_ "SigType" SG_ 3221225472 FusedOutput30 4;
BA_ "SPN" SG_ 3221225472 FusedOutput30 6046;
BA_ "SigType" SG_ 3221225472 FusedOutput31 4;
BA_ "SPN" SG_ 3221225472 FusedOutput31 6045;
BA_ "SigType" SG_ 3221225472 FusedOutput32 4;
BA_ "SPN" SG_ 3221225472 FusedOutput32 6044;
BA_ "SigType" SG_ 3221225472 FusedOutput25 4;
BA_ "SPN" SG_ 3221225472 FusedOutput25 6043;
BA_ "SigType" SG_ 3221225472 FusedOutput26 4;
BA_ "SPN" SG_ 3221225472 FusedOutput26 6042;
BA_ "SigType" SG_ 3221225472 FusedOutput27 4;
BA_ "SPN" SG_ 3221225472 FusedOutput27 6041;
BA_ "SigType" SG_ 3221225472 FusedOutput28 4;
BA_ "SPN" SG_ 3221225472 FusedOutput28 6040;
BA_ "SigType" SG_ 3221225472 FusedOutput21 4;
BA_ "SPN" SG_ 3221225472 FusedOutput21 6039;
BA_ "SigType" SG_ 3221225472 FusedOutput22 4;
BA_ "SPN" SG_ 3221225472 FusedOutput22 6038;
BA_ "SigType" SG_ 3221225472 FusedOutput23 4;
BA_ "SPN" SG_ 3221225472 FusedOutput23 6037;
BA_ "SigType" SG_ 3221225472 FusedOutput24 4;
BA_ "SPN" SG_ 3221225472 FusedOutput24 6036;
BA_ "SigType" SG_ 3221225472 FusedOutput17 4;
BA_ "SPN" SG_ 3221225472 FusedOutput17 6035;
BA_ "SigType" SG_ 3221225472 FusedOutput18 4;
BA_ "SPN" SG_ 3221225472 FusedOutput18 6034;
BA_ "SigType" SG_ 3221225472 FusedOutput19 4;
BA_ "SPN" SG_ 3221225472 FusedOutput19 6033;
BA_ "SigType" SG_ 3221225472 FusedOutput20 4;
BA_ "SPN" SG_ 3221225472 FusedOutput20 6032;
BA_ "SigType" SG_ 3221225472 FusedOutput13 4;
BA_ "SPN" SG_ 3221225472 FusedOutput13 6031;
BA_ "SigType" SG_ 3221225472 FusedOutput14 4;
BA_ "SPN" SG_ 3221225472 FusedOutput14 6030;
BA_ "SigType" SG_ 3221225472 FusedOutput15 4;
BA_ "SPN" SG_ 3221225472 FusedOutput15 6029;
BA_ "SigType" SG_ 3221225472 FusedOutput16 4;
BA_ "SPN" SG_ 3221225472 FusedOutput16 6028;
BA_ "SigType" SG_ 3221225472 FusedOutput9 4;
BA_ "SPN" SG_ 3221225472 FusedOutput9 6027;
BA_ "SigType" SG_ 3221225472 FusedOutput10 4;
BA_ "SPN" SG_ 3221225472 FusedOutput10 6026;
BA_ "SigType" SG_ 3221225472 FusedOutput11 4;
BA_ "SPN" SG_ 3221225472 FusedOutput11 6025;
BA_ "SigType" SG_ 3221225472 FusedOutput12 4;
BA_ "SPN" SG_ 3221225472 FusedOutput12 6024;
BA_ "SigType" SG_ 3221225472 FusedOutput5 4;
BA_ "SPN" SG_ 3221225472 FusedOutput5 6023;
BA_ "SigType" SG_ 3221225472 FusedOutput6 4;
BA_ "SPN" SG_ 3221225472 FusedOutput6 6022;
BA_ "SigType" SG_ 3221225472 FusedOutput7 4;
BA_ "SPN" SG_ 3221225472 FusedOutput7 6021;
BA_ "SigType" SG_ 3221225472 FusedOutput8 4;
BA_ "SPN" SG_ 3221225472 FusedOutput8 6020;
BA_ "SigType" SG_ 3221225472 FusedOutput1 4;
BA_ "SPN" SG_ 3221225472 FusedOutput1 6019;
BA_ "SigType" SG_ 3221225472 FusedOutput2 4;
BA_ "SPN" SG_ 3221225472 FusedOutput2 6018;
BA_ "SigType" SG_ 3221225472 FusedOutput3 4;
BA_ "SPN" SG_ 3221225472 FusedOutput3 6017;
BA_ "SigType" SG_ 3221225472 FusedOutput4 4;
BA_ "SPN" SG_ 3221225472 FusedOutput4 6016;
BA_ "SigType" SG_ 3221225472 SwitchedOutput29 5;
BA_ "SPN" SG_ 3221225472 SwitchedOutput29 6079;
BA_ "SigType" SG_ 3221225472 SwitchedOutput30 5;
BA_ "SPN" SG_ 3221225472 SwitchedOutput30 6078;
BA_ "SigType" SG_ 3221225472 SwitchedOutput31 5;
BA_ "SPN" SG_ 3221225472 SwitchedOutput31 6077;
BA_ "SigType" SG_ 3221225472 SwitchedOutput32 5;
BA_ "SPN" SG_ 3221225472 SwitchedOutput32 6076;
BA_ "SigType" SG_ 3221225472 SwitchedOutput25 5;
BA_ "SPN" SG_ 3221225472 SwitchedOutput25 6075;
BA_ "SigType" SG_ 3221225472 SwitchedOutput26 5;
BA_ "SPN" SG_ 3221225472 SwitchedOutput26 6074;
BA_ "SigType" SG_ 3221225472 SwitchedOutput27 5;
BA_ "SPN" SG_ 3221225472 SwitchedOutput27 6073;
BA_ "SigType" SG_ 3221225472 SwitchedOutput28 5;
BA_ "SPN" SG_ 3221225472 SwitchedOutput28 6072;
BA_ "SigType" SG_ 3221225472 SwitchedOutput21 5;
BA_ "SPN" SG_ 3221225472 SwitchedOutput21 6071;
BA_ "SigType" SG_ 3221225472 SwitchedOutput22 5;
BA_ "SPN" SG_ 3221225472 SwitchedOutput22 6070;
BA_ "SigType" SG_ 3221225472 SwitchedOutput23 5;
BA_ "SPN" SG_ 3221225472 SwitchedOutput23 6069;
BA_ "SigType" SG_ 3221225472 SwitchedOutput24 5;
BA_ "SPN" SG_ 3221225472 SwitchedOutput24 6068;
BA_ "SigType" SG_ 3221225472 SwitchedOutput17 5;
BA_ "SPN" SG_ 3221225472 SwitchedOutput17 6067;
BA_ "SigType" SG_ 3221225472 SwitchedOutput18 5;
BA_ "SPN" SG_ 3221225472 SwitchedOutput18 6066;
BA_ "SigType" SG_ 3221225472 SwitchedOutput19 5;
BA_ "SPN" SG_ 3221225472 SwitchedOutput19 6065;
BA_ "SigType" SG_ 3221225472 SwitchedOutput20 5;
BA_ "SPN" SG_ 3221225472 SwitchedOutput20 6064;
BA_ "SigType" SG_ 3221225472 SwitchedOutput13 5;
BA_ "SPN" SG_ 3221225472 SwitchedOutput13 6063;
BA_ "SigType" SG_ 3221225472 SwitchedOutput14 5;
BA_ "SPN" SG_ 3221225472 SwitchedOutput14 6062;
BA_ "SigType" SG_ 3221225472 SwitchedOutput15 5;
BA_ "SPN" SG_ 3221225472 SwitchedOutput15 6061;
BA_ "SigType" SG_ 3221225472 SwitchedOutput16 5;
BA_ "SPN" SG_ 3221225472 SwitchedOutput16 6060;
BA_ "SigType" SG_ 3221225472 SwitchedOutput9 5;
BA_ "SPN" SG_ 3221225472 SwitchedOutput9 6059;
BA_ "SigType" SG_ 3221225472 SwitchedOutput10 5;
BA_ "SPN" SG_ 3221225472 SwitchedOutput10 6058;
BA_ "SigType" SG_ 3221225472 SwitchedOutput11 5;
BA_ "SPN" SG_ 3221225472 SwitchedOutput11 6057;
BA_ "SigType" SG_ 3221225472 SwitchedOutput12 5;
BA_ "SPN" SG_ 3221225472 SwitchedOutput12 6056;
BA_ "SigType" SG_ 3221225472 SwitchedOutput5 5;
BA_ "SPN" SG_ 3221225472 SwitchedOutput5 6055;
BA_ "SigType" SG_ 3221225472 SwitchedOutput6 5;
BA_ "SPN" SG_ 3221225472 SwitchedOutput6 6054;
BA_ "SigType" SG_ 3221225472 SwitchedOutput7 5;
BA_ "SPN" SG_ 3221225472 SwitchedOutput7 6053;
BA_ "SigType" SG_ 3221225472 SwitchedOutput8 5;
BA_ "SPN" SG_ 3221225472 SwitchedOutput8 6052;
BA_ "SigType" SG_ 3221225472 SwitchedOutput1 5;
BA_ "SPN" SG_ 3221225472 SwitchedOutput1 6051;
BA_ "SigType" SG_ 3221225472 SwitchedOutput2 5;
BA_ "SPN" SG_ 3221225472 SwitchedOutput2 6050;
BA_ "SigType" SG_ 3221225472 SwitchedOutput3 5;
BA_ "SPN" SG_ 3221225472 SwitchedOutput3 6049;
BA_ "SigType" SG_ 3221225472 SwitchedOutput4 5;
BA_ "SPN" SG_ 3221225472 SwitchedOutput4 6048;
BA_ "SigType" SG_ 3221225472 SwitchedPowerOutput18Cmd 5;
BA_ "SPN" SG_ 3221225472 SwitchedPowerOutput18Cmd 6002;
BA_ "SigType" SG_ 3221225472 SwitchedPowerOutput19Cmd 5;
BA_ "SPN" SG_ 3221225472 SwitchedPowerOutput19Cmd 6001;
BA_ "SigType" SG_ 3221225472 SwitchedPowerOutput20Cmd 5;
BA_ "SPN" SG_ 3221225472 SwitchedPowerOutput20Cmd 6000;
BA_ "SigType" SG_ 3221225472 SwitchedPowerOutput13Cmd 5;
BA_ "SPN" SG_ 3221225472 SwitchedPowerOutput13Cmd 5999;
BA_ "SigType" SG_ 3221225472 SwitchedPowerOutput14Cmd 5;
BA_ "SPN" SG_ 3221225472 SwitchedPowerOutput14Cmd 5998;
BA_ "SigType" SG_ 3221225472 SwitchedPowerOutput15Cmd 5;
BA_ "SPN" SG_ 3221225472 SwitchedPowerOutput15Cmd 5997;
BA_ "SigType" SG_ 3221225472 SwitchedPowerOutput16Cmd 5;
BA_ "SPN" SG_ 3221225472 SwitchedPowerOutput16Cmd 5996;
BA_ "SigType" SG_ 3221225472 SwitchedPowerOutput9Cmd 5;
BA_ "SPN" SG_ 3221225472 SwitchedPowerOutput9Cmd 5995;
BA_ "SigType" SG_ 3221225472 SwitchedPowerOutput10Cmd 5;
BA_ "SPN" SG_ 3221225472 SwitchedPowerOutput10Cmd 5994;
BA_ "SigType" SG_ 3221225472 SwitchedPowerOutput29Cmd 5;
BA_ "SPN" SG_ 3221225472 SwitchedPowerOutput29Cmd 6015;
BA_ "SigType" SG_ 3221225472 SwitchedPowerOutput30Cmd 5;
BA_ "SPN" SG_ 3221225472 SwitchedPowerOutput30Cmd 6014;
BA_ "SigType" SG_ 3221225472 SwitchedPowerOutput31Cmd 5;
BA_ "SPN" SG_ 3221225472 SwitchedPowerOutput31Cmd 6013;
BA_ "SigType" SG_ 3221225472 SwitchedPowerOutput32Cmd 5;
BA_ "SPN" SG_ 3221225472 SwitchedPowerOutput32Cmd 6012;
BA_ "SigType" SG_ 3221225472 SwitchedPowerOutput25Cmd 5;
BA_ "SPN" SG_ 3221225472 SwitchedPowerOutput25Cmd 6011;
BA_ "SigType" SG_ 3221225472 SwitchedPowerOutput26Cmd 5;
BA_ "SPN" SG_ 3221225472 SwitchedPowerOutput26Cmd 6010;
BA_ "SigType" SG_ 3221225472 SwitchedPowerOutput27Cmd 5;
BA_ "SPN" SG_ 3221225472 SwitchedPowerOutput27Cmd 6009;
BA_ "SigType" SG_ 3221225472 SwitchedPowerOutput28Cmd 5;
BA_ "SPN" SG_ 3221225472 SwitchedPowerOutput28Cmd 6008;
BA_ "SigType" SG_ 3221225472 SwitchedPowerOutput21Cmd 5;
BA_ "SPN" SG_ 3221225472 SwitchedPowerOutput21Cmd 6007;
BA_ "SigType" SG_ 3221225472 SwitchedPowerOutput22Cmd 5;
BA_ "SPN" SG_ 3221225472 SwitchedPowerOutput22Cmd 6006;
BA_ "SigType" SG_ 3221225472 SwitchedPowerOutput23Cmd 5;
BA_ "SPN" SG_ 3221225472 SwitchedPowerOutput23Cmd 6005;
BA_ "SigType" SG_ 3221225472 SwitchedPowerOutput24Cmd 5;
BA_ "SPN" SG_ 3221225472 SwitchedPowerOutput24Cmd 6004;
BA_ "SigType" SG_ 3221225472 SwitchedPowerOutput17Cmd 5;
BA_ "SPN" SG_ 3221225472 SwitchedPowerOutput17Cmd 6003;
BA_ "SigType" SG_ 3221225472 SwitchedPowerOutput11Cmd 5;
BA_ "SPN" SG_ 3221225472 SwitchedPowerOutput11Cmd 5993;
BA_ "SigType" SG_ 3221225472 SwitchedPowerOutput12Cmd 5;
BA_ "SPN" SG_ 3221225472 SwitchedPowerOutput12Cmd 5992;
BA_ "SigType" SG_ 3221225472 SwitchedPowerOutput5Cmd 5;
BA_ "SPN" SG_ 3221225472 SwitchedPowerOutput5Cmd 5991;
BA_ "SigType" SG_ 3221225472 SwitchedPowerOutput6Cmd 5;
BA_ "SPN" SG_ 3221225472 SwitchedPowerOutput6Cmd 5990;
BA_ "SigType" SG_ 3221225472 SwitchedPowerOutput7Cmd 5;
BA_ "SPN" SG_ 3221225472 SwitchedPowerOutput7Cmd 5989;
BA_ "SigType" SG_ 3221225472 SwitchedPowerOutput8Cmd 5;
BA_ "SPN" SG_ 3221225472 SwitchedPowerOutput8Cmd 5988;
BA_ "SigType" SG_ 3221225472 SwitchedPowerOutput1Cmd 5;
BA_ "SPN" SG_ 3221225472 SwitchedPowerOutput1Cmd 5987;
BA_ "SigType" SG_ 3221225472 SwitchedPowerOutput2Cmd 5;
BA_ "SPN" SG_ 3221225472 SwitchedPowerOutput2Cmd 5986;
BA_ "SigType" SG_ 3221225472 SwitchedPowerOutput3Cmd 5;
BA_ "SPN" SG_ 3221225472 SwitchedPowerOutput3Cmd 5985;
BA_ "SigType" SG_ 3221225472 SwitchedPowerOutput4Cmd 5;
BA_ "SPN" SG_ 3221225472 SwitchedPowerOutput4Cmd 5984;
BA_ "SigType" SG_ 3221225472 SpecialIgnitorLoop90Resistance 1;
BA_ "SPN" SG_ 3221225472 SpecialIgnitorLoop90Resistance 4917;
BA_ "SigType" SG_ 3221225472 SpecialIgnitorLoop89Resistance 1;
BA_ "SPN" SG_ 3221225472 SpecialIgnitorLoop89Resistance 4916;
BA_ "SigType" SG_ 3221225472 SpecialIgnitorLoop88Resistance 1;
BA_ "SPN" SG_ 3221225472 SpecialIgnitorLoop88Resistance 4915;
BA_ "SigType" SG_ 3221225472 SpecialIgnitorLoop87Resistance 1;
BA_ "SPN" SG_ 3221225472 SpecialIgnitorLoop87Resistance 4914;
BA_ "SigType" SG_ 3221225472 SpecialIgnitorLoop86Resistance 1;
BA_ "SPN" SG_ 3221225472 SpecialIgnitorLoop86Resistance 4913;
BA_ "SigType" SG_ 3221225472 SpecialIgnitorLoop85Resistance 1;
BA_ "SPN" SG_ 3221225472 SpecialIgnitorLoop85Resistance 4912;
BA_ "SigType" SG_ 3221225472 SpecialIgnitorLoop84Resistance 1;
BA_ "SPN" SG_ 3221225472 SpecialIgnitorLoop84Resistance 4911;
BA_ "SigType" SG_ 3221225472 SpecialIgnitorLoop83Resistance 1;
BA_ "SPN" SG_ 3221225472 SpecialIgnitorLoop83Resistance 4910;
BA_ "SigType" SG_ 3221225472 SpecialIgnitorLoop82Resistance 1;
BA_ "SPN" SG_ 3221225472 SpecialIgnitorLoop82Resistance 4909;
BA_ "SigType" SG_ 3221225472 SpecialIgnitorLoop81Resistance 1;
BA_ "SPN" SG_ 3221225472 SpecialIgnitorLoop81Resistance 4908;
BA_ "SigType" SG_ 3221225472 SpecialIgnitorLoop80Resistance 1;
BA_ "SPN" SG_ 3221225472 SpecialIgnitorLoop80Resistance 4907;
BA_ "SigType" SG_ 3221225472 SpecialIgnitorLoop79Resistance 1;
BA_ "SPN" SG_ 3221225472 SpecialIgnitorLoop79Resistance 4906;
BA_ "SigType" SG_ 3221225472 SpecialIgnitorLoop78Resistance 1;
BA_ "SPN" SG_ 3221225472 SpecialIgnitorLoop78Resistance 4905;
BA_ "SigType" SG_ 3221225472 SpecialIgnitorLoop77Resistance 1;
BA_ "SPN" SG_ 3221225472 SpecialIgnitorLoop77Resistance 4904;
BA_ "SigType" SG_ 3221225472 SpecialIgnitorLoop76Resistance 1;
BA_ "SPN" SG_ 3221225472 SpecialIgnitorLoop76Resistance 4903;
BA_ "SigType" SG_ 3221225472 SpecialIgnitorLoop75Resistance 1;
BA_ "SPN" SG_ 3221225472 SpecialIgnitorLoop75Resistance 4902;
BA_ "SigType" SG_ 3221225472 SpecialIgnitorLoop74Resistance 1;
BA_ "SPN" SG_ 3221225472 SpecialIgnitorLoop74Resistance 4901;
BA_ "SigType" SG_ 3221225472 SpecialIgnitorLoop73Resistance 1;
BA_ "SPN" SG_ 3221225472 SpecialIgnitorLoop73Resistance 4900;
BA_ "SigType" SG_ 3221225472 SpecialIgnitorLoop72Resistance 1;
BA_ "SPN" SG_ 3221225472 SpecialIgnitorLoop72Resistance 4899;
BA_ "SigType" SG_ 3221225472 SpecialIgnitorLoop71Resistance 1;
BA_ "SPN" SG_ 3221225472 SpecialIgnitorLoop71Resistance 4898;
BA_ "SigType" SG_ 3221225472 SpecialIgnitorLoop70Resistance 1;
BA_ "SPN" SG_ 3221225472 SpecialIgnitorLoop70Resistance 4897;
BA_ "SigType" SG_ 3221225472 SpecialIgnitorLoop69Resistance 1;
BA_ "SPN" SG_ 3221225472 SpecialIgnitorLoop69Resistance 4896;
BA_ "SigType" SG_ 3221225472 SpecialIgnitorLoop68Resistance 1;
BA_ "SPN" SG_ 3221225472 SpecialIgnitorLoop68Resistance 4895;
BA_ "SigType" SG_ 3221225472 SpecialIgnitorLoop67Resistance 1;
BA_ "SPN" SG_ 3221225472 SpecialIgnitorLoop67Resistance 4894;
BA_ "SigType" SG_ 3221225472 SpecialIgnitorLoop66Resistance 1;
BA_ "SPN" SG_ 3221225472 SpecialIgnitorLoop66Resistance 4893;
BA_ "SigType" SG_ 3221225472 SpecialIgnitorLoop65Resistance 1;
BA_ "SPN" SG_ 3221225472 SpecialIgnitorLoop65Resistance 4892;
BA_ "SigType" SG_ 3221225472 SpecialIgnitorLoop64Resistance 1;
BA_ "SPN" SG_ 3221225472 SpecialIgnitorLoop64Resistance 4891;
BA_ "SigType" SG_ 3221225472 SpecialIgnitorLoop63Resistance 1;
BA_ "SPN" SG_ 3221225472 SpecialIgnitorLoop63Resistance 4890;
BA_ "SigType" SG_ 3221225472 SpecialIgnitorLoop62Resistance 1;
BA_ "SPN" SG_ 3221225472 SpecialIgnitorLoop62Resistance 4889;
BA_ "SigType" SG_ 3221225472 SpecialIgnitorLoop61Resistance 1;
BA_ "SPN" SG_ 3221225472 SpecialIgnitorLoop61Resistance 4888;
BA_ "SigType" SG_ 3221225472 SpecialIgnitorLoop60Resistance 1;
BA_ "SPN" SG_ 3221225472 SpecialIgnitorLoop60Resistance 4887;
BA_ "SigType" SG_ 3221225472 SpecialIgnitorLoop59Resistance 1;
BA_ "SPN" SG_ 3221225472 SpecialIgnitorLoop59Resistance 4886;
BA_ "SigType" SG_ 3221225472 SpecialIgnitorLoop58Resistance 1;
BA_ "SPN" SG_ 3221225472 SpecialIgnitorLoop58Resistance 4885;
BA_ "SigType" SG_ 3221225472 SpecialIgnitorLoop57Resistance 1;
BA_ "SPN" SG_ 3221225472 SpecialIgnitorLoop57Resistance 4884;
BA_ "SigType" SG_ 3221225472 SpecialIgnitorLoop56Resistance 1;
BA_ "SPN" SG_ 3221225472 SpecialIgnitorLoop56Resistance 4883;
BA_ "SigType" SG_ 3221225472 SpecialIgnitorLoop55Resistance 1;
BA_ "SPN" SG_ 3221225472 SpecialIgnitorLoop55Resistance 4882;
BA_ "SigType" SG_ 3221225472 SpecialIgnitorLoop54Resistance 1;
BA_ "SPN" SG_ 3221225472 SpecialIgnitorLoop54Resistance 4881;
BA_ "SigType" SG_ 3221225472 SpecialIgnitorLoop53Resistance 1;
BA_ "SPN" SG_ 3221225472 SpecialIgnitorLoop53Resistance 4880;
BA_ "SigType" SG_ 3221225472 SpecialIgnitorLoop52Resistance 1;
BA_ "SPN" SG_ 3221225472 SpecialIgnitorLoop52Resistance 4879;
BA_ "SigType" SG_ 3221225472 SpecialIgnitorLoop51Resistance 1;
BA_ "SPN" SG_ 3221225472 SpecialIgnitorLoop51Resistance 4878;
BA_ "SigType" SG_ 3221225472 SpecialIgnitorLoop50Resistance 1;
BA_ "SPN" SG_ 3221225472 SpecialIgnitorLoop50Resistance 4877;
BA_ "SigType" SG_ 3221225472 SpecialIgnitorLoop49Resistance 1;
BA_ "SPN" SG_ 3221225472 SpecialIgnitorLoop49Resistance 4876;
BA_ "SigType" SG_ 3221225472 SpecialIgnitorLoop48Resistance 1;
BA_ "SPN" SG_ 3221225472 SpecialIgnitorLoop48Resistance 4875;
BA_ "SigType" SG_ 3221225472 SpecialIgnitorLoop47Resistance 1;
BA_ "SPN" SG_ 3221225472 SpecialIgnitorLoop47Resistance 4874;
BA_ "SigType" SG_ 3221225472 SpecialIgnitorLoop46Resistance 1;
BA_ "SPN" SG_ 3221225472 SpecialIgnitorLoop46Resistance 4873;
BA_ "SigType" SG_ 3221225472 SpecialIgnitorLoop45Resistance 1;
BA_ "SPN" SG_ 3221225472 SpecialIgnitorLoop45Resistance 4872;
BA_ "SigType" SG_ 3221225472 SpecialIgnitorLoop44Resistance 1;
BA_ "SPN" SG_ 3221225472 SpecialIgnitorLoop44Resistance 4871;
BA_ "SigType" SG_ 3221225472 SpecialIgnitorLoop43Resistance 1;
BA_ "SPN" SG_ 3221225472 SpecialIgnitorLoop43Resistance 4870;
BA_ "SigType" SG_ 3221225472 SpecialIgnitorLoop42Resistance 1;
BA_ "SPN" SG_ 3221225472 SpecialIgnitorLoop42Resistance 4869;
BA_ "SigType" SG_ 3221225472 SpecialIgnitorLoop41Resistance 1;
BA_ "SPN" SG_ 3221225472 SpecialIgnitorLoop41Resistance 4868;
BA_ "SigType" SG_ 3221225472 SpecialIgnitorLoop40Resistance 1;
BA_ "SPN" SG_ 3221225472 SpecialIgnitorLoop40Resistance 4867;
BA_ "SigType" SG_ 3221225472 SpecialIgnitorLoop39Resistance 1;
BA_ "SPN" SG_ 3221225472 SpecialIgnitorLoop39Resistance 4866;
BA_ "SigType" SG_ 3221225472 SpecialIgnitorLoop38Resistance 1;
BA_ "SPN" SG_ 3221225472 SpecialIgnitorLoop38Resistance 4865;
BA_ "SigType" SG_ 3221225472 SpecialIgnitorLoop37Resistance 1;
BA_ "SPN" SG_ 3221225472 SpecialIgnitorLoop37Resistance 4864;
BA_ "SigType" SG_ 3221225472 SpecialIgnitorLoop36Resistance 1;
BA_ "SPN" SG_ 3221225472 SpecialIgnitorLoop36Resistance 4863;
BA_ "SigType" SG_ 3221225472 SpecialIgnitorLoop35Resistance 1;
BA_ "SPN" SG_ 3221225472 SpecialIgnitorLoop35Resistance 4862;
BA_ "SigType" SG_ 3221225472 SpecialIgnitorLoop34Resistance 1;
BA_ "SPN" SG_ 3221225472 SpecialIgnitorLoop34Resistance 4861;
BA_ "SigType" SG_ 3221225472 SpecialIgnitorLoop33Resistance 1;
BA_ "SPN" SG_ 3221225472 SpecialIgnitorLoop33Resistance 4860;
BA_ "SigType" SG_ 3221225472 SpecialIgnitorLoop32Resistance 1;
BA_ "SPN" SG_ 3221225472 SpecialIgnitorLoop32Resistance 4859;
BA_ "SigType" SG_ 3221225472 SpecialIgnitorLoop31Resistance 1;
BA_ "SPN" SG_ 3221225472 SpecialIgnitorLoop31Resistance 4858;
BA_ "SigType" SG_ 3221225472 SpecialIgnitorLoop30Resistance 1;
BA_ "SPN" SG_ 3221225472 SpecialIgnitorLoop30Resistance 4857;
BA_ "SigType" SG_ 3221225472 SpecialIgnitorLoop29Resistance 1;
BA_ "SPN" SG_ 3221225472 SpecialIgnitorLoop29Resistance 4856;
BA_ "SigType" SG_ 3221225472 SpecialIgnitorLoop28Resistance 1;
BA_ "SPN" SG_ 3221225472 SpecialIgnitorLoop28Resistance 4855;
BA_ "SigType" SG_ 3221225472 SpecialIgnitorLoop27Resistance 1;
BA_ "SPN" SG_ 3221225472 SpecialIgnitorLoop27Resistance 4854;
BA_ "SigType" SG_ 3221225472 SpecialIgnitorLoop26Resistance 1;
BA_ "SPN" SG_ 3221225472 SpecialIgnitorLoop26Resistance 4853;
BA_ "SigType" SG_ 3221225472 SpecialIgnitorLoop25Resistance 1;
BA_ "SPN" SG_ 3221225472 SpecialIgnitorLoop25Resistance 4852;
BA_ "SigType" SG_ 3221225472 SpecialIgnitorLoop24Resistance 1;
BA_ "SPN" SG_ 3221225472 SpecialIgnitorLoop24Resistance 4851;
BA_ "SigType" SG_ 3221225472 SpecialIgnitorLoop23Resistance 1;
BA_ "SPN" SG_ 3221225472 SpecialIgnitorLoop23Resistance 4850;
BA_ "SigType" SG_ 3221225472 SpecialIgnitorLoop22Resistance 1;
BA_ "SPN" SG_ 3221225472 SpecialIgnitorLoop22Resistance 4849;
BA_ "SigType" SG_ 3221225472 SpecialIgnitorLoop21Resistance 1;
BA_ "SPN" SG_ 3221225472 SpecialIgnitorLoop21Resistance 4848;
BA_ "SigType" SG_ 3221225472 SpecialIgnitorLoop20Resistance 1;
BA_ "SPN" SG_ 3221225472 SpecialIgnitorLoop20Resistance 4847;
BA_ "SigType" SG_ 3221225472 SpecialIgnitorLoop19Resistance 1;
BA_ "SPN" SG_ 3221225472 SpecialIgnitorLoop19Resistance 4846;
BA_ "SigType" SG_ 3221225472 SpecialIgnitorLoop18Resistance 1;
BA_ "SPN" SG_ 3221225472 SpecialIgnitorLoop18Resistance 4845;
BA_ "SigType" SG_ 3221225472 SpecialIgnitorLoop17Resistance 1;
BA_ "SPN" SG_ 3221225472 SpecialIgnitorLoop17Resistance 4844;
BA_ "SigType" SG_ 3221225472 SpecialIgnitorLoop16Resistance 1;
BA_ "SPN" SG_ 3221225472 SpecialIgnitorLoop16Resistance 4843;
BA_ "SigType" SG_ 3221225472 SpecialIgnitorLoop15Resistance 1;
BA_ "SPN" SG_ 3221225472 SpecialIgnitorLoop15Resistance 4842;
BA_ "SigType" SG_ 3221225472 SpecialIgnitorLoop14Resistance 1;
BA_ "SPN" SG_ 3221225472 SpecialIgnitorLoop14Resistance 4841;
BA_ "SigType" SG_ 3221225472 SpecialIgnitorLoop13Resistance 1;
BA_ "SPN" SG_ 3221225472 SpecialIgnitorLoop13Resistance 4840;
BA_ "SigType" SG_ 3221225472 SpecialIgnitorLoop12Resistance 1;
BA_ "SPN" SG_ 3221225472 SpecialIgnitorLoop12Resistance 4839;
BA_ "SigType" SG_ 3221225472 SpecialIgnitorLoop11Resistance 1;
BA_ "SPN" SG_ 3221225472 SpecialIgnitorLoop11Resistance 4838;
BA_ "SigType" SG_ 3221225472 SpecialIgnitorLoop10Resistance 1;
BA_ "SPN" SG_ 3221225472 SpecialIgnitorLoop10Resistance 4837;
BA_ "SigType" SG_ 3221225472 SpecialIgnitorLoop9Resistance 1;
BA_ "SPN" SG_ 3221225472 SpecialIgnitorLoop9Resistance 4836;
BA_ "SigType" SG_ 3221225472 SpecialIgnitorLoop8Resistance 1;
BA_ "SPN" SG_ 3221225472 SpecialIgnitorLoop8Resistance 4835;
BA_ "SigType" SG_ 3221225472 SpecialIgnitorLoop7Resistance 1;
BA_ "SPN" SG_ 3221225472 SpecialIgnitorLoop7Resistance 4834;
BA_ "SigType" SG_ 3221225472 SpecialIgnitorLoop6Resistance 1;
BA_ "SPN" SG_ 3221225472 SpecialIgnitorLoop6Resistance 4833;
BA_ "SigType" SG_ 3221225472 SpecialIgnitorLoop5Resistance 1;
BA_ "SPN" SG_ 3221225472 SpecialIgnitorLoop5Resistance 4832;
BA_ "SigType" SG_ 3221225472 SpecialIgnitorLoop4Resistance 1;
BA_ "SPN" SG_ 3221225472 SpecialIgnitorLoop4Resistance 4831;
BA_ "SigType" SG_ 3221225472 SpecialIgnitorLoop3Resistance 1;
BA_ "SPN" SG_ 3221225472 SpecialIgnitorLoop3Resistance 4830;
BA_ "SigType" SG_ 3221225472 SpecialIgnitorLoop2Resistance 1;
BA_ "SPN" SG_ 3221225472 SpecialIgnitorLoop2Resistance 4829;
BA_ "SigType" SG_ 3221225472 SpecialIgnitorLoop1Resistance 1;
BA_ "SPN" SG_ 3221225472 SpecialIgnitorLoop1Resistance 4828;
BA_ "SigType" SG_ 3221225472 SdBagIgnitorLoop2RightResistance 1;
BA_ "SPN" SG_ 3221225472 SdBagIgnitorLoop2RightResistance 4827;
BA_ "SigType" SG_ 3221225472 SdBagIgnitorLoop1RightResistance 1;
BA_ "SPN" SG_ 3221225472 SdBagIgnitorLoop1RightResistance 4826;
BA_ "SigType" SG_ 3221225472 SdeBagIgnitorLoop2LeftResistance 1;
BA_ "SPN" SG_ 3221225472 SdeBagIgnitorLoop2LeftResistance 4825;
BA_ "SigType" SG_ 3221225472 SdeBagIgnitorLoop1LeftResistance 1;
BA_ "SPN" SG_ 3221225472 SdeBagIgnitorLoop1LeftResistance 4824;
BA_ "SigType" SG_ 3221225472 PssngrBltTnsnrIgntrLopResistance 1;
BA_ "SPN" SG_ 3221225472 PssngrBltTnsnrIgntrLopResistance 4823;
BA_ "SigType" SG_ 3221225472 DrvrBltTnsnrIgntorLoopResistance 1;
BA_ "SPN" SG_ 3221225472 DrvrBltTnsnrIgntorLoopResistance 4822;
BA_ "SigType" SG_ 3221225472 PssngrArbgIgntrLp2ndStgRsistance 1;
BA_ "SPN" SG_ 3221225472 PssngrArbgIgntrLp2ndStgRsistance 4821;
BA_ "SigType" SG_ 3221225472 DrvrArbgIgntrLp2ndStgeResistance 1;
BA_ "SPN" SG_ 3221225472 DrvrArbgIgntrLp2ndStgeResistance 4820;
BA_ "SigType" SG_ 3221225472 PssngrArbgIgntrLp1stStgRsistance 1;
BA_ "SPN" SG_ 3221225472 PssngrArbgIgntrLp1stStgRsistance 4819;
BA_ "SigType" SG_ 3221225472 DrvrArbgIgntrLp1stStgeResistance 1;
BA_ "SPN" SG_ 3221225472 DrvrArbgIgntrLp1stStgeResistance 4818;
BA_ "SigType" SG_ 3221225472 EngTorqueLimit6AxleInput 1;
BA_ "SPN" SG_ 3221225472 EngTorqueLimit6AxleInput 1263;
BA_ "SigType" SG_ 3221225472 EngTorqueLimit5Switch 1;
BA_ "SPN" SG_ 3221225472 EngTorqueLimit5Switch 1262;
BA_ "SigType" SG_ 3221225472 EngTorqueLimit4Trans 1;
BA_ "SPN" SG_ 3221225472 EngTorqueLimit4Trans 1261;
BA_ "SigType" SG_ 3221225472 EngTorqueLimit3Trans 1;
BA_ "SPN" SG_ 3221225472 EngTorqueLimit3Trans 1260;
BA_ "SigType" SG_ 3221225472 TransGearRatio3 1;
BA_ "SPN" SG_ 3221225472 TransGearRatio3 1259;
BA_ "SigType" SG_ 3221225472 EngTorqueLimit2Trans 1;
BA_ "SPN" SG_ 3221225472 EngTorqueLimit2Trans 1258;
BA_ "SigType" SG_ 3221225472 TransGearRatio2 1;
BA_ "SPN" SG_ 3221225472 TransGearRatio2 1257;
BA_ "SigType" SG_ 3221225472 EngTorqueLimit1Trans 1;
BA_ "SPN" SG_ 3221225472 EngTorqueLimit1Trans 1256;
BA_ "SigType" SG_ 3221225472 TransGearRatio1 1;
BA_ "SPN" SG_ 3221225472 TransGearRatio1 1255;
BA_ "SPN" SG_ 3221225472 EngTorqueLimitFeature 1632;
BA_ "SigType" SG_ 3221225472 TorqueLimitingFeatureStatus 5;
BA_ "SPN" SG_ 3221225472 TorqueLimitingFeatureStatus 1254;
BA_ "SigType" SG_ 3221225472 CalibRecordDurationTime 1;
BA_ "SPN" SG_ 3221225472 CalibRecordDurationTime 1253;
BA_ "SigType" SG_ 3221225472 CalibRecordStartYear 1;
BA_ "SPN" SG_ 3221225472 CalibRecordStartYear 1252;
BA_ "SigType" SG_ 3221225472 CalibRecordStartDay 1;
BA_ "GenSigStartValue" SG_ 3221225472 CalibRecordStartDay 1;
BA_ "SPN" SG_ 3221225472 CalibRecordStartDay 1251;
BA_ "SigType" SG_ 3221225472 CalibRecordStartMonth 1;
BA_ "GenSigStartValue" SG_ 3221225472 CalibRecordStartMonth 1;
BA_ "SPN" SG_ 3221225472 CalibRecordStartMonth 1250;
BA_ "SigType" SG_ 3221225472 EngPeakTorque2 1;
BA_ "SPN" SG_ 3221225472 EngPeakTorque2 1249;
BA_ "SigType" SG_ 3221225472 EngPeakTorque1 1;
BA_ "SPN" SG_ 3221225472 EngPeakTorque1 1248;
BA_ "SigType" SG_ 3221225472 EngPower 1;
BA_ "SPN" SG_ 3221225472 EngPower 1247;
BA_ "SigType" SG_ 3221225472 NumberOfEngTorqueHistoryRecords 1;
BA_ "SPN" SG_ 3221225472 NumberOfEngTorqueHistoryRecords 1246;
BA_ "SPN" SG_ 3221225472 RolloverSensorType 4934;
BA_ "SPN" SG_ 3221225472 RearCollisionSensor4Type 4933;
BA_ "SPN" SG_ 3221225472 RearCollisionSensor3Type 4932;
BA_ "SPN" SG_ 3221225472 RearCollisionSensor2Type 4931;
BA_ "SPN" SG_ 3221225472 RearCollisionSensor1Type 4930;
BA_ "SPN" SG_ 3221225472 SideCollisionSensorRearRightType 4929;
BA_ "SPN" SG_ 3221225472 SdCllisionSensorMidRearRightType 4928;
BA_ "SPN" SG_ 3221225472 SdCllsionSensorMidFrontRightType 4927;
BA_ "SPN" SG_ 3221225472 SdeCollisionSensorFrontRightType 4926;
BA_ "SPN" SG_ 3221225472 SideCollisionSensorRearLeftType 4925;
BA_ "SPN" SG_ 3221225472 SdCollisionSensorMidRearLeftType 4924;
BA_ "SPN" SG_ 3221225472 SdCllisionSensorMidFrontLeftType 4923;
BA_ "SPN" SG_ 3221225472 SideCollisionSensorFrontLeftType 4922;
BA_ "SPN" SG_ 3221225472 FrontalCollisionSensor4Type 4921;
BA_ "SPN" SG_ 3221225472 FrontalCollisionSensor3Type 4920;
BA_ "SPN" SG_ 3221225472 FrontalCollisionSensor2Type 4919;
BA_ "SPN" SG_ 3221225472 FrontalCollisionSensor1Type 4918;
BA_ "SigType" SG_ 3221225472 DPFAvgDistBetweenActiveRegens 1;
BA_ "SPN" SG_ 3221225472 DPFAvgDistBetweenActiveRegens 5827;
BA_ "SigType" SG_ 3221225472 DPFAvgTimeBetweenActiveRegens 1;
BA_ "SPN" SG_ 3221225472 DPFAvgTimeBetweenActiveRegens 5454;
BA_ "SigType" SG_ 3221225472 DPFTotalNumOfActiveRegenManReq 1;
BA_ "SPN" SG_ 3221225472 DPFTotalNumOfActiveRegenManReq 3728;
BA_ "SigType" SG_ 3221225472 DPFTotalNumOfActiveRegenInhReq 1;
BA_ "SPN" SG_ 3221225472 DPFTotalNumOfActiveRegenInhReq 3727;
BA_ "SigType" SG_ 3221225472 DPFTotalNumOfPassiveRegens 1;
BA_ "SPN" SG_ 3221225472 DPFTotalNumOfPassiveRegens 3726;
BA_ "SigType" SG_ 3221225472 DPFTotalPassiveRegenTime 1;
BA_ "SPN" SG_ 3221225472 DPFTotalPassiveRegenTime 3725;
BA_ "SigType" SG_ 3221225472 TotalNumOfActiveRegens 1;
BA_ "SPN" SG_ 3221225472 TotalNumOfActiveRegens 3525;
BA_ "SigType" SG_ 3221225472 TotalDisdTime 1;
BA_ "SPN" SG_ 3221225472 TotalDisdTime 3524;
BA_ "SigType" SG_ 3221225472 TotalRegenTime 1;
BA_ "SPN" SG_ 3221225472 TotalRegenTime 3523;
BA_ "SigType" SG_ 3221225472 TotalFuelUsed 1;
BA_ "SPN" SG_ 3221225472 TotalFuelUsed 3522;
BA_ "SigType" SG_ 3221225472 DPFAvgDistBetweenActiveRegens 1;
BA_ "SPN" SG_ 3221225472 DPFAvgDistBetweenActiveRegens 5828;
BA_ "SigType" SG_ 3221225472 DPFAvgTimeBetweenActiveRegens 1;
BA_ "SPN" SG_ 3221225472 DPFAvgTimeBetweenActiveRegens 5455;
BA_ "SigType" SG_ 3221225472 DPFTotalNumOfActiveRegenManReq 1;
BA_ "SPN" SG_ 3221225472 DPFTotalNumOfActiveRegenManReq 3732;
BA_ "SigType" SG_ 3221225472 DPFTotalNumOfActiveRegenInhReq 1;
BA_ "SPN" SG_ 3221225472 DPFTotalNumOfActiveRegenInhReq 3731;
BA_ "SigType" SG_ 3221225472 DPFTotalNumOfPassiveRegens 1;
BA_ "SPN" SG_ 3221225472 DPFTotalNumOfPassiveRegens 3730;
BA_ "SigType" SG_ 3221225472 DPFTotalPassiveRegenTime 1;
BA_ "SPN" SG_ 3221225472 DPFTotalPassiveRegenTime 3729;
BA_ "SigType" SG_ 3221225472 TotalNumOfActiveRegens 1;
BA_ "SPN" SG_ 3221225472 TotalNumOfActiveRegens 3529;
BA_ "SigType" SG_ 3221225472 TotalDisdTime 1;
BA_ "SPN" SG_ 3221225472 TotalDisdTime 3528;
BA_ "SigType" SG_ 3221225472 TotalRegenTime 1;
BA_ "SPN" SG_ 3221225472 TotalRegenTime 3527;
BA_ "SigType" SG_ 3221225472 TotalFuelUsed 1;
BA_ "SPN" SG_ 3221225472 TotalFuelUsed 3526;
BA_ "SigType" SG_ 2566658558 TotalHaulCycleCount 1;
BA_ "SPN" SG_ 2566658558 TotalHaulCycleCount 7700;
BA_ "SigType" SG_ 2566658558 TotalDeliveredPayloadWeight 1;
BA_ "SPN" SG_ 2566658558 TotalDeliveredPayloadWeight 7699;
BA_ "SigType" SG_ 2566658302 TotalPayloadTransactionCount 1;
BA_ "SPN" SG_ 2566658302 TotalPayloadTransactionCount 7701;
BA_ "SPN" SG_ 2499548158 RightRearCabDoorLatchPos 7726;
BA_ "SPN" SG_ 2499548158 LeftRearCabDoorLatchPos 7725;
BA_ "SPN" SG_ 2499548158 RightFrontCabDoorLatchPos 7724;
BA_ "SPN" SG_ 2499548158 LeftFrontCabDoorLatchPos 7723;
BA_ "SigType" SG_ 2499547902 MirrorRight2HeatCmd 5;
BA_ "SPN" SG_ 2499547902 MirrorRight2HeatCmd 7744;
BA_ "SigType" SG_ 2499547902 MirrorLeft2HeatCmd 5;
BA_ "SPN" SG_ 2499547902 MirrorLeft2HeatCmd 7743;
BA_ "SigType" SG_ 2499547902 MirrorRight1HeatCmd 5;
BA_ "SPN" SG_ 2499547902 MirrorRight1HeatCmd 7742;
BA_ "SigType" SG_ 2499547902 MirrorLeft1HeatCmd 5;
BA_ "SPN" SG_ 2499547902 MirrorLeft1HeatCmd 7741;
BA_ "SigType" SG_ 2499547902 MirrorRight2VerticalCmd 5;
BA_ "SPN" SG_ 2499547902 MirrorRight2VerticalCmd 7740;
BA_ "SigType" SG_ 2499547902 MirrorRight2HorizontalCmd 5;
BA_ "SPN" SG_ 2499547902 MirrorRight2HorizontalCmd 7739;
BA_ "SigType" SG_ 2499547902 MirrorLeft2VerticalCmd 5;
BA_ "SPN" SG_ 2499547902 MirrorLeft2VerticalCmd 7738;
BA_ "SigType" SG_ 2499547902 MirrorLeft2HorizontalCmd 5;
BA_ "SPN" SG_ 2499547902 MirrorLeft2HorizontalCmd 7737;
BA_ "SigType" SG_ 2499547902 MirrorRight1VerticalCmd 5;
BA_ "SPN" SG_ 2499547902 MirrorRight1VerticalCmd 7736;
BA_ "SigType" SG_ 2499547902 MirrorRight1HorizontalCmd 5;
BA_ "SPN" SG_ 2499547902 MirrorRight1HorizontalCmd 7735;
BA_ "SigType" SG_ 2499547902 MirrorLeft1VerticalCmd 5;
BA_ "SPN" SG_ 2499547902 MirrorLeft1VerticalCmd 7734;
BA_ "SigType" SG_ 2499547902 MirrorLeft1HorizontalCmd 5;
BA_ "SPN" SG_ 2499547902 MirrorLeft1HorizontalCmd 7733;
BA_ "SPN" SG_ 2499547902 RightRearWindowPosCmd 7732;
BA_ "SPN" SG_ 2499547902 LeftRearWindowPosCmd 7731;
BA_ "SPN" SG_ 2499547902 RightFrontWindowPosCmd 7730;
BA_ "SPN" SG_ 2499547902 LeftFrontWindowPosCmd 7729;
BA_ "SPN" SG_ 2499547902 RemoteCabDoorLockReq 7728;
BA_ "SPN" SG_ 2499547902 DoorsLockActCmd 7727;
BA_ "SigType" SG_ 2566656510 EngTotalGasIdleFuelVolumeUsed 1;
BA_ "SPN" SG_ 2566656510 EngTotalGasIdleFuelVolumeUsed 7456;
BA_ "SigType" SG_ 2566656510 EngTotalGasFuelVolumeUsed 1;
BA_ "SPN" SG_ 2566656510 EngTotalGasFuelVolumeUsed 7455;
BA_ "SPN" SG_ 2431710718 Checksum 7758;
BA_ "SPN" SG_ 2431710718 MessageCounter 7757;
BA_ "SigType" SG_ 2431710718 AutomaticEngStartConsentSummary 5;
BA_ "SPN" SG_ 2431710718 AutomaticEngStartConsentSummary 7756;
BA_ "SigType" SG_ 2431710718 OpEngStartConsentSummary 5;
BA_ "SPN" SG_ 2431710718 OpEngStartConsentSummary 7755;
BA_ "SPN" SG_ 2431710718 ReqLatchStatus 7754;
BA_ "SPN" SG_ 2431710718 StarterCmd 7753;
BA_ "SigType" SG_ 2431710718 CtrlMessageRate 5;
BA_ "SPN" SG_ 2431710718 CtrlMessageRate 7752;
BA_ "SPN" SG_ 2431708670 Checksum 7751;
BA_ "SPN" SG_ 2431708670 MessageCounter 7750;
BA_ "SPN" SG_ 2431708670 Starter2Feedback 7749;
BA_ "SPN" SG_ 2431708670 Starter1Feedback 7748;
BA_ "SigType" SG_ 2431708670 AbortReq 5;
BA_ "SPN" SG_ 2431708670 AbortReq 7747;
BA_ "SPN" SG_ 2431708670 Consent 7746;
BA_ "SigType" SG_ 2431708670 Req 5;
BA_ "SPN" SG_ 2431708670 Req 7745;
BA_ "SigType" SG_ 2566661118 EngTotalDieselFuelDemand 1;
BA_ "SPN" SG_ 2566661118 EngTotalDieselFuelDemand 7597;
BA_ "SigType" SG_ 2633769726 TotalEngEnergy 1;
BA_ "SPN" SG_ 2633769726 TotalEngEnergy 7608;
BA_ "SPN" SG_ 2565926142 O2Snsr2PreliminaryFMI 7692;
BA_ "SPN" SG_ 2565926142 NOxSnsr2SelfDiagStatus 7691;
BA_ "SPN" SG_ 2565926142 NOxSnsr2PreliminaryFMI 7690;
BA_ "SigType" SG_ 2565926142 GasSnsr2HtrCtrl 5;
BA_ "SPN" SG_ 2565926142 GasSnsr2HtrCtrl 7689;
BA_ "SPN" SG_ 2565926142 GasSnsr2HtrPreliminaryFMI 7688;
BA_ "SigType" SG_ 2565926142 WRPercentO22ReadingStable 5;
BA_ "SPN" SG_ 2565926142 WRPercentO22ReadingStable 7687;
BA_ "SigType" SG_ 2565926142 NOx2ReadingStable 5;
BA_ "SPN" SG_ 2565926142 NOx2ReadingStable 7686;
BA_ "SigType" SG_ 2565926142 GasSnsr2AtTemp 5;
BA_ "SPN" SG_ 2565926142 GasSnsr2AtTemp 7685;
BA_ "SigType" SG_ 2565926142 GasSnsr2PwrInRange 5;
BA_ "SPN" SG_ 2565926142 GasSnsr2PwrInRange 7684;
BA_ "SigType" SG_ 2565926142 PercentO22 1;
BA_ "SPN" SG_ 2565926142 PercentO22 7683;
BA_ "SigType" SG_ 2565926142 NOx2 1;
BA_ "SPN" SG_ 2565926142 NOx2 7682;
BA_ "SPN" SG_ 2565925886 O2Snsr2PreliminaryFMI 7681;
BA_ "SPN" SG_ 2565925886 NOxSnsr2SelfDiagStatus 7680;
BA_ "SPN" SG_ 2565925886 SCRInNOxSnsr2PreliminaryFMI 7679;
BA_ "SigType" SG_ 2565925886 GasSnsr2HtrCtrl 5;
BA_ "SPN" SG_ 2565925886 GasSnsr2HtrCtrl 7678;
BA_ "SPN" SG_ 2565925886 GasSnsr2HtrPreliminaryFMI 7677;
BA_ "SigType" SG_ 2565925886 WRPercentO22ReadingStable 5;
BA_ "SPN" SG_ 2565925886 WRPercentO22ReadingStable 7676;
BA_ "SigType" SG_ 2565925886 SCRInNOx2ReadingStable 5;
BA_ "SPN" SG_ 2565925886 SCRInNOx2ReadingStable 7675;
BA_ "SigType" SG_ 2565925886 GasSnsr2AtTemp 5;
BA_ "SPN" SG_ 2565925886 GasSnsr2AtTemp 7674;
BA_ "SigType" SG_ 2565925886 GasSnsr2PwrInRange 5;
BA_ "SPN" SG_ 2565925886 GasSnsr2PwrInRange 7673;
BA_ "SigType" SG_ 2565925886 PercentO22 1;
BA_ "SPN" SG_ 2565925886 PercentO22 7672;
BA_ "SigType" SG_ 2565925886 SCRInNOx2 1;
BA_ "SPN" SG_ 2565925886 SCRInNOx2 7671;
VAL_ 3221225472 TirePressThresholdDetection 7 "Not available" 6 "Error indicator" 5 "Not defined" 4 "Extreme under pressure" 3 "Under pressure" 2 "No warning pressure" 1 "Over pressure" 0 "Extreme over pressure" ;
VAL_ 3221225472 CTIWheelEndElectricalFault 3 "Not Supported" 2 "Error" 1 "Not Defined" 0 "Ok  No Fault" ;
VAL_ 3221225472 CTITireStatus 3 "Not Supported" 2 "Error" 1 "Tire leak detected" 0 "Ok no fault" ;
VAL_ 3221225472 CTIWheelSensorStatus 3 "Not Supported" 2 "Not Defined" 1 "On tire is polled" 0 "Off / isolated from CTI Pressure Controller" ;
VAL_ 3221225472 EngTurningGearEngaged 1 "Engaged" 0 "Not engaged" 3 "Not available" 2 "Error" ;
VAL_ 3221225472 RegenSt 15 "Not Available" 3 "Regeneration is active and has been initiated due to time based conditions" 2 "Regeneration is active and has been initiated because of sensor conditions" 1 "Regneration is active and has been initiated by request via SPN 6783" 0 "Regeneration is not active" ;
VAL_ 3221225472 RegenStatus 3 "Not available" 2 "Error indicator" 1 "Active" 0 "Inactive" ;
VAL_ 3221225472 HtrSt 3 "Heater is off" 2 "Heater is in ramp up mode" 1 "Heater is being held at a specified level" 0 "Heater is in closed loop control" ;
VAL_ 3221225472 PwrSupply 3 "Unavailable" 2 "Error" 1 "On" 0 "Off" ;
VAL_ 3221225472 DetectionStatus 15 "Not supported" 8 "Halt particulate matter detection" 7 "Sensor regeneration did not complete due to system parameters out of range" 6 "Relearning particulate sensor resistance after particulate sensor regeneration" 5 "Heater diagnostics test" 4 "Cooling after particulate sensor regeneration" 3 "Heater is active for particulate sensor regeneration" 2 "Particulate matter detection" 1 "Waiting for dew point" 0 "Initialization for particulate matter detection" ;
VAL_ 3221225472 HtrPwrSupplyDiagnosticStatus 7 "Not Available" 3 "Enable or pause conditions have allowed tests to execute this power cycle" 2 "Enable or pause conditions have allowed tests to execute this power cycle" 1 "Tests supported but not completed this power cycle" 0 "Tests monitored continuously" ;
VAL_ 3221225472 PwrSupplyDiagnosticStatus 7 "Not Available" 3 "Enable or pause conditions have allowed tests to execute this power cycle" 2 "Enable or pause conditions have allowed tests to execute this power cycle" 1 "Tests supported but not completed this power cycle" 0 "Tests monitored continuously" ;
VAL_ 3221225472 InputDiagnosticStatus 7 "Not Available" 3 "Enable or pause conditions have allowed tests to execute this power cycle" 2 "Enable or pause conditions have allowed tests to execute this power cycle" 1 "Tests supported but not completed this power cycle" 0 "Tests monitored continuously" ;
VAL_ 3221225472 HtrLowSideDriverDiagnosticStatus 7 "Not Available" 3 "Enable or pause conditions have allowed tests to execute this power cycle" 2 "Enable or pause conditions have allowed tests to execute this power cycle" 1 "Tests supported but not completed this power cycle" 0 "Tests monitored continuously" ;
VAL_ 3221225472 HtrHiSideDriverDiagnosticStatus 7 "Not Available" 3 "Enable or pause conditions have allowed tests to execute this power cycle" 2 "Enable or pause conditions have allowed tests to execute this power cycle" 1 "Tests supported but not completed this power cycle" 0 "Tests monitored continuously" ;
VAL_ 3221225472 Dewpoint 3 "Not available" 2 "SAE reserved" 1 "Dewpoint has been reached" 0 "Dewpoint has not been reached" ;
VAL_ 3221225472 RegenReq 3 "Not available" 2 "SAE reserved" 1 "Regeneration requested" 0 "Regeneration not requested" ;
VAL_ 3221225472 ShutdownReq 3 "Not available" 2 "SAE reserved" 1 "Shutdown request active" 0 "Shutdown request not active" ;
VAL_ 3221225472 RqToPermitDEFDosingTestInjection 7 "don't care" 2 "urgent request to permit DEF Dosing Test Injection or test injection is running" 1 "request to permit DEF Dosing Test Injection or test injection is running" 0 "no request" ;
VAL_ 3221225472 RqToPermitDEFHydStiffnessCheck 3 "don't care" 2 "reserved" 1 "request to permit DEF hydraulic stiffness check or stiffness check is running" 0 "no request" ;
VAL_ 3221225472 ThermalManagementInhReq 3 "Not Available" 2 "Reserved for SAE assignment" 1 "Inhibit" 0 "Do not inhibit" ;
VAL_ 3221225472 DesulfationStatus 3 "Not available" 2 "Error indicator" 1 "Active" 0 "Inactive" ;
VAL_ 3221225472 FusedOutput29 3 "Take no action" 2 "Reserved" 1 "Output powered" 0 "Output not powered" ;
VAL_ 3221225472 FusedOutput30 3 "Take no action" 2 "Reserved" 1 "Output powered" 0 "Output not powered" ;
VAL_ 3221225472 FusedOutput31 3 "Take no action" 2 "Reserved" 1 "Output powered" 0 "Output not powered" ;
VAL_ 3221225472 FusedOutput32 3 "Take no action" 2 "Reserved" 1 "Output powered" 0 "Output not powered" ;
VAL_ 3221225472 FusedOutput25 3 "Take no action" 2 "Reserved" 1 "Output powered" 0 "Output not powered" ;
VAL_ 3221225472 FusedOutput26 3 "Take no action" 2 "Reserved" 1 "Output powered" 0 "Output not powered" ;
VAL_ 3221225472 FusedOutput27 3 "Take no action" 2 "Reserved" 1 "Output powered" 0 "Output not powered" ;
VAL_ 3221225472 FusedOutput28 3 "Take no action" 2 "Reserved" 1 "Output powered" 0 "Output not powered" ;
VAL_ 3221225472 FusedOutput21 3 "Take no action" 2 "Reserved" 1 "Output powered" 0 "Output not powered" ;
VAL_ 3221225472 FusedOutput22 3 "Take no action" 2 "Reserved" 1 "Output powered" 0 "Output not powered" ;
VAL_ 3221225472 FusedOutput23 3 "Take no action" 2 "Reserved" 1 "Output powered" 0 "Output not powered" ;
VAL_ 3221225472 FusedOutput24 3 "Take no action" 2 "Reserved" 1 "Output powered" 0 "Output not powered" ;
VAL_ 3221225472 FusedOutput17 3 "Take no action" 2 "Reserved" 1 "Output powered" 0 "Output not powered" ;
VAL_ 3221225472 FusedOutput18 3 "Take no action" 2 "Reserved" 1 "Output powered" 0 "Output not powered" ;
VAL_ 3221225472 FusedOutput19 3 "Take no action" 2 "Reserved" 1 "Output powered" 0 "Output not powered" ;
VAL_ 3221225472 FusedOutput20 3 "Take no action" 2 "Reserved" 1 "Output powered" 0 "Output not powered" ;
VAL_ 3221225472 FusedOutput13 3 "Take no action" 2 "Reserved" 1 "Output powered" 0 "Output not powered" ;
VAL_ 3221225472 FusedOutput14 3 "Take no action" 2 "Reserved" 1 "Output powered" 0 "Output not powered" ;
VAL_ 3221225472 FusedOutput15 3 "Take no action" 2 "Reserved" 1 "Output powered" 0 "Output not powered" ;
VAL_ 3221225472 FusedOutput16 3 "Take no action" 2 "Reserved" 1 "Output powered" 0 "Output not powered" ;
VAL_ 3221225472 FusedOutput9 3 "Take no action" 2 "Reserved" 1 "Output powered" 0 "Output not powered" ;
VAL_ 3221225472 FusedOutput10 3 "Take no action" 2 "Reserved" 1 "Output powered" 0 "Output not powered" ;
VAL_ 3221225472 FusedOutput11 3 "Take no action" 2 "Reserved" 1 "Output powered" 0 "Output not powered" ;
VAL_ 3221225472 FusedOutput12 3 "Take no action" 2 "Reserved" 1 "Output powered" 0 "Output not powered" ;
VAL_ 3221225472 FusedOutput5 3 "Take no action" 2 "Reserved" 1 "Output powered" 0 "Output not powered" ;
VAL_ 3221225472 FusedOutput6 3 "Take no action" 2 "Reserved" 1 "Output powered" 0 "Output not powered" ;
VAL_ 3221225472 FusedOutput7 3 "Take no action" 2 "Reserved" 1 "Output powered" 0 "Output not powered" ;
VAL_ 3221225472 FusedOutput8 3 "Take no action" 2 "Reserved" 1 "Output powered" 0 "Output not powered" ;
VAL_ 3221225472 FusedOutput1 3 "Take no action" 2 "Reserved" 1 "Output powered" 0 "Output not powered" ;
VAL_ 3221225472 FusedOutput2 3 "Take no action" 2 "Reserved" 1 "Output powered" 0 "Output not powered" ;
VAL_ 3221225472 FusedOutput3 3 "Take no action" 2 "Reserved" 1 "Output powered" 0 "Output not powered" ;
VAL_ 3221225472 FusedOutput4 3 "Take no action" 2 "Reserved" 1 "Output powered" 0 "Output not powered" ;
VAL_ 3221225472 SwitchedOutput29 3 "Take no action" 2 "Reserved" 1 "Output on" 0 "Output off" ;
VAL_ 3221225472 SwitchedOutput30 3 "Take no action" 2 "Reserved" 1 "Output on" 0 "Output off" ;
VAL_ 3221225472 SwitchedOutput31 3 "Take no action" 2 "Reserved" 1 "Output on" 0 "Output off" ;
VAL_ 3221225472 SwitchedOutput32 3 "Take no action" 2 "Reserved" 1 "Output on" 0 "Output off" ;
VAL_ 3221225472 SwitchedOutput25 3 "Take no action" 2 "Reserved" 1 "Output on" 0 "Output off" ;
VAL_ 3221225472 SwitchedOutput26 3 "Take no action" 2 "Reserved" 1 "Output on" 0 "Output off" ;
VAL_ 3221225472 SwitchedOutput27 3 "Take no action" 2 "Reserved" 1 "Output on" 0 "Output off" ;
VAL_ 3221225472 SwitchedOutput28 3 "Take no action" 2 "Reserved" 1 "Output on" 0 "Output off" ;
VAL_ 3221225472 SwitchedOutput21 3 "Take no action" 2 "Reserved" 1 "Output on" 0 "Output off" ;
VAL_ 3221225472 SwitchedOutput22 3 "Take no action" 2 "Reserved" 1 "Output on" 0 "Output off" ;
VAL_ 3221225472 SwitchedOutput23 3 "Take no action" 2 "Reserved" 1 "Output on" 0 "Output off" ;
VAL_ 3221225472 SwitchedOutput24 3 "Take no action" 2 "Reserved" 1 "Output on" 0 "Output off" ;
VAL_ 3221225472 SwitchedOutput17 3 "Take no action" 2 "Reserved" 1 "Output on" 0 "Output off" ;
VAL_ 3221225472 SwitchedOutput18 3 "Take no action" 2 "Reserved" 1 "Output on" 0 "Output off" ;
VAL_ 3221225472 SwitchedOutput19 3 "Take no action" 2 "Reserved" 1 "Output on" 0 "Output off" ;
VAL_ 3221225472 SwitchedOutput20 3 "Take no action" 2 "Reserved" 1 "Output on" 0 "Output off" ;
VAL_ 3221225472 SwitchedOutput13 3 "Take no action" 2 "Reserved" 1 "Output on" 0 "Output off" ;
VAL_ 3221225472 SwitchedOutput14 3 "Take no action" 2 "Reserved" 1 "Output on" 0 "Output off" ;
VAL_ 3221225472 SwitchedOutput15 0 "Output off" 3 "Take no action" 2 "Reserved" 1 "Output on" ;
VAL_ 3221225472 SwitchedOutput16 3 "Take no action" 2 "Reserved" 1 "Output on" 0 "Output off" ;
VAL_ 3221225472 SwitchedOutput9 3 "Take no action" 2 "Reserved" 1 "Output on" 0 "Output off" ;
VAL_ 3221225472 SwitchedOutput10 3 "Take no action" 2 "Reserved" 1 "Output on" 0 "Output off" ;
VAL_ 3221225472 SwitchedOutput11 3 "Take no action" 2 "Reserved" 1 "Output on" 0 "Output off" ;
VAL_ 3221225472 SwitchedOutput12 3 "Take no action" 2 "Reserved" 1 "Output on" 0 "Output off" ;
VAL_ 3221225472 SwitchedOutput5 3 "Take no action" 2 "Reserved" 1 "Output on" 0 "Output off" ;
VAL_ 3221225472 SwitchedOutput6 3 "Take no action" 2 "Reserved" 1 "Output on" 0 "Output off" ;
VAL_ 3221225472 SwitchedOutput7 3 "Take no action" 2 "Reserved" 1 "Output on" 0 "Output off" ;
VAL_ 3221225472 SwitchedOutput8 3 "Take no action" 2 "Reserved" 1 "Output on" 0 "Output off" ;
VAL_ 3221225472 SwitchedOutput1 3 "Take no action" 2 "Reserved" 1 "Output on" 0 "Output off" ;
VAL_ 3221225472 SwitchedOutput2 3 "Take no action" 2 "Reserved" 1 "Output on" 0 "Output off" ;
VAL_ 3221225472 SwitchedOutput3 3 "Take no action" 2 "Reserved" 1 "Output on" 0 "Output off" ;
VAL_ 3221225472 SwitchedOutput4 3 "Take no action" 2 "Reserved" 1 "Output on" 0 "Output off" ;
VAL_ 3221225472 SwitchedPowerOutput18Cmd 3 "Take no action" 2 "Reserved" 1 "Output on" 0 "Output off" ;
VAL_ 3221225472 SwitchedPowerOutput19Cmd 3 "Take no action" 2 "Reserved" 1 "Output on" 0 "Output off" ;
VAL_ 3221225472 SwitchedPowerOutput20Cmd 3 "Take no action" 2 "Reserved" 1 "Output on" 0 "Output off" ;
VAL_ 3221225472 SwitchedPowerOutput13Cmd 3 "Take no action" 2 "Reserved" 1 "Output on" 0 "Output off" ;
VAL_ 3221225472 SwitchedPowerOutput14Cmd 3 "Take no action" 2 "Reserved" 1 "Output on" 0 "Output off" ;
VAL_ 3221225472 SwitchedPowerOutput15Cmd 3 "Take no action" 2 "Reserved" 1 "Output on" 0 "Output off" ;
VAL_ 3221225472 SwitchedPowerOutput16Cmd 3 "Take no action" 2 "Reserved" 1 "Output on" 0 "Output off" ;
VAL_ 3221225472 SwitchedPowerOutput9Cmd 3 "Take no action" 2 "Reserved" 1 "Output on" 0 "Output off" ;
VAL_ 3221225472 SwitchedPowerOutput10Cmd 3 "Take no action" 2 "Reserved" 1 "Output on" 0 "Output off" ;
VAL_ 3221225472 SwitchedPowerOutput29Cmd 3 "Take no action" 2 "Reserved" 1 "Output on" 0 "Output off" ;
VAL_ 3221225472 SwitchedPowerOutput30Cmd 3 "Take no action" 2 "Reserved" 1 "Output on" 0 "Output off" ;
VAL_ 3221225472 SwitchedPowerOutput31Cmd 3 "Take no action" 2 "Reserved" 1 "Output on" 0 "Output off" ;
VAL_ 3221225472 SwitchedPowerOutput32Cmd 3 "Take no action" 2 "Reserved" 1 "Output on" 0 "Output off" ;
VAL_ 3221225472 SwitchedPowerOutput25Cmd 3 "Take no action" 2 "Reserved" 1 "Output on" 0 "Output off" ;
VAL_ 3221225472 SwitchedPowerOutput26Cmd 3 "Take no action" 2 "Reserved" 1 "Output on" 0 "Output off" ;
VAL_ 3221225472 SwitchedPowerOutput27Cmd 3 "Take no action" 2 "Reserved" 1 "Output on" 0 "Output off" ;
VAL_ 3221225472 SwitchedPowerOutput28Cmd 3 "Take no action" 2 "Reserved" 1 "Output on" 0 "Output off" ;
VAL_ 3221225472 SwitchedPowerOutput21Cmd 3 "Take no action" 2 "Reserved" 1 "Output on" 0 "Output off" ;
VAL_ 3221225472 SwitchedPowerOutput22Cmd 3 "Take no action" 2 "Reserved" 1 "Output on" 0 "Output off" ;
VAL_ 3221225472 SwitchedPowerOutput23Cmd 3 "Take no action" 2 "Reserved" 1 "Output on" 0 "Output off" ;
VAL_ 3221225472 SwitchedPowerOutput24Cmd 3 "Take no action" 2 "Reserved" 1 "Output on" 0 "Output off" ;
VAL_ 3221225472 SwitchedPowerOutput17Cmd 3 "Take no action" 2 "Reserved" 1 "Output on" 0 "Output off" ;
VAL_ 3221225472 SwitchedPowerOutput11Cmd 3 "Take no action" 2 "Reserved" 1 "Output on" 0 "Output off" ;
VAL_ 3221225472 SwitchedPowerOutput12Cmd 3 "Take no action" 2 "Reserved" 1 "Output on" 0 "Output off" ;
VAL_ 3221225472 SwitchedPowerOutput5Cmd 3 "Take no action" 2 "Reserved" 1 "Output on" 0 "Output off" ;
VAL_ 3221225472 SwitchedPowerOutput6Cmd 3 "Take no action" 2 "Reserved" 1 "Output on" 0 "Output off" ;
VAL_ 3221225472 SwitchedPowerOutput7Cmd 3 "Take no action" 2 "Reserved" 1 "Output on" 0 "Output off" ;
VAL_ 3221225472 SwitchedPowerOutput8Cmd 3 "Take no action" 2 "Reserved" 1 "Output on" 0 "Output off" ;
VAL_ 3221225472 SwitchedPowerOutput1Cmd 3 "Take no action" 2 "Reserved" 1 "Output on" 0 "Output off" ;
VAL_ 3221225472 SwitchedPowerOutput2Cmd 3 "Take no action" 2 "Reserved" 1 "Output on" 0 "Output off" ;
VAL_ 3221225472 SwitchedPowerOutput3Cmd 3 "Take no action" 2 "Reserved" 1 "Output on" 0 "Output off" ;
VAL_ 3221225472 SwitchedPowerOutput4Cmd 3 "Take no action" 2 "Reserved" 1 "Output on" 0 "Output off" ;
VAL_ 3221225472 EngTorqueLimitFeature 7 "Not available" 4 "Current torque rating" 3 "Previous torque rating" 2 "First torque rating" 1 "Highest torque rating" 0 "Reserved" ;
VAL_ 3221225472 TorqueLimitingFeatureStatus 3 "Not available" 2 "Error" 1 "Enabled" 0 "Disabled" ;
VAL_ 3221225472 RolloverSensorType 15 "not available" 14 "Error" 7 "optical sensor" 6 "lidar sensor" 5 "radar sensor" 4 "fiber-optic sensor" 3 "sonic sensor" 2 "rollrate sensor" 1 "pressure sensor" 0 "acceleration sensor" ;
VAL_ 3221225472 RearCollisionSensor4Type 15 "not available" 14 "Error" 7 "optical sensor" 6 "lidar sensor" 5 "radar sensor" 4 "fiber-optic sensor" 3 "sonic sensor" 2 "rollrate sensor" 1 "pressure sensor" 0 "acceleration sensor" ;
VAL_ 3221225472 RearCollisionSensor3Type 15 "not available" 14 "Error" 7 "optical sensor" 6 "lidar sensor" 5 "radar sensor" 4 "fiber-optic sensor" 3 "sonic sensor" 2 "rollrate sensor" 1 "pressure sensor" 0 "acceleration sensor" ;
VAL_ 3221225472 RearCollisionSensor2Type 15 "not available" 14 "Error" 7 "optical sensor" 6 "lidar sensor" 5 "radar sensor" 4 "fiber-optic sensor" 3 "sonic sensor" 2 "rollrate sensor" 1 "pressure sensor" 0 "acceleration sensor" ;
VAL_ 3221225472 RearCollisionSensor1Type 15 "not available" 14 "Error" 7 "optical sensor" 6 "lidar sensor" 5 "radar sensor" 4 "fiber-optic sensor" 3 "sonic sensor" 2 "rollrate sensor" 1 "pressure sensor" 0 "acceleration sensor" ;
VAL_ 3221225472 SideCollisionSensorRearRightType 15 "not available" 14 "Error" 7 "optical sensor" 6 "lidar sensor" 5 "radar sensor" 4 "fiber-optic sensor" 3 "sonic sensor" 2 "rollrate sensor" 1 "pressure sensor" 0 "acceleration sensor" ;
VAL_ 3221225472 SdCllisionSensorMidRearRightType 15 "not available" 14 "Error" 7 "optical sensor" 6 "lidar sensor" 5 "radar sensor" 4 "fiber-optic sensor" 3 "sonic sensor" 2 "rollrate sensor" 1 "pressure sensor" 0 "acceleration sensor" ;
VAL_ 3221225472 SdCllsionSensorMidFrontRightType 15 "not available" 14 "Error" 7 "optical sensor" 6 "lidar sensor" 5 "radar sensor" 4 "fiber-optic sensor" 3 "sonic sensor" 2 "rollrate sensor" 1 "pressure sensor" 0 "acceleration sensor" ;
VAL_ 3221225472 SdeCollisionSensorFrontRightType 15 "not available" 14 "Error" 7 "optical sensor" 6 "lidar sensor" 5 "radar sensor" 4 "fiber-optic sensor" 3 "sonic sensor" 2 "rollrate sensor" 1 "pressure sensor" 0 "acceleration sensor" ;
VAL_ 3221225472 SideCollisionSensorRearLeftType 15 "not available" 14 "Error" 7 "optical sensor" 6 "lidar sensor" 5 "radar sensor" 4 "fiber-optic sensor" 3 "sonic sensor" 2 "rollrate sensor" 1 "pressure sensor" 0 "acceleration sensor" ;
VAL_ 3221225472 SdCollisionSensorMidRearLeftType 15 "not available" 14 "Error" 7 "optical sensor" 6 "lidar sensor" 5 "radar sensor" 4 "fiber-optic sensor" 3 "sonic sensor" 2 "rollrate sensor" 1 "pressure sensor" 0 "acceleration sensor" ;
VAL_ 3221225472 SdCllisionSensorMidFrontLeftType 15 "not available" 14 "Error" 7 "optical sensor" 6 "lidar sensor" 5 "radar sensor" 4 "fiber-optic sensor" 3 "sonic sensor" 2 "rollrate sensor" 1 "pressure sensor" 0 "acceleration sensor" ;
VAL_ 3221225472 SideCollisionSensorFrontLeftType 15 "not available" 14 "Error" 7 "optical sensor" 6 "lidar sensor" 5 "radar sensor" 4 "fiber-optic sensor" 3 "sonic sensor" 2 "rollrate sensor" 1 "pressure sensor" 0 "acceleration sensor" ;
VAL_ 3221225472 FrontalCollisionSensor4Type 15 "not available" 14 "Error" 7 "optical sensor" 6 "lidar sensor" 5 "radar sensor" 4 "fiber-optic sensor" 3 "sonic sensor" 2 "rollrate sensor" 1 "pressure sensor" 0 "acceleration sensor" ;
VAL_ 3221225472 FrontalCollisionSensor3Type 15 "not available" 14 "Error" 7 "optical sensor" 6 "lidar sensor" 5 "radar sensor" 4 "fiber-optic sensor" 3 "sonic sensor" 2 "rollrate sensor" 1 "pressure sensor" 0 "acceleration sensor" ;
VAL_ 3221225472 FrontalCollisionSensor2Type 15 "not available" 14 "Error" 7 "optical sensor" 6 "lidar sensor" 5 "radar sensor" 4 "fiber-optic sensor" 3 "sonic sensor" 2 "rollrate sensor" 1 "pressure sensor" 0 "acceleration sensor" ;
VAL_ 3221225472 FrontalCollisionSensor1Type 15 "not available" 14 "Error" 7 "optical sensor" 6 "lidar sensor" 5 "radar sensor" 4 "fiber-optic sensor" 3 "sonic sensor" 2 "rollrate sensor" 1 "pressure sensor" 0 "acceleration sensor" ;
VAL_ 2499548158 RightRearCabDoorLatchPos 7 "Not Available" 6 "Error" 5 "Reserved" 4 "Reserved" 3 "Reserved" 2 "Door Latch Ajar" 1 "Door Latch Fully Closed/Latched" 0 "Door Latch Open" ;
VAL_ 2499548158 LeftRearCabDoorLatchPos 7 "Not Available" 6 "Error" 5 "Reserved" 4 "Reserved" 3 "Reserved" 2 "Door Latch Ajar" 1 "Door Latch Fully Closed/Latched" 0 "Door Latch Open" ;
VAL_ 2499548158 RightFrontCabDoorLatchPos 7 "Not Available" 6 "Error" 5 "Reserved" 4 "Reserved" 3 "Reserved" 2 "Door Latch Ajar" 1 "Door Latch Fully Closed/Latched" 0 "Door Latch Open" ;
VAL_ 2499548158 LeftFrontCabDoorLatchPos 7 "Not Available" 6 "Error" 5 "Reserved" 4 "Reserved" 3 "Reserved" 2 "Door Latch Ajar" 1 "Door Latch Fully Closed/Latched" 0 "Door Latch Open" ;
VAL_ 2499547902 MirrorRight2HeatCmd 3 "Take no action" 2 "Reserved" 1 "Mirror heat on" 0 "Mirror heat off" ;
VAL_ 2499547902 MirrorLeft2HeatCmd 3 "Take no action" 2 "Reserved" 1 "Mirror heat on" 0 "Mirror heat off" ;
VAL_ 2499547902 MirrorRight1HeatCmd 3 "Take no action" 2 "Reserved" 1 "Mirror heat on" 0 "Mirror heat off" ;
VAL_ 2499547902 MirrorLeft1HeatCmd 3 "Take no action" 2 "Reserved" 1 "Mirror heat on" 0 "Mirror heat off" ;
VAL_ 2499547902 MirrorRight2VerticalCmd 3 "Take no action" 2 "Reserved" 1 "Move down" 0 "Move up" ;
VAL_ 2499547902 MirrorRight2HorizontalCmd 3 "Take no action" 2 "Reserved" 1 "Move right" 0 "Move left" ;
VAL_ 2499547902 MirrorLeft2VerticalCmd 3 "Take no action" 2 "Reserved" 1 "Move down" 0 "Move up" ;
VAL_ 2499547902 MirrorLeft2HorizontalCmd 3 "Take no action" 2 "Reserved" 1 "Move right" 0 "Move left" ;
VAL_ 2499547902 MirrorRight1VerticalCmd 3 "Take no action" 2 "Reserved" 1 "Move down" 0 "Move up" ;
VAL_ 2499547902 MirrorRight1HorizontalCmd 3 "Take no action" 2 "Reserved" 1 "Move right" 0 "Move left" ;
VAL_ 2499547902 MirrorLeft1VerticalCmd 3 "Take no action" 2 "Reserved" 1 "Move down" 0 "Move up" ;
VAL_ 2499547902 MirrorLeft1HorizontalCmd 3 "Take no action" 2 "Reserved" 1 "Move right" 0 "Move left" ;
VAL_ 2499547902 RightRearWindowPosCmd 7 "Take no action" 6 "Reserved" 5 "Reserved" 4 "Reserved" 3 "Window auto down" 2 "Window auto up" 1 "Window move down" 0 "Window move up" ;
VAL_ 2499547902 LeftRearWindowPosCmd 7 "Take no action" 6 "Reserved" 5 "Reserved" 4 "Reserved" 3 "Window auto down" 2 "Window auto up" 1 "Window move down" 0 "Window move up" ;
VAL_ 2499547902 RightFrontWindowPosCmd 7 "Take no action" 6 "Reserved" 5 "Reserved" 4 "Reserved" 3 "Window auto down" 2 "Window auto up" 1 "Window move down" 0 "Window move up" ;
VAL_ 2499547902 LeftFrontWindowPosCmd 7 "Take no action" 6 "Reserved" 5 "Reserved" 4 "Reserved" 3 "Window auto down" 2 "Window auto up" 1 "Window move down" 0 "Window move up" ;
VAL_ 2499547902 RemoteCabDoorLockReq 7 "Take no action" 6 "Reserved" 5 "Request lock all cab door latches" 4 "Request unlock all cab door latches" 3 "Request unlock right rear cab door latch" 2 "Request unlock left rear cab door latch" 1 "Request unlock right front cab door latch" 0 "Request unlock left front cab door latch" ;
VAL_ 2499547902 DoorsLockActCmd 7 "Take no action" 6 "Reserved" 5 "Lock all cab door latches" 4 "Unlock all cab door latches" 3 "Unlock right rear cab door latch" 2 "Unlock left rear cab door latch" 1 "Unlock right front cab door latch" 0 "Unlock left front cab door latch" ;
VAL_ 2431710718 AutomaticEngStartConsentSummary 3 "Not available" 2 "Error" 1 "Consent" 0 "No consent" ;
VAL_ 2431710718 OpEngStartConsentSummary 3 "Not available" 2 "Error" 1 "Consent" 0 "No consent" ;
VAL_ 2431710718 ReqLatchStatus 15 "Not available" 6 "Start request unlatched, start could not be completed because the starter command was not successful" 5 "Start request unlatched, start aborted due to abort request" 4 "Start request unlatched, consent not established within allowed time" 3 "Start request unlatched, start completed" 2 "Start request latched, consent confirmed" 1 "Start request latched, waiting for consent" 0 "Start request not received" ;
VAL_ 2431710718 StarterCmd 7 "Don’t care / Take no action" 3 "Command withdrawn" 2 "Command active for starter 2" 1 "Command active for starter 1" 0 "Command not active" ;
VAL_ 2431710718 CtrlMessageRate 3 "Not available" 2 "Reserved" 1 "Once every 250 ms or on change but no faster than 20 ms" 0 "Once every 20 ms" ;
VAL_ 2431708670 Starter2Feedback 7 "Not available" 4 "Starter command unlatched,  start aborted by starter controller" 3 "Starter command unlatched,  start abort command received from arbitrator" 2 "Starter command unlatched,  start completed" 1 "Starter command latched" 0 "Starter not commanded" ;
VAL_ 2431708670 Starter1Feedback 7 "Not available" 4 "Starter command unlatched,  start aborted by starter controller" 3 "Starter command unlatched,  start abort command received from arbitrator" 2 "Starter command unlatched,  start completed" 1 "Starter command latched" 0 "Starter not commanded" ;
VAL_ 2431708670 AbortReq 3 "Don’t care / Take no action" 2 "Reserved" 1 "Abort requested" 0 "Abort not requested" ;
VAL_ 2431708670 Consent 7 "Not available" 3 "Consent to both" 2 "Consent to automatic start only" 1 "Consent to operator-requested start only" 0 "No consent" ;
VAL_ 2431708670 Req 3 "Not available" 2 "Start requested,  automatic type" 1 "Start requested,  operator type" 0 "Start not requested" ;
VAL_ 2565926142 NOxSnsr2SelfDiagStatus 0 "Diagnosis not active" 7 "Not Supported" 4 "NOx Sensor ATO2 Self Diagnosis not possible" 3 "NOx Sensor ATO2 Self Diagnosis aborted" 2 "NOx Sensor ATO2 Self Diagnosis Result Complete" 1 "NOx Sensor ATO2 Self Diagnosis active flag" ;
VAL_ 2565926142 GasSnsr2HtrCtrl 3 "Heater off" 2 "Preheat 1" 1 "Preheat 2" 0 "Automatic" ;
VAL_ 2565926142 WRPercentO22ReadingStable 3 "Not available" 2 "Error" 1 "Stable" 0 "Not stable" ;
VAL_ 2565926142 NOx2ReadingStable 3 "Not available" 2 "Error" 1 "Stable" 0 "Not stable" ;
VAL_ 2565926142 GasSnsr2AtTemp 3 "Not available" 2 "Error" 1 "In range" 0 "Not in range" ;
VAL_ 2565926142 GasSnsr2PwrInRange 3 "Not available" 2 "Error" 1 "In range" 0 "Not in range" ;
VAL_ 2565925886 NOxSnsr2SelfDiagStatus 7 "Not Supported" 4 "NOx Sensor ATI2 Self Diagnosis not possible" 3 "NOx Sensor ATI2 Self Diagnosis aborted" 2 "NOx Sensor ATI2 Self Diagnosis Result Complete" 1 "NOx Sensor ATI2 Self Diagnosis active flag" 0 "Diagnosis not active" ;
VAL_ 2565925886 GasSnsr2HtrCtrl 3 "Heater off" 2 "Preheat 1" 1 "Preheat 2" 0 "Automatic" ;
VAL_ 2565925886 WRPercentO22ReadingStable 3 "Not available" 2 "Error" 1 "Stable" 0 "Not stable" ;
VAL_ 2565925886 SCRInNOx2ReadingStable 3 "Not available" 2 "Error" 1 "Stable" 0 "Not stable" ;
VAL_ 2565925886 GasSnsr2AtTemp 3 "Not available" 2 "Error" 1 "In range" 0 "Not in range" ;
VAL_ 2565925886 GasSnsr2PwrInRange 3 "Not available" 2 "Error" 1 "In range" 0 "Not in range" ;
